[part 2 of 5: package /Cluster]
AUTOSAR XML (schema 4-3-0)
package /Cluster  (continued)
  can cluster HCP5_CANFD01: baudrate=500000, protocol-name=CAN, protocol-version=2.0, bus-off-recovery={bor-counter-l-1-to-l-2=1, bor-time-l-1=0.05, bor-time-l-2=0.2}, can-fd-baudrate=2000000  (continued)
    can physical channel CHNL: comm-connectors=CN_HCP5_CANFD01  (continued)
      frame BMC_HV_06_SOK_XIX_HCP5_CANFD01: id 0x16A95516, from BMC_HV, frame-length=12, can-addressing-mode=EXTENDED, can-frame-rx-behavior=CAN-FD, can-frame-tx-behavior=CAN-FD
        secured i pdu BMC_HV_06_SOK_XIX_HCP5_CANFD01:
          length=12
          authentication-props=SecureCommunicationAuthenticationProps_XIX_32
          freshness-props=SecureCommunicationFreshnessProps
          payload=PT_BMC_HV_06
          secure-communication-props={auth-data-freshness-length=0, auth-data-freshness-start-position=0, auth-info-tx-length=32, authentication-build-attempts=1, authentication-retries=4, data-id=535, freshness-value-id=2, freshness-value-length=64, freshness-value-tx-length=0}
          use-as-cryptographic-i-pdu=false
      frame BMC_HV_07_SOK_XIX_HCP5_CANFD01: id 0x16A95532, from BMC_HV, frame-length=12, can-addressing-mode=EXTENDED, can-frame-rx-behavior=CAN-FD, can-frame-tx-behavior=CAN-FD
        secured i pdu BMC_HV_07_SOK_XIX_HCP5_CANFD01:
          length=12
          authentication-props=SecureCommunicationAuthenticationProps_XIX_32
          freshness-props=SecureCommunicationFreshnessProps
          payload=PT_BMC_HV_07
          secure-communication-props={auth-data-freshness-length=0, auth-data-freshness-start-position=0, auth-info-tx-length=32, authentication-build-attempts=1, authentication-retries=4, data-id=730, freshness-value-id=3, freshness-value-length=64, freshness-value-tx-length=0}
          use-as-cryptographic-i-pdu=false
      frame BMC_HV_08_SOK_XIX_HCP5_CANFD01: id 0x1A555631, from BMC_HV, frame-length=48, can-addressing-mode=EXTENDED, can-frame-rx-behavior=CAN-FD, can-frame-tx-behavior=CAN-FD
        secured i pdu BMC_HV_08_SOK_XIX_HCP5_CANFD01:
          length=48
          authentication-props=SecureCommunicationAuthenticationProps_XIX_32
          freshness-props=SecureCommunicationFreshnessProps
          payload=PT_BMC_HV_08
          secure-communication-props={auth-data-freshness-length=0, auth-data-freshness-start-position=0, auth-info-tx-length=32, authentication-build-attempts=1, authentication-retries=4, data-id=731, freshness-value-id=4, freshness-value-length=64, freshness-value-tx-length=0}
          use-as-cryptographic-i-pdu=false
      frame BMC_HV_09_SOK_XIX_HCP5_CANFD01: id 0x12DD5593, from BMC_HV, frame-length=20, can-addressing-mode=EXTENDED, can-frame-rx-behavior=CAN-FD, can-frame-tx-behavior=CAN-FD
        secured i pdu BMC_HV_09_SOK_XIX_HCP5_CANFD01:
          length=20
          authentication-props=SecureCommunicationAuthenticationProps_XIX_32
          freshness-props=SecureCommunicationFreshnessProps
          payload=PT_BMC_HV_09
          secure-communication-props={auth-data-freshness-length=0, auth-data-freshness-start-position=0, auth-info-tx-length=32, authentication-build-attempts=1, authentication-retries=4, data-id=810, freshness-value-id=5, freshness-value-length=64, freshness-value-tx-length=0}
          use-as-cryptographic-i-pdu=false
      frame BMC_HV_14_SOK_XIX_HCP5_CANFD01: id 0x12DD55C4, from BMC_HV, frame-length=16, can-addressing-mode=STANDARD, can-frame-rx-behavior=CAN-FD, can-frame-tx-behavior=CAN-FD
        secured i pdu BMC_HV_14_SOK_XIX_HCP5_CANFD01:
          length=16
          authentication-props=SecureCommunicationAuthenticationProps_XIX_32
          freshness-props=SecureCommunicationFreshnessProps
          payload=PT_BMC_HV_14
          secure-communication-props={auth-data-freshness-length=0, auth-data-freshness-start-position=0, auth-info-tx-length=32, authentication-build-attempts=1, authentication-retries=4, data-id=846, freshness-value-id=6, freshness-value-length=64, freshness-value-tx-length=0}
          use-as-cryptographic-i-pdu=false
      frame Charisma_20_XIX_HCP5_CANFD01: id 0x1A55556D, to BMC_HV, frame-length=20, can-addressing-mode=EXTENDED, can-frame-rx-behavior=CAN-FD, can-frame-tx-behavior=CAN-FD
        pdu Charisma_20_XIX_HCP5_CANFD01: length=20, minimum-delay=0.05, transmission-mode-true-timing={cyclic-timing={time-offset=0, time-period=1}, event-controlled-timing={number-of-repetitions=0, repetition-period=0}}, unused-bit-pattern=0
          signal CHA_ReqPrgBms_XIX_Charisma_20_XIX_HCP5_CANFD01: start 12, 4 bit, little-endian, data-type-policy=OVERRIDE, i-signal-type=PRIMITIVE, init-value=0, base-type=BT_CHA_ReqPrgBms, compu-method=CM_CHA_ReqPrgBms, data-constr=DC_CHA_ReqPrgBms, transfer-property=TRIGGERED-ON-CHANGE-WITHOUT-REPETITION, to BMC_HV(timeout 5 s)  # Anforderung des Fahrprogramms seitens Charisma an das Batterie-Management-System
          signal CHA_ReqPrgEps_XIX_Charisma_20_XIX_HCP5_CANFD01: start 20, 4 bit, little-endian, data-type-policy=OVERRIDE, i-signal-type=PRIMITIVE, init-value=0, base-type=BT_CHA_ReqPrgEps, compu-method=CM_CHA_ReqPrgEps, data-constr=DC_CHA_ReqPrgEps, transfer-property=TRIGGERED-ON-CHANGE-WITHOUT-REPETITION  # Anforderung des Fahrprogramms seitens Charisma an die EPS-Lenkung.
          signal CHA_ReqPrgTqVect_XIX_Charisma_20_XIX_HCP5_CANFD01: start 28, 4 bit, little-endian, data-type-policy=OVERRIDE, i-signal-type=PRIMITIVE, init-value=0, base-type=BT_CHA_ReqPrgTqVect, compu-method=CM_CHA_ReqPrgTqVect, data-constr=DC_CHA_ReqPrgTqVect, transfer-property=TRIGGERED-ON-CHANGE-WITHOUT-REPETITION  # Anforderung des Fahrprogramms seitens Charisma an die Torque-Vectoring-Systeme (z.B. QSP, eTV, BTV)
          signal CHA_ReqPrgKl_XIX_Charisma_20_XIX_HCP5_CANFD01: start 32, 4 bit, little-endian, data-type-policy=OVERRIDE, i-signal-type=PRIMITIVE, init-value=0, base-type=BT_CHA_ReqPrgKl, compu-method=CM_CHA_ReqPrgKl, data-constr=DC_CHA_ReqPrgKl, transfer-property=TRIGGERED-ON-CHANGE-WITHOUT-REPETITION  # Anforderung des Fahrprogramms seitens Charisma an die Klima-Anlage
          signal CHA_ReqPrgDynTqCtrl_XIX_Charisma_20_XIX_HCP5_CANFD01: start 36, 4 bit, little-endian, data-type-policy=OVERRIDE, i-signal-type=PRIMITIVE, init-value=0, base-type=BT_CHA_ReqPrgDynTqCtrl, compu-method=CM_CHA_ReqPrgDynTqCtrl, data-constr=DC_CHA_ReqPrgDynTqCtrl, transfer-property=TRIGGERED-ON-CHANGE-WITHOUT-REPETITION  # Anforderung des Fahrprogramms seitens Charisma an Allradregelsysteme (z.B. quattro ultra und eQuattro)
          signal CHA_ReqPrgAcc_XIX_Charisma_20_XIX_HCP5_CANFD01: start 40, 4 bit, little-endian, data-type-policy=OVERRIDE, i-signal-type=PRIMITIVE, init-value=0, base-type=BT_CHA_ReqPrgAcc, compu-method=CM_CHA_ReqPrgAcc, data-constr=DC_CHA_ReqPrgAcc, transfer-property=TRIGGERED-ON-CHANGE-WITHOUT-REPETITION  # Anforderung des Fahrprogramms seitens Charisma an die Funktion ACC.
          signal CHA_ReqPrgRwb_XIX_Charisma_20_XIX_HCP5_CANFD01: start 44, 4 bit, little-endian, data-type-policy=OVERRIDE, i-signal-type=PRIMITIVE, init-value=0, base-type=BT_CHA_ReqPrgRwb, compu-method=CM_CHA_ReqPrgRwb, data-constr=DC_CHA_ReqPrgRwb, transfer-property=TRIGGERED-ON-CHANGE-WITHOUT-REPETITION  # Anforderung des Fahrprogramms seitens Charisma an die Funktion Reichweitenberechnung.
          signal CHA_ReqPrgHsp_XIX_Charisma_20_XIX_HCP5_CANFD01: start 48, 4 bit, little-endian, data-type-policy=OVERRIDE, i-signal-type=PRIMITIVE, init-value=0, base-type=BT_CHA_ReqPrgHsp, compu-method=CM_CHA_ReqPrgHsp, data-constr=DC_CHA_ReqPrgHsp, transfer-property=TRIGGERED-ON-CHANGE-WITHOUT-REPETITION  # Anforderung des Fahrprogramms seitens Charisma an die Heckspoiler-Steuerung. Nur in Porsche-Fahrzeugen gütlig.
          signal CHA_ReqPrgWarnBrk_XIX_Charisma_20_XIX_HCP5_CANFD01: start 52, 4 bit, little-endian, data-type-policy=OVERRIDE, i-signal-type=PRIMITIVE, init-value=0, base-type=BT_CHA_ReqPrgWarnBrk, compu-method=CM_CHA_ReqPrgWarnBrk, data-constr=DC_CHA_ReqPrgWarnBrk, transfer-property=TRIGGERED-ON-CHANGE-WITHOUT-REPETITION  # Anforderung des Fahrprogramms seitens Charisma an die Funktion Warn-Brems
          signal CHA_ReqPrgExtrLight_XIX_Charisma_20_XIX_HCP5_CANFD01: start 56, 4 bit, little-endian, data-type-policy=OVERRIDE, i-signal-type=PRIMITIVE, init-value=0, base-type=BT_CHA_ReqPrgExtrLight, compu-method=CM_CHA_ReqPrgExtrLight, data-constr=DC_CHA_ReqPrgExtrLight, transfer-property=TRIGGERED-ON-CHANGE-WITHOUT-REPETITION  # Anforderung des Fahrprogramms seitens Charisma an die Scheinwerfer-Funktionen.
          signal CHA_ReqPrgEsc_XIX_Charisma_20_XIX_HCP5_CANFD01: start 60, 4 bit, little-endian, data-type-policy=OVERRIDE, i-signal-type=PRIMITIVE, init-value=0, base-type=BT_CHA_ReqPrgEsc, compu-method=CM_CHA_ReqPrgEsc, data-constr=DC_CHA_ReqPrgEsc, transfer-property=TRIGGERED-ON-CHANGE-WITHOUT-REPETITION  # Anforderung des Fahrprogramms seitens Charisma an das ESC
          signal CHA_ReqPrgHdc_XIX_Charisma_20_XIX_HCP5_CANFD01: start 64, 4 bit, little-endian, data-type-policy=OVERRIDE, i-signal-type=PRIMITIVE, init-value=0, base-type=BT_CHA_ReqPrgHdc, compu-method=CM_CHA_ReqPrgHdc, data-constr=DC_CHA_ReqPrgHdc, transfer-property=TRIGGERED-ON-CHANGE-WITHOUT-REPETITION  # Anforderung des Fahrprogramms seitens Charisma an die Bergabfahrhilfe.
          signal CHA_ReqPrgLC_XIX_Charisma_20_XIX_HCP5_CANFD01: start 68, 4 bit, little-endian, data-type-policy=OVERRIDE, i-signal-type=PRIMITIVE, init-value=0, base-type=BT_CHA_ReqPrgLC, compu-method=CM_CHA_ReqPrgLC, data-constr=DC_CHA_ReqPrgLC, transfer-property=TRIGGERED-ON-CHANGE-WITHOUT-REPETITION  # Anforderung des Fahrprogramms seitens Charisma an die Funktion Niveauregulierung.
          signal CHA_ReqPrgAcvChassis_XIX_Charisma_20_XIX_HCP5_CANFD01: start 72, 4 bit, little-endian, data-type-policy=OVERRIDE, i-signal-type=PRIMITIVE, init-value=0, base-type=BT_CHA_ReqPrgAcvChassis, compu-method=CM_CHA_ReqPrgAcvChassis, data-constr=DC_CHA_ReqPrgAcvChassis, transfer-property=TRIGGERED-ON-CHANGE-WITHOUT-REPETITION  # Anforderung des Fahrprogramms seitens Charisma an das aktive Fahrwerk
          signal CHA_ReqPrgDC_XIX_Charisma_20_XIX_HCP5_CANFD01: start 76, 4 bit, little-endian, data-type-policy=OVERRIDE, i-signal-type=PRIMITIVE, init-value=0, base-type=BT_CHA_ReqPrgDC, compu-method=CM_CHA_ReqPrgDC, data-constr=DC_CHA_ReqPrgDC, transfer-property=TRIGGERED-ON-CHANGE-WITHOUT-REPETITION  # Anforderung des Fahrprogramms seitens Charisma an die Dämpferregelung
          signal CHA_ReqPrgDt_XIX_Charisma_20_XIX_HCP5_CANFD01: start 84, 4 bit, little-endian, data-type-policy=OVERRIDE, i-signal-type=PRIMITIVE, init-value=0, base-type=BT_CHA_ReqPrgDt, compu-method=CM_CHA_ReqPrgDt, data-constr=DC_CHA_ReqPrgDt, transfer-property=TRIGGERED-ON-CHANGE-WITHOUT-REPETITION  # Anforderung des Fahrprogramms seitens Charisma an die Antriebsfunktionen Motor und Getriebe.
          signal CHA_ReqPrgRcp_XIX_Charisma_20_XIX_HCP5_CANFD01: start 88, 4 bit, little-endian, data-type-policy=OVERRIDE, i-signal-type=PRIMITIVE, init-value=0, base-type=BT_CHA_ReqPrgRcp, compu-method=CM_CHA_ReqPrgRcp, data-constr=DC_CHA_ReqPrgRcp, transfer-property=TRIGGERED-ON-CHANGE-WITHOUT-REPETITION  # Anforderung des Fahrprogramms seitens Charisma an Funktion Rekuperation. Nur in Porsche-Fahrzeugen gütlig.
          signal CHA_ReqPrgIntrLight_XIX_Charisma_20_XIX_HCP5_CANFD01: start 92, 4 bit, little-endian, data-type-policy=OVERRIDE, i-signal-type=PRIMITIVE, init-value=0, base-type=BT_CHA_ReqPrgIntrLight, compu-method=CM_CHA_ReqPrgIntrLight, data-constr=DC_CHA_ReqPrgIntrLight, transfer-property=TRIGGERED-ON-CHANGE-WITHOUT-REPETITION  # Anforderung des Fahrprogramms seitens Charisma an die Innenbeleuchtung
          signal CHA_ReqPrgPreCrash_XIX_Charisma_20_XIX_HCP5_CANFD01: start 96, 4 bit, little-endian, data-type-policy=OVERRIDE, i-signal-type=PRIMITIVE, init-value=0, base-type=BT_CHA_ReqPrgPreCrash, compu-method=CM_CHA_ReqPrgPreCrash, data-constr=DC_CHA_ReqPrgPreCrash, transfer-property=TRIGGERED-ON-CHANGE-WITHOUT-REPETITION  # Anforderung des Fahrprogramms seitens Charisma an die PreCrash-Funktion.
          signal CHA_ReqPrgCMM_XIX_Charisma_20_XIX_HCP5_CANFD01: start 100, 4 bit, little-endian, data-type-policy=OVERRIDE, i-signal-type=PRIMITIVE, init-value=0, base-type=BT_CHA_ReqPrgCMM, compu-method=CM_CHA_ReqPrgCMM, data-constr=DC_CHA_ReqPrgCMM, transfer-property=TRIGGERED-ON-CHANGE-WITHOUT-REPETITION  # Requested Charisma-programm directly to ChassisModeManager.
          signal CHA_ReqPrgExtrSound_XIX_Charisma_20_XIX_HCP5_CANFD01: start 104, 4 bit, little-endian, data-type-policy=OVERRIDE, i-signal-type=PRIMITIVE, init-value=0, base-type=BT_CHA_ReqPrgExtrSound, compu-method=CM_CHA_ReqPrgExtrSound, data-constr=DC_CHA_ReqPrgExtrSound, transfer-property=TRIGGERED-ON-CHANGE-WITHOUT-REPETITION  # Requested Charisma-programm to exterior-sound-systems.
          signal CHA_ReqPrgIntrSound_XIX_Charisma_20_XIX_HCP5_CANFD01: start 108, 4 bit, little-endian, data-type-policy=OVERRIDE, i-signal-type=PRIMITIVE, init-value=0, base-type=BT_CHA_ReqPrgIntrSound, compu-method=CM_CHA_ReqPrgIntrSound, data-constr=DC_CHA_ReqPrgIntrSound, transfer-property=TRIGGERED-ON-CHANGE-WITHOUT-REPETITION  # Requested Charisma-programm to interior-sound-systems.
          signal CHA_CurProf_XIX_Charisma_20_XIX_HCP5_CANFD01: start 112, 5 bit, little-endian, data-type-policy=OVERRIDE, i-signal-type=PRIMITIVE, init-value=0, base-type=BT_CHA_CurProf, compu-method=CM_CHA_CurProf, data-constr=DC_CHA_CurProf, transfer-property=TRIGGERED-ON-CHANGE-WITHOUT-REPETITION  # Ausgabe des aktuell selektierten Charisma Fahrprofils
          signal CHA_ProfChanged_XIX_Charisma_20_XIX_HCP5_CANFD01: start 117, 1 bit, little-endian, data-type-policy=OVERRIDE, i-signal-type=PRIMITIVE, init-value=0, base-type=BT_CHA_ProfChanged, compu-method=CM_CHA_ProfChanged, data-constr=DC_CHA_ProfChanged, transfer-property=TRIGGERED-ON-CHANGE-WITHOUT-REPETITION  # Triggersignal für die Änderung bzw. Neuauswahl des aktivierten Charisma Fahrprofils
          signal CHA_StCurProfDft_XIX_Charisma_20_XIX_HCP5_CANFD01: start 118, 2 bit, little-endian, data-type-policy=OVERRIDE, i-signal-type=PRIMITIVE, init-value=0, base-type=BT_CHA_StCurProfDft, compu-method=CM_CHA_StCurProfDft, data-constr=DC_CHA_StCurProfDft, transfer-property=TRIGGERED-ON-CHANGE-WITHOUT-REPETITION  # Signal indicates if the current Charisma-profile
          signal CHA_ReqPrgDispSetup_XIX_Charisma_20_XIX_HCP5_CANFD01: start 120, 4 bit, little-endian, data-type-policy=OVERRIDE, i-signal-type=PRIMITIVE, init-value=0, base-type=BT_CHA_ReqPrgDispSetup, compu-method=CM_CHA_ReqPrgDispSetup, data-constr=DC_CHA_ReqPrgDispSetup, transfer-property=TRIGGERED-ON-CHANGE-WITHOUT-REPETITION  # Requested Charisma-programm to Kombi to change display setup.
          signal CHA_ReqPrgVLim_XIX_Charisma_20_XIX_HCP5_CANFD01: start 124, 4 bit, little-endian, data-type-policy=OVERRIDE, i-signal-type=PRIMITIVE, init-value=0, base-type=BT_CHA_ReqPrgVLim, compu-method=CM_CHA_ReqPrgVLim, data-constr=DC_CHA_ReqPrgVLim, transfer-property=TRIGGERED-ON-CHANGE-WITHOUT-REPETITION  # Requested Charisma-programm directly to the speedlimiter.
          signal CHA_FlgGlbFallBkIdc_XIX_Charisma_20_XIX_HCP5_CANFD01: start 128, 1 bit, little-endian, data-type-policy=OVERRIDE, i-signal-type=PRIMITIVE, init-value=0, base-type=BT_CHA_FlgGlbFallBkIdc, compu-method=CM_CHA_FlgGlbFallBkIdc, data-constr=DC_CHA_FlgGlbFallBkIdc, transfer-property=TRIGGERED-ON-CHANGE-WITHOUT-REPETITION  # Rueckmeldung der Funktion Charisma, ob ein Teilnehmer einen globalen Rueckfall gemeldet bzw. angefordert hat. Das Signal gibt keine Aussage darueber , ob in Folge der Teilnehmer-Meldung auch ein Profil-Wechsel oder eine -Sperrung durchgefuehrt wurde.
          signal CHA_ReqPrgAcvStg_XIX_Charisma_20_XIX_HCP5_CANFD01: start 129, 4 bit, little-endian, data-type-policy=OVERRIDE, i-signal-type=PRIMITIVE, init-value=0, base-type=BT_CHA_ReqPrgAcvStg, compu-method=CM_CHA_ReqPrgAcvStg, data-constr=DC_CHA_ReqPrgAcvStg, transfer-property=TRIGGERED-ON-CHANGE-WITHOUT-REPETITION  # Anforderung des Fahrprogramms seitens Charisma an die Funktion vernetzte Lenkung
          signal CHA_FlgEndOfList_XIX_Charisma_20_XIX_HCP5_CANFD01: start 133, 2 bit, little-endian, data-type-policy=OVERRIDE, i-signal-type=PRIMITIVE, init-value=0, base-type=BT_CHA_FlgEndOfList, compu-method=CM_CHA_FlgEndOfList, data-constr=DC_CHA_FlgEndOfList, transfer-property=TRIGGERED-ON-CHANGE-WITHOUT-REPETITION  # Charisma provides the information to the HMI, if the driver selects the first or the last profile in the profile-list. The signal is sent with the correspondig list-end for a certain-time when the driver activates or reactivates a profile at the end of the list.
          signal CHA_ReqPrgHdUpDisp_XIX_Charisma_20_XIX_HCP5_CANFD01: start 135, 4 bit, little-endian, data-type-policy=OVERRIDE, i-signal-type=PRIMITIVE, init-value=0, base-type=BT_CHA_ReqPrgHdUpDisp, compu-method=CM_CHA_ReqPrgHdUpDisp, data-constr=DC_CHA_ReqPrgHdUpDisp, transfer-property=TRIGGERED-ON-CHANGE-WITHOUT-REPETITION  # Requested Charisma-programm to headup-display to change it's layout.
      frame ClampControl_01_XIX_HCP5_CANFD01: id 0x12DD54FE, to BMC_HV, frame-length=8, can-addressing-mode=EXTENDED, can-frame-rx-behavior=CAN-FD, can-frame-tx-behavior=CAN-FD
        pdu ClampControl_01_XIX_HCP5_CANFD01: length=8, minimum-delay=0.01, transmission-mode-true-timing={cyclic-timing={time-offset=0, time-period=0.1}, event-controlled-timing={number-of-repetitions=0, repetition-period=0}}, unused-bit-pattern=0
          signal ClampControl_01_CRC_XIX_ClampControl_01_XIX_HCP5_CANFD01: start 0, 8 bit, little-endian, data-type-policy=OVERRIDE, i-signal-type=PRIMITIVE, init-value=0, base-type=BT_ClampControl_01_CRC, compu-method=CM_ClampControl_01_CRC, data-constr=DC_ClampControl_01_CRC, transfer-property=PENDING  # Für MLB: Berechnung siehe Lastenheft "Kommunikationsabsicherung für FlexRay und CAN" Ab MQB und MLBevo: Berechnung siehe Lastenheft "End-to-End Kommunikationsabsicherung" Endwerte siehe Begleitdokument "S-PDU Kennungsfolgen"
          signal ClampControl_01_BZ_XIX_ClampControl_01_XIX_HCP5_CANFD01: start 8, 4 bit, little-endian, data-type-policy=OVERRIDE, i-signal-type=PRIMITIVE, init-value=0, base-type=BT_ClampControl_01_BZ, compu-method=CM_ClampControl_01_BZ, data-constr=DC_ClampControl_01_BZ, transfer-property=PENDING  # 4bit Botschaftszähler, wird mit jeder Sendebotschaft inkrementiert
          signal KST_Warn_P1_ZAT_def_XIX_ClampControl_01_XIX_HCP5_CANFD01: start 12, 1 bit, little-endian, data-type-policy=OVERRIDE, i-signal-type=PRIMITIVE, init-value=0, base-type=BT_KST_Warn_P1_ZAT_def, compu-method=CM_KST_Warn_P1_ZAT_def, data-constr=DC_KST_Warn_P1_ZAT_def, transfer-property=TRIGGERED-ON-CHANGE-WITHOUT-REPETITION  # Kombi Prio Warnung Klemmensteuerung Zündschloß defekt, Service aufsuchen!
          signal KST_Warn_P2_ZAT_def_XIX_ClampControl_01_XIX_HCP5_CANFD01: start 13, 1 bit, little-endian, data-type-policy=OVERRIDE, i-signal-type=PRIMITIVE, init-value=0, base-type=BT_KST_Warn_P2_ZAT_def, compu-method=CM_KST_Warn_P2_ZAT_def, data-constr=DC_KST_Warn_P2_ZAT_def, transfer-property=TRIGGERED-ON-CHANGE-WITHOUT-REPETITION  # Kombi Prio Warnung Klemmensteuerung Zündschloß defekt!
          signal KST_Deaktivierungs_Trigger_XIX_ClampControl_01_XIX_HCP5_CANFD01: start 14, 2 bit, little-endian, data-type-policy=OVERRIDE, i-signal-type=PRIMITIVE, init-value=0, base-type=BT_KST_Deaktivierungs_Trigger, compu-method=CM_KST_Deaktivierungs_Trigger, data-constr=DC_KST_Deaktivierungs_Trigger, transfer-property=TRIGGERED-ON-CHANGE-WITHOUT-REPETITION  # Ausgabe des Deaktivierungstriggers für Funktionen mit Goodbye-Szenario zur Unterscheidung zwischen manueller und automatischer Deaktivierung bei Fzg.-Verlassen
          signal KST_Kl_S_XIX_ClampControl_01_XIX_HCP5_CANFD01: start 16, 1 bit, little-endian, data-type-policy=OVERRIDE, i-signal-type=PRIMITIVE, init-value=0, base-type=BT_KST_Kl_S, compu-method=CM_KST_Kl_S, data-constr=DC_KST_Kl_S, transfer-property=TRIGGERED-ON-CHANGE-WITHOUT-REPETITION  # Klemme S: S-Kontakt (Schluessel steckt)
          signal KST_KL_15_XIX_ClampControl_01_XIX_HCP5_CANFD01: start 17, 1 bit, little-endian, data-type-policy=OVERRIDE, i-signal-type=PRIMITIVE, init-value=0, base-type=BT_KST_KL_15, compu-method=CM_KST_KL_15, data-constr=DC_KST_KL_15, transfer-property=TRIGGERED-ON-CHANGE-WITHOUT-REPETITION, to BMC_HV(timeout 1 s)  # Klemme 15: Zuendung (SW-Kl.15)
          signal KST_Kl_50_Startanforderung_XIX_ClampControl_01_XIX_HCP5_CANFD01: start 18, 1 bit, little-endian, data-type-policy=OVERRIDE, i-signal-type=PRIMITIVE, init-value=0, base-type=BT_KST_Kl_50_Startanforderung, compu-method=CM_KST_Kl_50_Startanforderung, data-constr=DC_KST_Kl_50_Startanforderung, transfer-property=TRIGGERED-ON-CHANGE-WITHOUT-REPETITION  # Klemme 50: Startwunsch Fahrer
          signal KST_Sonderzustand_Status_XIX_ClampControl_01_XIX_HCP5_CANFD01: start 19, 2 bit, little-endian, data-type-policy=OVERRIDE, i-signal-type=PRIMITIVE, init-value=0, base-type=BT_KST_Sonderzustand_Status, invalid-value=Invalid_KST_Sonderzustand_Status_XIX_ClampControl_01_XIX_HCP5_CANFD01:3, compu-method=CM_KST_Sonderzustand_Status, data-constr=DC_KST_Sonderzustand_Status, transfer-property=TRIGGERED-ON-CHANGE-WITHOUT-REPETITION  # Hiermit wird signalisiert, dass eine Sonderfunktion aktiv ist und die Klemme 15 durch diese angefordert wurde bzw. ein Übergang von Sonderfunktionen stattfindet
          signal KST_Ausstiegswunsch_Status_XIX_ClampControl_01_XIX_HCP5_CANFD01: start 21, 1 bit, little-endian, data-type-policy=OVERRIDE, i-signal-type=PRIMITIVE, init-value=0, base-type=BT_KST_Ausstiegswunsch_Status, compu-method=CM_KST_Ausstiegswunsch_Status, data-constr=DC_KST_Ausstiegswunsch_Status, transfer-property=TRIGGERED-ON-CHANGE-WITHOUT-REPETITION  # Ausstiegswunsch über den Funktionen mit Goodbye-Szenario zentral getriggert werden können.
          signal KST_BulbCheckReq_XIX_ClampControl_01_XIX_HCP5_CANFD01: start 23, 1 bit, little-endian, data-type-policy=OVERRIDE, i-signal-type=PRIMITIVE, init-value=0, base-type=BT_KST_BulbCheckReq, compu-method=CM_KST_BulbCheckReq, data-constr=DC_KST_BulbCheckReq, transfer-property=TRIGGERED-ON-CHANGE-WITHOUT-REPETITION  # Signal fordert eine Lampenaufprüfung (Bulb Check) an.
          signal KST_Kl_X_XIX_ClampControl_01_XIX_HCP5_CANFD01: start 24, 1 bit, little-endian, data-type-policy=OVERRIDE, i-signal-type=PRIMITIVE, init-value=0, base-type=BT_KST_Kl_X, compu-method=CM_KST_Kl_X, data-constr=DC_KST_Kl_X, transfer-property=TRIGGERED-ON-CHANGE-WITHOUT-REPETITION  # Ausgabe der Klemme 75 aus Kompatibilitätsgründen für COP-Übernahmen aus MEB.
          signal KST_Ausparken_Betrieb_XIX_ClampControl_01_XIX_HCP5_CANFD01: start 25, 1 bit, little-endian, data-type-policy=OVERRIDE, i-signal-type=PRIMITIVE, init-value=0, base-type=BT_KST_Ausparken_Betrieb, compu-method=CM_KST_Ausparken_Betrieb, data-constr=DC_KST_Ausparken_Betrieb, transfer-property=TRIGGERED-ON-CHANGE-WITHOUT-REPETITION  # Anforderung zur erneuten Lampenaufprüfung und Anzeige von Warnhinweisen nach einem pilotierten Ausparkvorgang (Trigger: fallende Flanke)
          signal KST_Fahrerhinweis_1_XIX_ClampControl_01_XIX_HCP5_CANFD01: start 26, 1 bit, little-endian, data-type-policy=OVERRIDE, i-signal-type=PRIMITIVE, init-value=0, base-type=BT_KST_Fahrerhinweis_1, compu-method=CM_KST_Fahrerhinweis_1, data-constr=DC_KST_Fahrerhinweis_1, transfer-property=TRIGGERED-ON-CHANGE-WITHOUT-REPETITION  # Signalisierung Fahrerhinweis 1 der Klemmensteuerung an das Kombi
          signal KST_Fahrerhinweis_2_XIX_ClampControl_01_XIX_HCP5_CANFD01: start 27, 1 bit, little-endian, data-type-policy=OVERRIDE, i-signal-type=PRIMITIVE, init-value=0, base-type=BT_KST_Fahrerhinweis_2, compu-method=CM_KST_Fahrerhinweis_2, data-constr=DC_KST_Fahrerhinweis_2, transfer-property=TRIGGERED-ON-CHANGE-WITHOUT-REPETITION  # Signalisierung Fahrerhinweis 2 der Klemmensteuerung an das Kombi
          signal KST_Fahrerhinweis_3_XIX_ClampControl_01_XIX_HCP5_CANFD01: start 28, 1 bit, little-endian, data-type-policy=OVERRIDE, i-signal-type=PRIMITIVE, init-value=0, base-type=BT_KST_Fahrerhinweis_3, compu-method=CM_KST_Fahrerhinweis_3, data-constr=DC_KST_Fahrerhinweis_3, transfer-property=TRIGGERED-ON-CHANGE-WITHOUT-REPETITION  # Signalisierung Fahrerhinweis 3 der Klemmensteuerung an das Kombi
          signal KST_Fahrerhinweis_4_XIX_ClampControl_01_XIX_HCP5_CANFD01: start 29, 1 bit, little-endian, data-type-policy=OVERRIDE, i-signal-type=PRIMITIVE, init-value=0, base-type=BT_KST_Fahrerhinweis_4, compu-method=CM_KST_Fahrerhinweis_4, data-constr=DC_KST_Fahrerhinweis_4, transfer-property=TRIGGERED-ON-CHANGE-WITHOUT-REPETITION  # Signalisierung Fahrerhinweis 4 der Klemmensteuerung an das Kombi
          signal KST_Fahrerhinweis_5_XIX_ClampControl_01_XIX_HCP5_CANFD01: start 30, 1 bit, little-endian, data-type-policy=OVERRIDE, i-signal-type=PRIMITIVE, init-value=0, base-type=BT_KST_Fahrerhinweis_5, compu-method=CM_KST_Fahrerhinweis_5, data-constr=DC_KST_Fahrerhinweis_5, transfer-property=TRIGGERED-ON-CHANGE-WITHOUT-REPETITION  # Anzeigesignal für RemoteStart
          signal KST_Fahrerhinweis_6_XIX_ClampControl_01_XIX_HCP5_CANFD01: start 31, 1 bit, little-endian, data-type-policy=OVERRIDE, i-signal-type=PRIMITIVE, init-value=0, base-type=BT_KST_Fahrerhinweis_6, compu-method=CM_KST_Fahrerhinweis_6, data-constr=DC_KST_Fahrerhinweis_6, transfer-property=TRIGGERED-ON-CHANGE-WITHOUT-REPETITION  # Signal aktiviert die Kombi-Anzeigeinstrumente (Drehzahl, Tankinhalt, Kühlmitteltemperatur) während aktiviertem RemoteStart-Betrieb
          signal KST_Txt_Panikabschaltung_XIX_ClampControl_01_XIX_HCP5_CANFD01: start 34, 1 bit, little-endian, data-type-policy=OVERRIDE, i-signal-type=PRIMITIVE, init-value=0, base-type=BT_KST_Txt_Panikabschaltung, compu-method=CM_KST_Txt_Panikabschaltung, data-constr=DC_KST_Txt_Panikabschaltung, transfer-property=TRIGGERED-ON-CHANGE-WITHOUT-REPETITION  # Text: 'Notabschaltung''
          signal KST_Anf_Klemmenfreigabe_ELV_XIX_ClampControl_01_XIX_HCP5_CANFD01: start 41, 1 bit, little-endian, data-type-policy=OVERRIDE, i-signal-type=PRIMITIVE, init-value=0, base-type=BT_KST_Anf_Klemmenfreigabe_ELV, compu-method=CM_KST_Anf_Klemmenfreigabe_ELV, data-constr=DC_KST_Anf_Klemmenfreigabe_ELV, transfer-property=PENDING  # Klemmensteuerung fordert Klemmen-Freigabe durch die ELV an.
          signal KST_aut_Abschaltung_Zuendung_XIX_ClampControl_01_XIX_HCP5_CANFD01: start 42, 1 bit, little-endian, data-type-policy=OVERRIDE, i-signal-type=PRIMITIVE, init-value=0, base-type=BT_KST_aut_Abschaltung_Zuendung, compu-method=CM_KST_aut_Abschaltung_Zuendung, data-constr=DC_KST_aut_Abschaltung_Zuendung, transfer-property=TRIGGERED-ON-CHANGE-WITHOUT-REPETITION  # Falls bei eingeschalteter Zündung das Abblendlicht aktiv war, muss nach der automatischen Abschaltung der Kl_15 & Kl_S, dass Standlicht aktiv bleiben. Das Signal sendet die Information, dass eine automatische Abschaltung der Kl_15 und Kl_S erfogt.
          signal KST_StPtAcvReq_XIX_ClampControl_01_XIX_HCP5_CANFD01: start 43, 2 bit, little-endian, data-type-policy=OVERRIDE, i-signal-type=PRIMITIVE, init-value=0, base-type=BT_KST_StPtAcvReq, compu-method=CM_KST_StPtAcvReq, data-constr=DC_KST_StPtAcvReq, transfer-property=TRIGGERED-ON-CHANGE-WITHOUT-REPETITION  # ZAT-activation-demand
          signal KST_StPtDeacReq_XIX_ClampControl_01_XIX_HCP5_CANFD01: start 45, 1 bit, little-endian, data-type-policy=OVERRIDE, i-signal-type=PRIMITIVE, init-value=0, base-type=BT_KST_StPtDeacReq, compu-method=CM_KST_StPtDeacReq, data-constr=DC_KST_StPtDeacReq, transfer-property=TRIGGERED-ON-CHANGE-WITHOUT-REPETITION  # Anforderung Deaktivierung des Antriebsstrangs durch Klemmensteuerung
          signal KST_ZAT_betaetigt_XIX_ClampControl_01_XIX_HCP5_CANFD01: start 46, 1 bit, little-endian, data-type-policy=OVERRIDE, i-signal-type=PRIMITIVE, init-value=0, base-type=BT_KST_ZAT_betaetigt, compu-method=CM_KST_ZAT_betaetigt, data-constr=DC_KST_ZAT_betaetigt, transfer-property=TRIGGERED-ON-CHANGE-WITHOUT-REPETITION  # Zündanlass-Taster (ZAT) betätigt
          signal KST_ComfortReadyStatus_XIX_ClampControl_01_XIX_HCP5_CANFD01: start 47, 1 bit, little-endian, data-type-policy=OVERRIDE, i-signal-type=PRIMITIVE, init-value=0, base-type=BT_KST_ComfortReadyStatus, compu-method=CM_KST_ComfortReadyStatus, data-constr=DC_KST_ComfortReadyStatus, transfer-property=TRIGGERED-ON-CHANGE-WITHOUT-REPETITION  # Zustand des ComfortReadyStatus über den Komfortfunktionen aktiviert werden können.
          signal KST_Sonderzustand_Anforderung_XIX_ClampControl_01_XIX_HCP5_CANFD01: start 48, 5 bit, little-endian, data-type-policy=OVERRIDE, i-signal-type=PRIMITIVE, init-value=0, base-type=BT_KST_Sonderzustand_Anforderung, invalid-value=Invalid_KST_Sonderzustand_Anforderung_XIX_ClampControl_01_XIX_HCP5_CANFD01:31, compu-method=CM_KST_Sonderzustand_Anforderung, data-constr=DC_KST_Sonderzustand_Anforderung, transfer-property=TRIGGERED-ON-CHANGE-WITHOUT-REPETITION  # Hiermit wird die aktive bzw. aktuell angeforderte (s. KST_Sonderzustand_Status) Sonderfunktion identifiziert
          signal KST_WFS_Fahrfreigabe_Anforderung_XIX_ClampControl_01_XIX_HCP5_CANFD01: start 53, 2 bit, little-endian, data-type-policy=OVERRIDE, i-signal-type=PRIMITIVE, init-value=0, base-type=BT_KST_WFS_Fahrfreigabe_Anforderung, compu-method=CM_KST_WFS_Fahrfreigabe_Anforderung, data-constr=DC_KST_WFS_Fahrfreigabe_Anforderung, transfer-property=TRIGGERED-ON-CHANGE-WITHOUT-REPETITION  # Hiermit wird den Wegfahrsperren-Teilnehmern signalisiert welche Art der Fahrfreigabe von der anfordernden Sonderfunktion benötigt wird
      frame DAAP_Funkt_Req_MC_FD_XIX_HCP5_CANFD01: id 0x1C413FDD, to BMC_HV, frame-length=8, can-addressing-mode=EXTENDED, can-frame-rx-behavior=CAN-FD, can-frame-tx-behavior=CAN-FD
        n pdu DAAP_Funkt_Req_MC_FD_XIX_HCP5_CANFD01: length=8
      frame DAAP_Hybrid_01_Req_FD_XIX_HCP5_CANFD01: id 0x1C403F7B, to BMC_HV, frame-length=64, can-addressing-mode=EXTENDED, can-frame-rx-behavior=CAN-FD, can-frame-tx-behavior=CAN-FD
        n pdu DAAP_Hybrid_01_Req_FD_XIX_HCP5_CANFD01: length=64
      frame DAAP_Hybrid_01_Resp_FD_XIX_HCP5_CANFD01: id 0x1C423F7B, from BMC_HV, frame-length=64, can-addressing-mode=EXTENDED, can-frame-rx-behavior=CAN-FD, can-frame-tx-behavior=CAN-FD
        n pdu DAAP_Hybrid_01_Resp_FD_XIX_HCP5_CANFD01: length=64
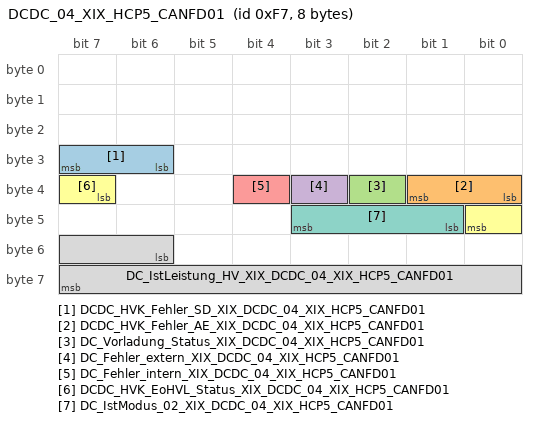
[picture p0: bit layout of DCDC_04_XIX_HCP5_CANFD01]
      frame DCDC_04_XIX_HCP5_CANFD01: id 0xF7, to BMC_HV, frame-length=8, can-addressing-mode=STANDARD, can-frame-rx-behavior=CAN-FD, can-frame-tx-behavior=CAN-FD
        pdu DCDC_04_XIX_HCP5_CANFD01: length=8, transmission-mode-true-timing=cyclic-timing={time-offset=0, time-period=0.01}, unused-bit-pattern=0
          signal DCDC_HVK_Fehler_SD_XIX_DCDC_04_XIX_HCP5_CANFD01: start 30, 2 bit, little-endian, data-type-policy=OVERRIDE, i-signal-type=PRIMITIVE, init-value=3, base-type=BT_DCDC_HVK_Fehler_SD, invalid-value=Invalid_DCDC_HVK_Fehler_SD_XIX_DCDC_04_XIX_HCP5_CANFD01:2, compu-method=CM_DCDC_HVK_Fehler_SD, data-constr=DC_DCDC_HVK_Fehler_SD, transfer-property=PENDING  # Status Service Disconnect an DC/DC-Wandler
          signal DCDC_HVK_Fehler_AE_XIX_DCDC_04_XIX_HCP5_CANFD01: start 32, 2 bit, little-endian, data-type-policy=OVERRIDE, i-signal-type=PRIMITIVE, init-value=3, base-type=BT_DCDC_HVK_Fehler_AE, compu-method=CM_DCDC_HVK_Fehler_AE, data-constr=DC_DCDC_HVK_Fehler_AE, transfer-property=PENDING  # Fehlerstatus aktive Entladung DC/DC-Wandler. In PPE: Status Aktive Entladung IPB (Integrated Power Box)
          signal DC_Vorladung_Status_XIX_DCDC_04_XIX_HCP5_CANFD01: start 34, 1 bit, little-endian, data-type-policy=OVERRIDE, i-signal-type=PRIMITIVE, init-value=0, base-type=BT_DC_Vorladung_Status, compu-method=CM_DC_Vorladung_Status, data-constr=DC_DC_Vorladung_Status, transfer-property=PENDING  # Status der ZK-Vorladung: =0, nicht_abgeschlossen =1, abgeschlossen DCDC-Wandler gibt Empfehlung für schließen der Schützen. HVK/BMS prüft die ZK-Spannung und entscheidet ob die Schütze geschlossen werden können.
          signal DC_Fehler_extern_XIX_DCDC_04_XIX_HCP5_CANFD01: start 35, 1 bit, little-endian, data-type-policy=OVERRIDE, i-signal-type=PRIMITIVE, init-value=0, base-type=BT_DC_Fehler_extern, invalid-value=Invalid_DC_Fehler_extern_XIX_DCDC_04_XIX_HCP5_CANFD01:1, compu-method=CM_DC_Fehler_extern, data-constr=DC_DC_Fehler_extern, transfer-property=PENDING  # Fehler/Abschaltung: DC/DC-Wandler ist aufgrund einer Umgebungsbedingung (z.B. HV-Spannung, NV-Spannung Kühlmitteltemperatur oder Systemfehler (ZK-Vorladung) ) nicht in der Lage geforderten Regelbetrieb einzuhalten.
          signal DC_Fehler_intern_XIX_DCDC_04_XIX_HCP5_CANFD01: start 36, 1 bit, little-endian, data-type-policy=OVERRIDE, i-signal-type=PRIMITIVE, init-value=0, base-type=BT_DC_Fehler_intern, compu-method=CM_DC_Fehler_intern, data-constr=DC_DC_Fehler_intern, transfer-property=PENDING  # Fehler: DC/DC-Wandler ist aufgrund eines internen Hardware-Fehlers abgeschaltet
          signal DCDC_HVK_EoHVL_Status_XIX_DCDC_04_XIX_HCP5_CANFD01: start 39, 2 bit, little-endian, data-type-policy=OVERRIDE, i-signal-type=PRIMITIVE, init-value=0, base-type=BT_DCDC_HVK_EoHVL_Status, invalid-value=Invalid_DCDC_HVK_EoHVL_Status_XIX_DCDC_04_XIX_HCP5_CANFD01:3, compu-method=CM_DCDC_HVK_EoHVL_Status, data-constr=DC_DCDC_HVK_EoHVL_Status, transfer-property=PENDING  # Erkennung einer offenen HV-Leitung (EoHVL), bewertet anhand einer Spannungsgrenze.
          signal DC_IstModus_02_XIX_DCDC_04_XIX_HCP5_CANFD01: start 41, 3 bit, little-endian, data-type-policy=OVERRIDE, i-signal-type=PRIMITIVE, init-value=7, base-type=BT_DC_IstModus_02, invalid-value=Invalid_DC_IstModus_02_XIX_DCDC_04_XIX_HCP5_CANFD01:5, compu-method=CM_DC_IstModus_02, data-constr=DC_DC_IstModus_02, transfer-property=PENDING  # aktuelle Betriebsart des DC/DC Wandlers; 0: Standby; Kommunikation aktiv 1: HV_On_Vorladen 2: Tiefsetzen 3: Hochsetzen 4: Pruefimpuls_12V 5: interner Fehler DC/DC-Wandler / angeforderter Sollmodus kann nicht eingestellt werden 6: reserve 7: Initialisierung
          signal DC_IstLeistung_HV_XIX_DCDC_04_XIX_HCP5_CANFD01: start 54, 10 bit, little-endian, data-type-policy=OVERRIDE, i-signal-type=PRIMITIVE, init-value=1022, base-type=BT_DC_IstLeistung_HV, invalid-value=Invalid_DC_IstLeistung_HV_XIX_DCDC_04_XIX_HCP5_CANFD01:1023, compu-method=CM_DC_IstLeistung_HV, data-constr=DC_DC_IstLeistung_HV, unit=Unit_Unit_Watt, transfer-property=PENDING, to BMC_HV(timeout 0.5 s)  # Aktuelle Ist-Leistung des Bordnetzwandlers auf der HV-Seite. Tiefsetzen - positiv Hochsetzen- negativ
      frame DCDC_NV_CALID_XIX_HCP5_CANFD01: id 0x1A5556B4, to BMC_HV, frame-length=16, can-addressing-mode=EXTENDED, can-frame-rx-behavior=CAN-FD, can-frame-tx-behavior=CAN-FD
        pdu DCDC_NV_CALID_XIX_HCP5_CANFD01: length=16, transmission-mode-true-timing=cyclic-timing={time-offset=0, time-period=1}, unused-bit-pattern=0
          signal DCDC_NV_CALID_Index_01_XIX_DCDC_NV_CALID_XIX_HCP5_CANFD01: start 0, 8 bit, little-endian, data-type-policy=OVERRIDE, i-signal-type=PRIMITIVE, init-value=63, base-type=BT_DCDC_NV_CALID_Index_01, compu-method=CM_DCDC_NV_CALID_Index_01, data-constr=DC_DCDC_NV_CALID_Index_01, transfer-property=PENDING, to BMC_HV(timeout 5 s)  # Calibration Identification
          signal DCDC_NV_CALID_Index_02_XIX_DCDC_NV_CALID_XIX_HCP5_CANFD01: start 8, 8 bit, little-endian, data-type-policy=OVERRIDE, i-signal-type=PRIMITIVE, init-value=63, base-type=BT_DCDC_NV_CALID_Index_02, compu-method=CM_DCDC_NV_CALID_Index_02, data-constr=DC_DCDC_NV_CALID_Index_02, transfer-property=PENDING, to BMC_HV(timeout 5 s)  # Calibration Identification
          signal DCDC_NV_CALID_Index_03_XIX_DCDC_NV_CALID_XIX_HCP5_CANFD01: start 16, 8 bit, little-endian, data-type-policy=OVERRIDE, i-signal-type=PRIMITIVE, init-value=63, base-type=BT_DCDC_NV_CALID_Index_03, compu-method=CM_DCDC_NV_CALID_Index_03, data-constr=DC_DCDC_NV_CALID_Index_03, transfer-property=PENDING, to BMC_HV(timeout 5 s)  # Calibration Identification
          signal DCDC_NV_CALID_Index_04_XIX_DCDC_NV_CALID_XIX_HCP5_CANFD01: start 24, 8 bit, little-endian, data-type-policy=OVERRIDE, i-signal-type=PRIMITIVE, init-value=63, base-type=BT_DCDC_NV_CALID_Index_04, compu-method=CM_DCDC_NV_CALID_Index_04, data-constr=DC_DCDC_NV_CALID_Index_04, transfer-property=PENDING, to BMC_HV(timeout 5 s)  # Calibration Identification
          signal DCDC_NV_CALID_Index_05_XIX_DCDC_NV_CALID_XIX_HCP5_CANFD01: start 32, 8 bit, little-endian, data-type-policy=OVERRIDE, i-signal-type=PRIMITIVE, init-value=63, base-type=BT_DCDC_NV_CALID_Index_05, compu-method=CM_DCDC_NV_CALID_Index_05, data-constr=DC_DCDC_NV_CALID_Index_05, transfer-property=PENDING, to BMC_HV(timeout 5 s)  # Calibration Identification
          signal DCDC_NV_CALID_Index_06_XIX_DCDC_NV_CALID_XIX_HCP5_CANFD01: start 40, 8 bit, little-endian, data-type-policy=OVERRIDE, i-signal-type=PRIMITIVE, init-value=63, base-type=BT_DCDC_NV_CALID_Index_06, compu-method=CM_DCDC_NV_CALID_Index_06, data-constr=DC_DCDC_NV_CALID_Index_06, transfer-property=PENDING, to BMC_HV(timeout 5 s)  # Calibration Identification
          signal DCDC_NV_CALID_Index_07_XIX_DCDC_NV_CALID_XIX_HCP5_CANFD01: start 48, 8 bit, little-endian, data-type-policy=OVERRIDE, i-signal-type=PRIMITIVE, init-value=63, base-type=BT_DCDC_NV_CALID_Index_07, compu-method=CM_DCDC_NV_CALID_Index_07, data-constr=DC_DCDC_NV_CALID_Index_07, transfer-property=PENDING, to BMC_HV(timeout 5 s)  # Calibration Identification
          signal DCDC_NV_CALID_Index_08_XIX_DCDC_NV_CALID_XIX_HCP5_CANFD01: start 56, 8 bit, little-endian, data-type-policy=OVERRIDE, i-signal-type=PRIMITIVE, init-value=63, base-type=BT_DCDC_NV_CALID_Index_08, compu-method=CM_DCDC_NV_CALID_Index_08, data-constr=DC_DCDC_NV_CALID_Index_08, transfer-property=PENDING, to BMC_HV(timeout 5 s)  # Calibration Identification
          signal DCDC_NV_CALID_Index_09_XIX_DCDC_NV_CALID_XIX_HCP5_CANFD01: start 64, 8 bit, little-endian, data-type-policy=OVERRIDE, i-signal-type=PRIMITIVE, init-value=63, base-type=BT_DCDC_NV_CALID_Index_09, compu-method=CM_DCDC_NV_CALID_Index_09, data-constr=DC_DCDC_NV_CALID_Index_09, transfer-property=PENDING, to BMC_HV(timeout 5 s)  # Calibration Identification
          signal DCDC_NV_CALID_Index_10_XIX_DCDC_NV_CALID_XIX_HCP5_CANFD01: start 72, 8 bit, little-endian, data-type-policy=OVERRIDE, i-signal-type=PRIMITIVE, init-value=63, base-type=BT_DCDC_NV_CALID_Index_10, compu-method=CM_DCDC_NV_CALID_Index_10, data-constr=DC_DCDC_NV_CALID_Index_10, transfer-property=PENDING, to BMC_HV(timeout 5 s)  # Calibration Identification
          signal DCDC_NV_CALID_Index_11_XIX_DCDC_NV_CALID_XIX_HCP5_CANFD01: start 80, 8 bit, little-endian, data-type-policy=OVERRIDE, i-signal-type=PRIMITIVE, init-value=63, base-type=BT_DCDC_NV_CALID_Index_11, compu-method=CM_DCDC_NV_CALID_Index_11, data-constr=DC_DCDC_NV_CALID_Index_11, transfer-property=PENDING, to BMC_HV(timeout 5 s)  # Calibration Identification
          signal DCDC_NV_CALID_Index_12_XIX_DCDC_NV_CALID_XIX_HCP5_CANFD01: start 88, 8 bit, little-endian, data-type-policy=OVERRIDE, i-signal-type=PRIMITIVE, init-value=63, base-type=BT_DCDC_NV_CALID_Index_12, compu-method=CM_DCDC_NV_CALID_Index_12, data-constr=DC_DCDC_NV_CALID_Index_12, transfer-property=PENDING, to BMC_HV(timeout 5 s)  # Calibration Identification
          signal DCDC_NV_CALID_Index_13_XIX_DCDC_NV_CALID_XIX_HCP5_CANFD01: start 96, 8 bit, little-endian, data-type-policy=OVERRIDE, i-signal-type=PRIMITIVE, init-value=63, base-type=BT_DCDC_NV_CALID_Index_13, compu-method=CM_DCDC_NV_CALID_Index_13, data-constr=DC_DCDC_NV_CALID_Index_13, transfer-property=PENDING, to BMC_HV(timeout 5 s)  # Calibration Identification
          signal DCDC_NV_CALID_Index_14_XIX_DCDC_NV_CALID_XIX_HCP5_CANFD01: start 104, 8 bit, little-endian, data-type-policy=OVERRIDE, i-signal-type=PRIMITIVE, init-value=63, base-type=BT_DCDC_NV_CALID_Index_14, compu-method=CM_DCDC_NV_CALID_Index_14, data-constr=DC_DCDC_NV_CALID_Index_14, transfer-property=PENDING, to BMC_HV(timeout 5 s)  # Calibration Identification
          signal DCDC_NV_CALID_Index_15_XIX_DCDC_NV_CALID_XIX_HCP5_CANFD01: start 112, 8 bit, little-endian, data-type-policy=OVERRIDE, i-signal-type=PRIMITIVE, init-value=63, base-type=BT_DCDC_NV_CALID_Index_15, compu-method=CM_DCDC_NV_CALID_Index_15, data-constr=DC_DCDC_NV_CALID_Index_15, transfer-property=PENDING, to BMC_HV(timeout 5 s)  # Calibration Identification
          signal DCDC_NV_CALID_Index_16_XIX_DCDC_NV_CALID_XIX_HCP5_CANFD01: start 120, 8 bit, little-endian, data-type-policy=OVERRIDE, i-signal-type=PRIMITIVE, init-value=63, base-type=BT_DCDC_NV_CALID_Index_16, compu-method=CM_DCDC_NV_CALID_Index_16, data-constr=DC_DCDC_NV_CALID_Index_16, transfer-property=PENDING, to BMC_HV(timeout 5 s)  # Calibration Identification
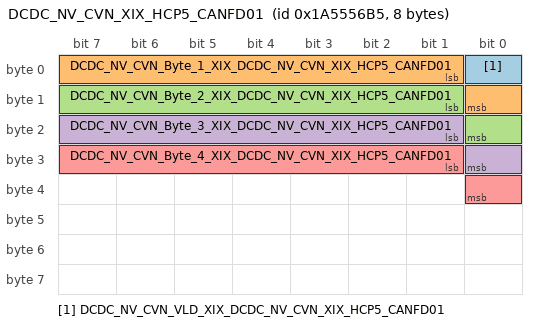
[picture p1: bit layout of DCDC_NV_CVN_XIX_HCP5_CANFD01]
      frame DCDC_NV_CVN_XIX_HCP5_CANFD01: id 0x1A5556B5, to BMC_HV, frame-length=8, can-addressing-mode=EXTENDED, can-frame-rx-behavior=CAN-FD, can-frame-tx-behavior=CAN-FD
        pdu DCDC_NV_CVN_XIX_HCP5_CANFD01: length=8, transmission-mode-true-timing=cyclic-timing={time-offset=0, time-period=1}, unused-bit-pattern=0
          signal DCDC_NV_CVN_VLD_XIX_DCDC_NV_CVN_XIX_HCP5_CANFD01: start 0, 1 bit, little-endian, data-type-policy=OVERRIDE, i-signal-type=PRIMITIVE, init-value=0, base-type=BT_DCDC_NV_CVN_VLD, compu-method=CM_DCDC_NV_CVN_VLD, data-constr=DC_DCDC_NV_CVN_VLD, transfer-property=PENDING, to BMC_HV(timeout 5 s)  # Über dieses Signal wird gekennzeichnet, ob die Berechnung der CVN im SecondaryOBDECU abgeschlossen ist.
          signal DCDC_NV_CVN_Byte_1_XIX_DCDC_NV_CVN_XIX_HCP5_CANFD01: start 1, 8 bit, little-endian, data-type-policy=OVERRIDE, i-signal-type=PRIMITIVE, init-value=0, base-type=BT_DCDC_NV_CVN_Byte_1, compu-method=CM_DCDC_NV_CVN_Byte_1, data-constr=DC_DCDC_NV_CVN_Byte_1, transfer-property=PENDING, to BMC_HV(timeout 5 s)  # Calibration Verification Number
          signal DCDC_NV_CVN_Byte_2_XIX_DCDC_NV_CVN_XIX_HCP5_CANFD01: start 9, 8 bit, little-endian, data-type-policy=OVERRIDE, i-signal-type=PRIMITIVE, init-value=0, base-type=BT_DCDC_NV_CVN_Byte_2, compu-method=CM_DCDC_NV_CVN_Byte_2, data-constr=DC_DCDC_NV_CVN_Byte_2, transfer-property=PENDING, to BMC_HV(timeout 5 s)  # Calibration Verification Number
          signal DCDC_NV_CVN_Byte_3_XIX_DCDC_NV_CVN_XIX_HCP5_CANFD01: start 17, 8 bit, little-endian, data-type-policy=OVERRIDE, i-signal-type=PRIMITIVE, init-value=0, base-type=BT_DCDC_NV_CVN_Byte_3, compu-method=CM_DCDC_NV_CVN_Byte_3, data-constr=DC_DCDC_NV_CVN_Byte_3, transfer-property=PENDING, to BMC_HV(timeout 5 s)  # Calibration Verification Number
          signal DCDC_NV_CVN_Byte_4_XIX_DCDC_NV_CVN_XIX_HCP5_CANFD01: start 25, 8 bit, little-endian, data-type-policy=OVERRIDE, i-signal-type=PRIMITIVE, init-value=0, base-type=BT_DCDC_NV_CVN_Byte_4, compu-method=CM_DCDC_NV_CVN_Byte_4, data-constr=DC_DCDC_NV_CVN_Byte_4, transfer-property=PENDING, to BMC_HV(timeout 5 s)  # Calibration Verification Number
      frame DCDC_NV_Komponentenfehler_01_XIX_HCP5_CANFD01: id 0x1A5556B0, to BMC_HV, frame-length=8, can-addressing-mode=EXTENDED, can-frame-rx-behavior=CAN-FD, can-frame-tx-behavior=CAN-FD
        pdu DCDC_NV_Komponentenfehler_01_XIX_HCP5_CANFD01: length=8, transmission-mode-true-timing=cyclic-timing={time-offset=0, time-period=0.5}, unused-bit-pattern=0
          signal DCDC_NV_Komponentenfehler_01_XIX_DCDC_NV_Komponentenfehler_01_XIX_HCP5_CANFD01: start 0, 2 bit, little-endian, data-type-policy=OVERRIDE, i-signal-type=PRIMITIVE, init-value=0, base-type=BT_DCDC_NV_Komponentenfehler_01, compu-method=CM_DCDC_NV_Komponentenfehler_01, data-constr=DC_DCDC_NV_Komponentenfehler_01, transfer-property=PENDING, to BMC_HV(timeout 5 s)  # Übertragung OBD relevanter Fehlerpfade vom Secondary zum Primary Steuergerät. Zuordnung der generischen Komponentenfehler muss zwischen Sender und Empfänger abgestimmt werden.
          signal DCDC_NV_Komponentenfehler_02_XIX_DCDC_NV_Komponentenfehler_01_XIX_HCP5_CANFD01: start 2, 2 bit, little-endian, data-type-policy=OVERRIDE, i-signal-type=PRIMITIVE, init-value=0, base-type=BT_DCDC_NV_Komponentenfehler_02, compu-method=CM_DCDC_NV_Komponentenfehler_02, data-constr=DC_DCDC_NV_Komponentenfehler_02, transfer-property=PENDING, to BMC_HV(timeout 5 s)  # Übertragung OBD relevanter Fehlerpfade vom Secondary zum Primary Steuergerät. Zuordnung der generischen Komponentenfehler muss zwischen Sender und Empfänger abgestimmt werden.
          signal DCDC_NV_Komponentenfehler_03_XIX_DCDC_NV_Komponentenfehler_01_XIX_HCP5_CANFD01: start 4, 2 bit, little-endian, data-type-policy=OVERRIDE, i-signal-type=PRIMITIVE, init-value=0, base-type=BT_DCDC_NV_Komponentenfehler_03, compu-method=CM_DCDC_NV_Komponentenfehler_03, data-constr=DC_DCDC_NV_Komponentenfehler_03, transfer-property=PENDING, to BMC_HV(timeout 5 s)  # Übertragung OBD relevanter Fehlerpfade vom Secondary zum Primary Steuergerät. Zuordnung der generischen Komponentenfehler muss zwischen Sender und Empfänger abgestimmt werden.
          signal DCDC_NV_Komponentenfehler_04_XIX_DCDC_NV_Komponentenfehler_01_XIX_HCP5_CANFD01: start 6, 2 bit, little-endian, data-type-policy=OVERRIDE, i-signal-type=PRIMITIVE, init-value=0, base-type=BT_DCDC_NV_Komponentenfehler_04, compu-method=CM_DCDC_NV_Komponentenfehler_04, data-constr=DC_DCDC_NV_Komponentenfehler_04, transfer-property=PENDING, to BMC_HV(timeout 5 s)  # Übertragung OBD relevanter Fehlerpfade vom Secondary zum Primary Steuergerät. Zuordnung der generischen Komponentenfehler muss zwischen Sender und Empfänger abgestimmt werden.
          signal DCDC_NV_Komponentenfehler_05_XIX_DCDC_NV_Komponentenfehler_01_XIX_HCP5_CANFD01: start 8, 2 bit, little-endian, data-type-policy=OVERRIDE, i-signal-type=PRIMITIVE, init-value=0, base-type=BT_DCDC_NV_Komponentenfehler_05, compu-method=CM_DCDC_NV_Komponentenfehler_05, data-constr=DC_DCDC_NV_Komponentenfehler_05, transfer-property=PENDING, to BMC_HV(timeout 5 s)  # Übertragung OBD relevanter Fehlerpfade vom Secondary zum Primary Steuergerät. Zuordnung der generischen Komponentenfehler muss zwischen Sender und Empfänger abgestimmt werden.
          signal DCDC_NV_Komponentenfehler_06_XIX_DCDC_NV_Komponentenfehler_01_XIX_HCP5_CANFD01: start 10, 2 bit, little-endian, data-type-policy=OVERRIDE, i-signal-type=PRIMITIVE, init-value=0, base-type=BT_DCDC_NV_Komponentenfehler_06, compu-method=CM_DCDC_NV_Komponentenfehler_06, data-constr=DC_DCDC_NV_Komponentenfehler_06, transfer-property=PENDING, to BMC_HV(timeout 5 s)  # Übertragung OBD relevanter Fehlerpfade vom Secondary zum Primary Steuergerät. Zuordnung der generischen Komponentenfehler muss zwischen Sender und Empfänger abgestimmt werden.
          signal DCDC_NV_Komponentenfehler_07_XIX_DCDC_NV_Komponentenfehler_01_XIX_HCP5_CANFD01: start 12, 2 bit, little-endian, data-type-policy=OVERRIDE, i-signal-type=PRIMITIVE, init-value=0, base-type=BT_DCDC_NV_Komponentenfehler_07, compu-method=CM_DCDC_NV_Komponentenfehler_07, data-constr=DC_DCDC_NV_Komponentenfehler_07, transfer-property=PENDING, to BMC_HV(timeout 5 s)  # Übertragung OBD relevanter Fehlerpfade vom Secondary zum Primary Steuergerät. Zuordnung der generischen Komponentenfehler muss zwischen Sender und Empfänger abgestimmt werden.
          signal DCDC_NV_Komponentenfehler_08_XIX_DCDC_NV_Komponentenfehler_01_XIX_HCP5_CANFD01: start 14, 2 bit, little-endian, data-type-policy=OVERRIDE, i-signal-type=PRIMITIVE, init-value=0, base-type=BT_DCDC_NV_Komponentenfehler_08, compu-method=CM_DCDC_NV_Komponentenfehler_08, data-constr=DC_DCDC_NV_Komponentenfehler_08, transfer-property=PENDING, to BMC_HV(timeout 5 s)  # Übertragung OBD relevanter Fehlerpfade vom Secondary zum Primary Steuergerät. Zuordnung der generischen Komponentenfehler muss zwischen Sender und Empfänger abgestimmt werden.
          signal DCDC_NV_Komponentenfehler_09_XIX_DCDC_NV_Komponentenfehler_01_XIX_HCP5_CANFD01: start 16, 2 bit, little-endian, data-type-policy=OVERRIDE, i-signal-type=PRIMITIVE, init-value=0, base-type=BT_DCDC_NV_Komponentenfehler_09, compu-method=CM_DCDC_NV_Komponentenfehler_09, data-constr=DC_DCDC_NV_Komponentenfehler_09, transfer-property=PENDING, to BMC_HV(timeout 5 s)  # Übertragung OBD relevanter Fehlerpfade vom Secondary zum Primary Steuergerät. Zuordnung der generischen Komponentenfehler muss zwischen Sender und Empfänger abgestimmt werden.
          signal DCDC_NV_Komponentenfehler_10_XIX_DCDC_NV_Komponentenfehler_01_XIX_HCP5_CANFD01: start 18, 2 bit, little-endian, data-type-policy=OVERRIDE, i-signal-type=PRIMITIVE, init-value=0, base-type=BT_DCDC_NV_Komponentenfehler_10, compu-method=CM_DCDC_NV_Komponentenfehler_10, data-constr=DC_DCDC_NV_Komponentenfehler_10, transfer-property=PENDING, to BMC_HV(timeout 5 s)  # Übertragung OBD relevanter Fehlerpfade vom Secondary zum Primary Steuergerät. Zuordnung der generischen Komponentenfehler muss zwischen Sender und Empfänger abgestimmt werden.
          signal DCDC_NV_Komponentenfehler_11_XIX_DCDC_NV_Komponentenfehler_01_XIX_HCP5_CANFD01: start 20, 2 bit, little-endian, data-type-policy=OVERRIDE, i-signal-type=PRIMITIVE, init-value=0, base-type=BT_DCDC_NV_Komponentenfehler_11, compu-method=CM_DCDC_NV_Komponentenfehler_11, data-constr=DC_DCDC_NV_Komponentenfehler_11, transfer-property=PENDING, to BMC_HV(timeout 5 s)  # Übertragung OBD relevanter Fehlerpfade vom Secondary zum Primary Steuergerät. Zuordnung der generischen Komponentenfehler muss zwischen Sender und Empfänger abgestimmt werden.
          signal DCDC_NV_Komponentenfehler_12_XIX_DCDC_NV_Komponentenfehler_01_XIX_HCP5_CANFD01: start 22, 2 bit, little-endian, data-type-policy=OVERRIDE, i-signal-type=PRIMITIVE, init-value=0, base-type=BT_DCDC_NV_Komponentenfehler_12, compu-method=CM_DCDC_NV_Komponentenfehler_12, data-constr=DC_DCDC_NV_Komponentenfehler_12, transfer-property=PENDING, to BMC_HV(timeout 5 s)  # Übertragung OBD relevanter Fehlerpfade vom Secondary zum Primary Steuergerät. Zuordnung der generischen Komponentenfehler muss zwischen Sender und Empfänger abgestimmt werden.
          signal DCDC_NV_Komponentenfehler_13_XIX_DCDC_NV_Komponentenfehler_01_XIX_HCP5_CANFD01: start 24, 2 bit, little-endian, data-type-policy=OVERRIDE, i-signal-type=PRIMITIVE, init-value=0, base-type=BT_DCDC_NV_Komponentenfehler_13, compu-method=CM_DCDC_NV_Komponentenfehler_13, data-constr=DC_DCDC_NV_Komponentenfehler_13, transfer-property=PENDING, to BMC_HV(timeout 5 s)  # Übertragung OBD relevanter Fehlerpfade vom Secondary zum Primary Steuergerät. Zuordnung der generischen Komponentenfehler muss zwischen Sender und Empfänger abgestimmt werden.
          signal DCDC_NV_Komponentenfehler_14_XIX_DCDC_NV_Komponentenfehler_01_XIX_HCP5_CANFD01: start 26, 2 bit, little-endian, data-type-policy=OVERRIDE, i-signal-type=PRIMITIVE, init-value=0, base-type=BT_DCDC_NV_Komponentenfehler_14, compu-method=CM_DCDC_NV_Komponentenfehler_14, data-constr=DC_DCDC_NV_Komponentenfehler_14, transfer-property=PENDING, to BMC_HV(timeout 5 s)  # Übertragung OBD relevanter Fehlerpfade vom Secondary zum Primary Steuergerät. Zuordnung der generischen Komponentenfehler muss zwischen Sender und Empfänger abgestimmt werden.
          signal DCDC_NV_Komponentenfehler_15_XIX_DCDC_NV_Komponentenfehler_01_XIX_HCP5_CANFD01: start 28, 2 bit, little-endian, data-type-policy=OVERRIDE, i-signal-type=PRIMITIVE, init-value=0, base-type=BT_DCDC_NV_Komponentenfehler_15, compu-method=CM_DCDC_NV_Komponentenfehler_15, data-constr=DC_DCDC_NV_Komponentenfehler_15, transfer-property=PENDING, to BMC_HV(timeout 5 s)  # Übertragung OBD relevanter Fehlerpfade vom Secondary zum Primary Steuergerät. Zuordnung der generischen Komponentenfehler muss zwischen Sender und Empfänger abgestimmt werden.
          signal DCDC_NV_Komponentenfehler_16_XIX_DCDC_NV_Komponentenfehler_01_XIX_HCP5_CANFD01: start 30, 2 bit, little-endian, data-type-policy=OVERRIDE, i-signal-type=PRIMITIVE, init-value=0, base-type=BT_DCDC_NV_Komponentenfehler_16, compu-method=CM_DCDC_NV_Komponentenfehler_16, data-constr=DC_DCDC_NV_Komponentenfehler_16, transfer-property=PENDING, to BMC_HV(timeout 5 s)  # Übertragung OBD relevanter Fehlerpfade vom Secondary zum Primary Steuergerät. Zuordnung der generischen Komponentenfehler muss zwischen Sender und Empfänger abgestimmt werden.
          signal DCDC_NV_Komponentenfehler_17_XIX_DCDC_NV_Komponentenfehler_01_XIX_HCP5_CANFD01: start 32, 2 bit, little-endian, data-type-policy=OVERRIDE, i-signal-type=PRIMITIVE, init-value=0, base-type=BT_DCDC_NV_Komponentenfehler_17, compu-method=CM_DCDC_NV_Komponentenfehler_17, data-constr=DC_DCDC_NV_Komponentenfehler_17, transfer-property=PENDING, to BMC_HV(timeout 5 s)  # Übertragung OBD relevanter Fehlerpfade vom Secondary zum Primary Steuergerät. Zuordnung der generischen Komponentenfehler muss zwischen Sender und Empfänger abgestimmt werden.
          signal DCDC_NV_Komponentenfehler_18_XIX_DCDC_NV_Komponentenfehler_01_XIX_HCP5_CANFD01: start 34, 2 bit, little-endian, data-type-policy=OVERRIDE, i-signal-type=PRIMITIVE, init-value=0, base-type=BT_DCDC_NV_Komponentenfehler_18, compu-method=CM_DCDC_NV_Komponentenfehler_18, data-constr=DC_DCDC_NV_Komponentenfehler_18, transfer-property=PENDING, to BMC_HV(timeout 5 s)  # Übertragung OBD relevanter Fehlerpfade vom Secondary zum Primary Steuergerät. Zuordnung der generischen Komponentenfehler muss zwischen Sender und Empfänger abgestimmt werden.
          signal DCDC_NV_Komponentenfehler_19_XIX_DCDC_NV_Komponentenfehler_01_XIX_HCP5_CANFD01: start 36, 2 bit, little-endian, data-type-policy=OVERRIDE, i-signal-type=PRIMITIVE, init-value=0, base-type=BT_DCDC_NV_Komponentenfehler_19, compu-method=CM_DCDC_NV_Komponentenfehler_19, data-constr=DC_DCDC_NV_Komponentenfehler_19, transfer-property=PENDING, to BMC_HV(timeout 5 s)  # Übertragung OBD relevanter Fehlerpfade vom Secondary zum Primary Steuergerät. Zuordnung der generischen Komponentenfehler muss zwischen Sender und Empfänger abgestimmt werden.
          signal DCDC_NV_Komponentenfehler_20_XIX_DCDC_NV_Komponentenfehler_01_XIX_HCP5_CANFD01: start 38, 2 bit, little-endian, data-type-policy=OVERRIDE, i-signal-type=PRIMITIVE, init-value=0, base-type=BT_DCDC_NV_Komponentenfehler_20, compu-method=CM_DCDC_NV_Komponentenfehler_20, data-constr=DC_DCDC_NV_Komponentenfehler_20, transfer-property=PENDING, to BMC_HV(timeout 5 s)  # Übertragung OBD relevanter Fehlerpfade vom Secondary zum Primary Steuergerät. Zuordnung der generischen Komponentenfehler muss zwischen Sender und Empfänger abgestimmt werden.
          signal DCDC_NV_Komponentenfehler_21_XIX_DCDC_NV_Komponentenfehler_01_XIX_HCP5_CANFD01: start 40, 2 bit, little-endian, data-type-policy=OVERRIDE, i-signal-type=PRIMITIVE, init-value=0, base-type=BT_DCDC_NV_Komponentenfehler_21, compu-method=CM_DCDC_NV_Komponentenfehler_21, data-constr=DC_DCDC_NV_Komponentenfehler_21, transfer-property=PENDING, to BMC_HV(timeout 5 s)  # Übertragung OBD relevanter Fehlerpfade vom Secondary zum Primary Steuergerät. Zuordnung der generischen Komponentenfehler muss zwischen Sender und Empfänger abgestimmt werden.
          signal DCDC_NV_Komponentenfehler_22_XIX_DCDC_NV_Komponentenfehler_01_XIX_HCP5_CANFD01: start 42, 2 bit, little-endian, data-type-policy=OVERRIDE, i-signal-type=PRIMITIVE, init-value=0, base-type=BT_DCDC_NV_Komponentenfehler_22, compu-method=CM_DCDC_NV_Komponentenfehler_22, data-constr=DC_DCDC_NV_Komponentenfehler_22, transfer-property=PENDING, to BMC_HV(timeout 5 s)  # Übertragung OBD relevanter Fehlerpfade vom Secondary zum Primary Steuergerät. Zuordnung der generischen Komponentenfehler muss zwischen Sender und Empfänger abgestimmt werden.
          signal DCDC_NV_Komponentenfehler_23_XIX_DCDC_NV_Komponentenfehler_01_XIX_HCP5_CANFD01: start 44, 2 bit, little-endian, data-type-policy=OVERRIDE, i-signal-type=PRIMITIVE, init-value=0, base-type=BT_DCDC_NV_Komponentenfehler_23, compu-method=CM_DCDC_NV_Komponentenfehler_23, data-constr=DC_DCDC_NV_Komponentenfehler_23, transfer-property=PENDING, to BMC_HV(timeout 5 s)  # Übertragung OBD relevanter Fehlerpfade vom Secondary zum Primary Steuergerät. Zuordnung der generischen Komponentenfehler muss zwischen Sender und Empfänger abgestimmt werden.
          signal DCDC_NV_Komponentenfehler_24_XIX_DCDC_NV_Komponentenfehler_01_XIX_HCP5_CANFD01: start 46, 2 bit, little-endian, data-type-policy=OVERRIDE, i-signal-type=PRIMITIVE, init-value=0, base-type=BT_DCDC_NV_Komponentenfehler_24, compu-method=CM_DCDC_NV_Komponentenfehler_24, data-constr=DC_DCDC_NV_Komponentenfehler_24, transfer-property=PENDING, to BMC_HV(timeout 5 s)  # Übertragung OBD relevanter Fehlerpfade vom Secondary zum Primary Steuergerät. Zuordnung der generischen Komponentenfehler muss zwischen Sender und Empfänger abgestimmt werden.
          signal DCDC_NV_Komponentenfehler_25_XIX_DCDC_NV_Komponentenfehler_01_XIX_HCP5_CANFD01: start 48, 2 bit, little-endian, data-type-policy=OVERRIDE, i-signal-type=PRIMITIVE, init-value=0, base-type=BT_DCDC_NV_Komponentenfehler_25, compu-method=CM_DCDC_NV_Komponentenfehler_25, data-constr=DC_DCDC_NV_Komponentenfehler_25, transfer-property=PENDING, to BMC_HV(timeout 5 s)  # Übertragung OBD relevanter Fehlerpfade vom Secondary zum Primary Steuergerät. Zuordnung der generischen Komponentenfehler muss zwischen Sender und Empfänger abgestimmt werden.
          signal DCDC_NV_Komponentenfehler_26_XIX_DCDC_NV_Komponentenfehler_01_XIX_HCP5_CANFD01: start 50, 2 bit, little-endian, data-type-policy=OVERRIDE, i-signal-type=PRIMITIVE, init-value=0, base-type=BT_DCDC_NV_Komponentenfehler_26, compu-method=CM_DCDC_NV_Komponentenfehler_26, data-constr=DC_DCDC_NV_Komponentenfehler_26, transfer-property=PENDING, to BMC_HV(timeout 5 s)  # Übertragung OBD relevanter Fehlerpfade vom Secondary zum Primary Steuergerät. Zuordnung der generischen Komponentenfehler muss zwischen Sender und Empfänger abgestimmt werden.
          signal DCDC_NV_Komponentenfehler_27_XIX_DCDC_NV_Komponentenfehler_01_XIX_HCP5_CANFD01: start 52, 2 bit, little-endian, data-type-policy=OVERRIDE, i-signal-type=PRIMITIVE, init-value=0, base-type=BT_DCDC_NV_Komponentenfehler_27, compu-method=CM_DCDC_NV_Komponentenfehler_27, data-constr=DC_DCDC_NV_Komponentenfehler_27, transfer-property=PENDING, to BMC_HV(timeout 5 s)  # Übertragung OBD relevanter Fehlerpfade vom Secondary zum Primary Steuergerät. Zuordnung der generischen Komponentenfehler muss zwischen Sender und Empfänger abgestimmt werden.
          signal DCDC_NV_Komponentenfehler_28_XIX_DCDC_NV_Komponentenfehler_01_XIX_HCP5_CANFD01: start 54, 2 bit, little-endian, data-type-policy=OVERRIDE, i-signal-type=PRIMITIVE, init-value=0, base-type=BT_DCDC_NV_Komponentenfehler_28, compu-method=CM_DCDC_NV_Komponentenfehler_28, data-constr=DC_DCDC_NV_Komponentenfehler_28, transfer-property=PENDING, to BMC_HV(timeout 5 s)  # Übertragung OBD relevanter Fehlerpfade vom Secondary zum Primary Steuergerät. Zuordnung der generischen Komponentenfehler muss zwischen Sender und Empfänger abgestimmt werden.
          signal DCDC_NV_Komponentenfehler_29_XIX_DCDC_NV_Komponentenfehler_01_XIX_HCP5_CANFD01: start 56, 2 bit, little-endian, data-type-policy=OVERRIDE, i-signal-type=PRIMITIVE, init-value=0, base-type=BT_DCDC_NV_Komponentenfehler_29, compu-method=CM_DCDC_NV_Komponentenfehler_29, data-constr=DC_DCDC_NV_Komponentenfehler_29, transfer-property=PENDING, to BMC_HV(timeout 5 s)  # Übertragung OBD relevanter Fehlerpfade vom Secondary zum Primary Steuergerät. Zuordnung der generischen Komponentenfehler muss zwischen Sender und Empfänger abgestimmt werden.
          signal DCDC_NV_Komponentenfehler_VLD_XIX_DCDC_NV_Komponentenfehler_01_XIX_HCP5_CANFD01: start 63, 1 bit, little-endian, data-type-policy=OVERRIDE, i-signal-type=PRIMITIVE, init-value=0, base-type=BT_DCDC_NV_Komponentenfehler_VLD, compu-method=CM_DCDC_NV_Komponentenfehler_VLD, data-constr=DC_DCDC_NV_Komponentenfehler_VLD, transfer-property=PENDING, to BMC_HV(timeout 5 s)  # Valid-Bit der OBD-Komponentenfehler. Das Bit wird beim Fehlerspeicher löschen zurückgenommen und erst wieder gesetzt, wenn der Fehlerspeicher vollständig gelöscht wurde. Der Primary-OBD-ECU soll damit mitgeteilt werden, ob sie den Inhalten der Komponentenfehler-Signalen vertrauen kann oder nicht.
      frame DCDC_NV_Komponentenfehler_02_XIX_HCP5_CANFD01: id 0x1A5556B1, to BMC_HV, frame-length=8, can-addressing-mode=EXTENDED, can-frame-rx-behavior=CAN-FD, can-frame-tx-behavior=CAN-FD
        pdu DCDC_NV_Komponentenfehler_02_XIX_HCP5_CANFD01: length=8, transmission-mode-true-timing=cyclic-timing={time-offset=0, time-period=0.5}, unused-bit-pattern=0
          signal DCDC_NV_Komponentenfehler_30_XIX_DCDC_NV_Komponentenfehler_02_XIX_HCP5_CANFD01: start 0, 2 bit, little-endian, data-type-policy=OVERRIDE, i-signal-type=PRIMITIVE, init-value=0, base-type=BT_DCDC_NV_Komponentenfehler_30, compu-method=CM_DCDC_NV_Komponentenfehler_30, data-constr=DC_DCDC_NV_Komponentenfehler_30, transfer-property=PENDING, to BMC_HV(timeout 5 s)  # Übertragung OBD relevanter Fehlerpfade vom Secondary zum Primary Steuergerät. Zuordnung der generischen Komponentenfehler muss zwischen Sender und Empfänger abgestimmt werden.
          signal DCDC_NV_Komponentenfehler_31_XIX_DCDC_NV_Komponentenfehler_02_XIX_HCP5_CANFD01: start 2, 2 bit, little-endian, data-type-policy=OVERRIDE, i-signal-type=PRIMITIVE, init-value=0, base-type=BT_DCDC_NV_Komponentenfehler_31, compu-method=CM_DCDC_NV_Komponentenfehler_31, data-constr=DC_DCDC_NV_Komponentenfehler_31, transfer-property=PENDING, to BMC_HV(timeout 5 s)  # Übertragung OBD relevanter Fehlerpfade vom Secondary zum Primary Steuergerät. Zuordnung der generischen Komponentenfehler muss zwischen Sender und Empfänger abgestimmt werden.
          signal DCDC_NV_Komponentenfehler_32_XIX_DCDC_NV_Komponentenfehler_02_XIX_HCP5_CANFD01: start 4, 2 bit, little-endian, data-type-policy=OVERRIDE, i-signal-type=PRIMITIVE, init-value=0, base-type=BT_DCDC_NV_Komponentenfehler_32, compu-method=CM_DCDC_NV_Komponentenfehler_32, data-constr=DC_DCDC_NV_Komponentenfehler_32, transfer-property=PENDING, to BMC_HV(timeout 5 s)  # Übertragung OBD relevanter Fehlerpfade vom Secondary zum Primary Steuergerät. Zuordnung der generischen Komponentenfehler muss zwischen Sender und Empfänger abgestimmt werden.
          signal DCDC_NV_Komponentenfehler_33_XIX_DCDC_NV_Komponentenfehler_02_XIX_HCP5_CANFD01: start 6, 2 bit, little-endian, data-type-policy=OVERRIDE, i-signal-type=PRIMITIVE, init-value=0, base-type=BT_DCDC_NV_Komponentenfehler_33, compu-method=CM_DCDC_NV_Komponentenfehler_33, data-constr=DC_DCDC_NV_Komponentenfehler_33, transfer-property=PENDING, to BMC_HV(timeout 5 s)  # Übertragung OBD relevanter Fehlerpfade vom Secondary zum Primary Steuergerät. Zuordnung der generischen Komponentenfehler muss zwischen Sender und Empfänger abgestimmt werden.
          signal DCDC_NV_Komponentenfehler_34_XIX_DCDC_NV_Komponentenfehler_02_XIX_HCP5_CANFD01: start 8, 2 bit, little-endian, data-type-policy=OVERRIDE, i-signal-type=PRIMITIVE, init-value=0, base-type=BT_DCDC_NV_Komponentenfehler_34, compu-method=CM_DCDC_NV_Komponentenfehler_34, data-constr=DC_DCDC_NV_Komponentenfehler_34, transfer-property=PENDING, to BMC_HV(timeout 5 s)  # Übertragung OBD relevanter Fehlerpfade vom Secondary zum Primary Steuergerät. Zuordnung der generischen Komponentenfehler muss zwischen Sender und Empfänger abgestimmt werden.
          signal DCDC_NV_Komponentenfehler_35_XIX_DCDC_NV_Komponentenfehler_02_XIX_HCP5_CANFD01: start 10, 2 bit, little-endian, data-type-policy=OVERRIDE, i-signal-type=PRIMITIVE, init-value=0, base-type=BT_DCDC_NV_Komponentenfehler_35, compu-method=CM_DCDC_NV_Komponentenfehler_35, data-constr=DC_DCDC_NV_Komponentenfehler_35, transfer-property=PENDING, to BMC_HV(timeout 5 s)  # Übertragung OBD relevanter Fehlerpfade vom Secondary zum Primary Steuergerät. Zuordnung der generischen Komponentenfehler muss zwischen Sender und Empfänger abgestimmt werden.
          signal DCDC_NV_Komponentenfehler_36_XIX_DCDC_NV_Komponentenfehler_02_XIX_HCP5_CANFD01: start 12, 2 bit, little-endian, data-type-policy=OVERRIDE, i-signal-type=PRIMITIVE, init-value=0, base-type=BT_DCDC_NV_Komponentenfehler_36, compu-method=CM_DCDC_NV_Komponentenfehler_36, data-constr=DC_DCDC_NV_Komponentenfehler_36, transfer-property=PENDING, to BMC_HV(timeout 5 s)  # Übertragung OBD relevanter Fehlerpfade vom Secondary zum Primary Steuergerät. Zuordnung der generischen Komponentenfehler muss zwischen Sender und Empfänger abgestimmt werden.
          signal DCDC_NV_Komponentenfehler_37_XIX_DCDC_NV_Komponentenfehler_02_XIX_HCP5_CANFD01: start 14, 2 bit, little-endian, data-type-policy=OVERRIDE, i-signal-type=PRIMITIVE, init-value=0, base-type=BT_DCDC_NV_Komponentenfehler_37, compu-method=CM_DCDC_NV_Komponentenfehler_37, data-constr=DC_DCDC_NV_Komponentenfehler_37, transfer-property=PENDING, to BMC_HV(timeout 5 s)  # Übertragung OBD relevanter Fehlerpfade vom Secondary zum Primary Steuergerät. Zuordnung der generischen Komponentenfehler muss zwischen Sender und Empfänger abgestimmt werden.
          signal DCDC_NV_Komponentenfehler_38_XIX_DCDC_NV_Komponentenfehler_02_XIX_HCP5_CANFD01: start 16, 2 bit, little-endian, data-type-policy=OVERRIDE, i-signal-type=PRIMITIVE, init-value=0, base-type=BT_DCDC_NV_Komponentenfehler_38, compu-method=CM_DCDC_NV_Komponentenfehler_38, data-constr=DC_DCDC_NV_Komponentenfehler_38, transfer-property=PENDING, to BMC_HV(timeout 5 s)  # Übertragung OBD relevanter Fehlerpfade vom Secondary zum Primary Steuergerät. Zuordnung der generischen Komponentenfehler muss zwischen Sender und Empfänger abgestimmt werden.
          signal DCDC_NV_Komponentenfehler_39_XIX_DCDC_NV_Komponentenfehler_02_XIX_HCP5_CANFD01: start 18, 2 bit, little-endian, data-type-policy=OVERRIDE, i-signal-type=PRIMITIVE, init-value=0, base-type=BT_DCDC_NV_Komponentenfehler_39, compu-method=CM_DCDC_NV_Komponentenfehler_39, data-constr=DC_DCDC_NV_Komponentenfehler_39, transfer-property=PENDING, to BMC_HV(timeout 5 s)  # Übertragung OBD relevanter Fehlerpfade vom Secondary zum Primary Steuergerät. Zuordnung der generischen Komponentenfehler muss zwischen Sender und Empfänger abgestimmt werden.
          signal DCDC_NV_Komponentenfehler_40_XIX_DCDC_NV_Komponentenfehler_02_XIX_HCP5_CANFD01: start 20, 2 bit, little-endian, data-type-policy=OVERRIDE, i-signal-type=PRIMITIVE, init-value=0, base-type=BT_DCDC_NV_Komponentenfehler_40, compu-method=CM_DCDC_NV_Komponentenfehler_40, data-constr=DC_DCDC_NV_Komponentenfehler_40, transfer-property=PENDING, to BMC_HV(timeout 5 s)  # Übertragung OBD relevanter Fehlerpfade vom Secondary zum Primary Steuergerät. Zuordnung der generischen Komponentenfehler muss zwischen Sender und Empfänger abgestimmt werden.
          signal DCDC_NV_Komponentenfehler_41_XIX_DCDC_NV_Komponentenfehler_02_XIX_HCP5_CANFD01: start 22, 2 bit, little-endian, data-type-policy=OVERRIDE, i-signal-type=PRIMITIVE, init-value=0, base-type=BT_DCDC_NV_Komponentenfehler_41, compu-method=CM_DCDC_NV_Komponentenfehler_41, data-constr=DC_DCDC_NV_Komponentenfehler_41, transfer-property=PENDING, to BMC_HV(timeout 5 s)  # Übertragung OBD relevanter Fehlerpfade vom Secondary zum Primary Steuergerät. Zuordnung der generischen Komponentenfehler muss zwischen Sender und Empfänger abgestimmt werden.
          signal DCDC_NV_Komponentenfehler_42_XIX_DCDC_NV_Komponentenfehler_02_XIX_HCP5_CANFD01: start 24, 2 bit, little-endian, data-type-policy=OVERRIDE, i-signal-type=PRIMITIVE, init-value=0, base-type=BT_DCDC_NV_Komponentenfehler_42, compu-method=CM_DCDC_NV_Komponentenfehler_42, data-constr=DC_DCDC_NV_Komponentenfehler_42, transfer-property=PENDING, to BMC_HV(timeout 5 s)  # Übertragung OBD relevanter Fehlerpfade vom Secondary zum Primary Steuergerät. Zuordnung der generischen Komponentenfehler muss zwischen Sender und Empfänger abgestimmt werden.
          signal DCDC_NV_Komponentenfehler_43_XIX_DCDC_NV_Komponentenfehler_02_XIX_HCP5_CANFD01: start 26, 2 bit, little-endian, data-type-policy=OVERRIDE, i-signal-type=PRIMITIVE, init-value=0, base-type=BT_DCDC_NV_Komponentenfehler_43, compu-method=CM_DCDC_NV_Komponentenfehler_43, data-constr=DC_DCDC_NV_Komponentenfehler_43, transfer-property=PENDING, to BMC_HV(timeout 5 s)  # Übertragung OBD relevanter Fehlerpfade vom Secondary zum Primary Steuergerät. Zuordnung der generischen Komponentenfehler muss zwischen Sender und Empfänger abgestimmt werden.
          signal DCDC_NV_Komponentenfehler_44_XIX_DCDC_NV_Komponentenfehler_02_XIX_HCP5_CANFD01: start 28, 2 bit, little-endian, data-type-policy=OVERRIDE, i-signal-type=PRIMITIVE, init-value=0, base-type=BT_DCDC_NV_Komponentenfehler_44, compu-method=CM_DCDC_NV_Komponentenfehler_44, data-constr=DC_DCDC_NV_Komponentenfehler_44, transfer-property=PENDING, to BMC_HV(timeout 5 s)  # Übertragung OBD relevanter Fehlerpfade vom Secondary zum Primary Steuergerät. Zuordnung der generischen Komponentenfehler muss zwischen Sender und Empfänger abgestimmt werden.
          signal DCDC_NV_Komponentenfehler_45_XIX_DCDC_NV_Komponentenfehler_02_XIX_HCP5_CANFD01: start 30, 2 bit, little-endian, data-type-policy=OVERRIDE, i-signal-type=PRIMITIVE, init-value=0, base-type=BT_DCDC_NV_Komponentenfehler_45, compu-method=CM_DCDC_NV_Komponentenfehler_45, data-constr=DC_DCDC_NV_Komponentenfehler_45, transfer-property=PENDING, to BMC_HV(timeout 5 s)  # Übertragung OBD relevanter Fehlerpfade vom Secondary zum Primary Steuergerät. Zuordnung der generischen Komponentenfehler muss zwischen Sender und Empfänger abgestimmt werden.
          signal DCDC_NV_Komponentenfehler_46_XIX_DCDC_NV_Komponentenfehler_02_XIX_HCP5_CANFD01: start 32, 2 bit, little-endian, data-type-policy=OVERRIDE, i-signal-type=PRIMITIVE, init-value=0, base-type=BT_DCDC_NV_Komponentenfehler_46, compu-method=CM_DCDC_NV_Komponentenfehler_46, data-constr=DC_DCDC_NV_Komponentenfehler_46, transfer-property=PENDING, to BMC_HV(timeout 5 s)  # Übertragung OBD relevanter Fehlerpfade vom Secondary zum Primary Steuergerät. Zuordnung der generischen Komponentenfehler muss zwischen Sender und Empfänger abgestimmt werden.
          signal DCDC_NV_Komponentenfehler_47_XIX_DCDC_NV_Komponentenfehler_02_XIX_HCP5_CANFD01: start 34, 2 bit, little-endian, data-type-policy=OVERRIDE, i-signal-type=PRIMITIVE, init-value=0, base-type=BT_DCDC_NV_Komponentenfehler_47, compu-method=CM_DCDC_NV_Komponentenfehler_47, data-constr=DC_DCDC_NV_Komponentenfehler_47, transfer-property=PENDING, to BMC_HV(timeout 5 s)  # Übertragung OBD relevanter Fehlerpfade vom Secondary zum Primary Steuergerät. Zuordnung der generischen Komponentenfehler muss zwischen Sender und Empfänger abgestimmt werden.
          signal DCDC_NV_Komponentenfehler_48_XIX_DCDC_NV_Komponentenfehler_02_XIX_HCP5_CANFD01: start 36, 2 bit, little-endian, data-type-policy=OVERRIDE, i-signal-type=PRIMITIVE, init-value=0, base-type=BT_DCDC_NV_Komponentenfehler_48, compu-method=CM_DCDC_NV_Komponentenfehler_48, data-constr=DC_DCDC_NV_Komponentenfehler_48, transfer-property=PENDING, to BMC_HV(timeout 5 s)  # Übertragung OBD relevanter Fehlerpfade vom Secondary zum Primary Steuergerät. Zuordnung der generischen Komponentenfehler muss zwischen Sender und Empfänger abgestimmt werden.
          signal DCDC_NV_Komponentenfehler_49_XIX_DCDC_NV_Komponentenfehler_02_XIX_HCP5_CANFD01: start 38, 2 bit, little-endian, data-type-policy=OVERRIDE, i-signal-type=PRIMITIVE, init-value=0, base-type=BT_DCDC_NV_Komponentenfehler_49, compu-method=CM_DCDC_NV_Komponentenfehler_49, data-constr=DC_DCDC_NV_Komponentenfehler_49, transfer-property=PENDING, to BMC_HV(timeout 5 s)  # Übertragung OBD relevanter Fehlerpfade vom Secondary zum Primary Steuergerät. Zuordnung der generischen Komponentenfehler muss zwischen Sender und Empfänger abgestimmt werden.
          signal DCDC_NV_Komponentenfehler_50_XIX_DCDC_NV_Komponentenfehler_02_XIX_HCP5_CANFD01: start 40, 2 bit, little-endian, data-type-policy=OVERRIDE, i-signal-type=PRIMITIVE, init-value=0, base-type=BT_DCDC_NV_Komponentenfehler_50, compu-method=CM_DCDC_NV_Komponentenfehler_50, data-constr=DC_DCDC_NV_Komponentenfehler_50, transfer-property=PENDING, to BMC_HV(timeout 5 s)  # Übertragung OBD relevanter Fehlerpfade vom Secondary zum Primary Steuergerät. Zuordnung der generischen Komponentenfehler muss zwischen Sender und Empfänger abgestimmt werden.
          signal DCDC_NV_Komponentenfehler_51_XIX_DCDC_NV_Komponentenfehler_02_XIX_HCP5_CANFD01: start 42, 2 bit, little-endian, data-type-policy=OVERRIDE, i-signal-type=PRIMITIVE, init-value=0, base-type=BT_DCDC_NV_Komponentenfehler_51, compu-method=CM_DCDC_NV_Komponentenfehler_51, data-constr=DC_DCDC_NV_Komponentenfehler_51, transfer-property=PENDING, to BMC_HV(timeout 5 s)  # Übertragung OBD relevanter Fehlerpfade vom Secondary zum Primary Steuergerät. Zuordnung der generischen Komponentenfehler muss zwischen Sender und Empfänger abgestimmt werden.
          signal DCDC_NV_Komponentenfehler_52_XIX_DCDC_NV_Komponentenfehler_02_XIX_HCP5_CANFD01: start 44, 2 bit, little-endian, data-type-policy=OVERRIDE, i-signal-type=PRIMITIVE, init-value=0, base-type=BT_DCDC_NV_Komponentenfehler_52, compu-method=CM_DCDC_NV_Komponentenfehler_52, data-constr=DC_DCDC_NV_Komponentenfehler_52, transfer-property=PENDING, to BMC_HV(timeout 5 s)  # Übertragung OBD relevanter Fehlerpfade vom Secondary zum Primary Steuergerät. Zuordnung der generischen Komponentenfehler muss zwischen Sender und Empfänger abgestimmt werden.
          signal DCDC_NV_Komponentenfehler_53_XIX_DCDC_NV_Komponentenfehler_02_XIX_HCP5_CANFD01: start 46, 2 bit, little-endian, data-type-policy=OVERRIDE, i-signal-type=PRIMITIVE, init-value=0, base-type=BT_DCDC_NV_Komponentenfehler_53, compu-method=CM_DCDC_NV_Komponentenfehler_53, data-constr=DC_DCDC_NV_Komponentenfehler_53, transfer-property=PENDING, to BMC_HV(timeout 5 s)  # Übertragung OBD relevanter Fehlerpfade vom Secondary zum Primary Steuergerät. Zuordnung der generischen Komponentenfehler muss zwischen Sender und Empfänger abgestimmt werden.
          signal DCDC_NV_Komponentenfehler_54_XIX_DCDC_NV_Komponentenfehler_02_XIX_HCP5_CANFD01: start 48, 2 bit, little-endian, data-type-policy=OVERRIDE, i-signal-type=PRIMITIVE, init-value=0, base-type=BT_DCDC_NV_Komponentenfehler_54, compu-method=CM_DCDC_NV_Komponentenfehler_54, data-constr=DC_DCDC_NV_Komponentenfehler_54, transfer-property=PENDING, to BMC_HV(timeout 5 s)  # Übertragung OBD relevanter Fehlerpfade vom Secondary zum Primary Steuergerät. Zuordnung der generischen Komponentenfehler muss zwischen Sender und Empfänger abgestimmt werden.
          signal DCDC_NV_Komponentenfehler_55_XIX_DCDC_NV_Komponentenfehler_02_XIX_HCP5_CANFD01: start 50, 2 bit, little-endian, data-type-policy=OVERRIDE, i-signal-type=PRIMITIVE, init-value=0, base-type=BT_DCDC_NV_Komponentenfehler_55, compu-method=CM_DCDC_NV_Komponentenfehler_55, data-constr=DC_DCDC_NV_Komponentenfehler_55, transfer-property=PENDING, to BMC_HV(timeout 5 s)  # Übertragung OBD relevanter Fehlerpfade vom Secondary zum Primary Steuergerät. Zuordnung der generischen Komponentenfehler muss zwischen Sender und Empfänger abgestimmt werden.
          signal DCDC_NV_Komponentenfehler_56_XIX_DCDC_NV_Komponentenfehler_02_XIX_HCP5_CANFD01: start 52, 2 bit, little-endian, data-type-policy=OVERRIDE, i-signal-type=PRIMITIVE, init-value=0, base-type=BT_DCDC_NV_Komponentenfehler_56, compu-method=CM_DCDC_NV_Komponentenfehler_56, data-constr=DC_DCDC_NV_Komponentenfehler_56, transfer-property=PENDING, to BMC_HV(timeout 5 s)  # Übertragung OBD relevanter Fehlerpfade vom Secondary zum Primary Steuergerät. Zuordnung der generischen Komponentenfehler muss zwischen Sender und Empfänger abgestimmt werden.
          signal DCDC_NV_Komponentenfehler_57_XIX_DCDC_NV_Komponentenfehler_02_XIX_HCP5_CANFD01: start 54, 2 bit, little-endian, data-type-policy=OVERRIDE, i-signal-type=PRIMITIVE, init-value=0, base-type=BT_DCDC_NV_Komponentenfehler_57, compu-method=CM_DCDC_NV_Komponentenfehler_57, data-constr=DC_DCDC_NV_Komponentenfehler_57, transfer-property=PENDING, to BMC_HV(timeout 5 s)  # Übertragung OBD relevanter Fehlerpfade vom Secondary zum Primary Steuergerät. Zuordnung der generischen Komponentenfehler muss zwischen Sender und Empfänger abgestimmt werden.
          signal DCDC_NV_Komponentenfehler_58_XIX_DCDC_NV_Komponentenfehler_02_XIX_HCP5_CANFD01: start 56, 2 bit, little-endian, data-type-policy=OVERRIDE, i-signal-type=PRIMITIVE, init-value=0, base-type=BT_DCDC_NV_Komponentenfehler_58, compu-method=CM_DCDC_NV_Komponentenfehler_58, data-constr=DC_DCDC_NV_Komponentenfehler_58, transfer-property=PENDING, to BMC_HV(timeout 5 s)  # Übertragung OBD relevanter Fehlerpfade vom Secondary zum Primary Steuergerät. Zuordnung der generischen Komponentenfehler muss zwischen Sender und Empfänger abgestimmt werden.
          signal DCDC_NV_Komponentenfehler_59_XIX_DCDC_NV_Komponentenfehler_02_XIX_HCP5_CANFD01: start 58, 2 bit, little-endian, data-type-policy=OVERRIDE, i-signal-type=PRIMITIVE, init-value=0, base-type=BT_DCDC_NV_Komponentenfehler_59, compu-method=CM_DCDC_NV_Komponentenfehler_59, data-constr=DC_DCDC_NV_Komponentenfehler_59, transfer-property=PENDING, to BMC_HV(timeout 5 s)  # Übertragung OBD relevanter Fehlerpfade vom Secondary zum Primary Steuergerät. Zuordnung der generischen Komponentenfehler muss zwischen Sender und Empfänger abgestimmt werden.
          signal DCDC_NV_Komponentenfehler_60_XIX_DCDC_NV_Komponentenfehler_02_XIX_HCP5_CANFD01: start 60, 2 bit, little-endian, data-type-policy=OVERRIDE, i-signal-type=PRIMITIVE, init-value=0, base-type=BT_DCDC_NV_Komponentenfehler_60, compu-method=CM_DCDC_NV_Komponentenfehler_60, data-constr=DC_DCDC_NV_Komponentenfehler_60, transfer-property=PENDING, to BMC_HV(timeout 5 s)  # Übertragung OBD relevanter Fehlerpfade vom Secondary zum Primary Steuergerät. Zuordnung der generischen Komponentenfehler muss zwischen Sender und Empfänger abgestimmt werden.
      frame DCDC_NV_Komponentenfehler_03_XIX_HCP5_CANFD01: id 0x1A5556B2, to BMC_HV, frame-length=8, can-addressing-mode=EXTENDED, can-frame-rx-behavior=CAN-FD, can-frame-tx-behavior=CAN-FD
        pdu DCDC_NV_Komponentenfehler_03_XIX_HCP5_CANFD01: length=8, transmission-mode-true-timing=cyclic-timing={time-offset=0, time-period=0.5}, unused-bit-pattern=0
          signal DCDC_NV_Komponentenfehler_61_XIX_DCDC_NV_Komponentenfehler_03_XIX_HCP5_CANFD01: start 0, 2 bit, little-endian, data-type-policy=OVERRIDE, i-signal-type=PRIMITIVE, init-value=0, base-type=BT_DCDC_NV_Komponentenfehler_61, compu-method=CM_DCDC_NV_Komponentenfehler_61, data-constr=DC_DCDC_NV_Komponentenfehler_61, transfer-property=PENDING, to BMC_HV(timeout 5 s)  # Übertragung OBD relevanter Fehlerpfade vom Secondary zum Primary Steuergerät. Zuordnung der generischen Komponentenfehler muss zwischen Sender und Empfänger abgestimmt werden.
          signal DCDC_NV_Komponentenfehler_62_XIX_DCDC_NV_Komponentenfehler_03_XIX_HCP5_CANFD01: start 2, 2 bit, little-endian, data-type-policy=OVERRIDE, i-signal-type=PRIMITIVE, init-value=0, base-type=BT_DCDC_NV_Komponentenfehler_62, compu-method=CM_DCDC_NV_Komponentenfehler_62, data-constr=DC_DCDC_NV_Komponentenfehler_62, transfer-property=PENDING, to BMC_HV(timeout 5 s)  # Übertragung OBD relevanter Fehlerpfade vom Secondary zum Primary Steuergerät. Zuordnung der generischen Komponentenfehler muss zwischen Sender und Empfänger abgestimmt werden.
          signal DCDC_NV_Komponentenfehler_63_XIX_DCDC_NV_Komponentenfehler_03_XIX_HCP5_CANFD01: start 4, 2 bit, little-endian, data-type-policy=OVERRIDE, i-signal-type=PRIMITIVE, init-value=0, base-type=BT_DCDC_NV_Komponentenfehler_63, compu-method=CM_DCDC_NV_Komponentenfehler_63, data-constr=DC_DCDC_NV_Komponentenfehler_63, transfer-property=PENDING, to BMC_HV(timeout 5 s)  # Übertragung OBD relevanter Fehlerpfade vom Secondary zum Primary Steuergerät. Zuordnung der generischen Komponentenfehler muss zwischen Sender und Empfänger abgestimmt werden.
          signal DCDC_NV_Komponentenfehler_64_XIX_DCDC_NV_Komponentenfehler_03_XIX_HCP5_CANFD01: start 6, 2 bit, little-endian, data-type-policy=OVERRIDE, i-signal-type=PRIMITIVE, init-value=0, base-type=BT_DCDC_NV_Komponentenfehler_64, compu-method=CM_DCDC_NV_Komponentenfehler_64, data-constr=DC_DCDC_NV_Komponentenfehler_64, transfer-property=PENDING, to BMC_HV(timeout 5 s)  # Übertragung OBD relevanter Fehlerpfade vom Secondary zum Primary Steuergerät. Zuordnung der generischen Komponentenfehler muss zwischen Sender und Empfänger abgestimmt werden.
          signal DCDC_NV_Komponentenfehler_65_XIX_DCDC_NV_Komponentenfehler_03_XIX_HCP5_CANFD01: start 8, 2 bit, little-endian, data-type-policy=OVERRIDE, i-signal-type=PRIMITIVE, init-value=0, base-type=BT_DCDC_NV_Komponentenfehler_65, compu-method=CM_DCDC_NV_Komponentenfehler_65, data-constr=DC_DCDC_NV_Komponentenfehler_65, transfer-property=PENDING, to BMC_HV(timeout 5 s)  # Übertragung OBD relevanter Fehlerpfade vom Secondary zum Primary Steuergerät. Zuordnung der generischen Komponentenfehler muss zwischen Sender und Empfänger abgestimmt werden.
          signal DCDC_NV_Komponentenfehler_66_XIX_DCDC_NV_Komponentenfehler_03_XIX_HCP5_CANFD01: start 10, 2 bit, little-endian, data-type-policy=OVERRIDE, i-signal-type=PRIMITIVE, init-value=0, base-type=BT_DCDC_NV_Komponentenfehler_66, compu-method=CM_DCDC_NV_Komponentenfehler_66, data-constr=DC_DCDC_NV_Komponentenfehler_66, transfer-property=PENDING, to BMC_HV(timeout 5 s)  # Übertragung OBD relevanter Fehlerpfade vom Secondary zum Primary Steuergerät. Zuordnung der generischen Komponentenfehler muss zwischen Sender und Empfänger abgestimmt werden.
          signal DCDC_NV_Komponentenfehler_67_XIX_DCDC_NV_Komponentenfehler_03_XIX_HCP5_CANFD01: start 12, 2 bit, little-endian, data-type-policy=OVERRIDE, i-signal-type=PRIMITIVE, init-value=0, base-type=BT_DCDC_NV_Komponentenfehler_67, compu-method=CM_DCDC_NV_Komponentenfehler_67, data-constr=DC_DCDC_NV_Komponentenfehler_67, transfer-property=PENDING, to BMC_HV(timeout 5 s)  # Übertragung OBD relevanter Fehlerpfade vom Secondary zum Primary Steuergerät. Zuordnung der generischen Komponentenfehler muss zwischen Sender und Empfänger abgestimmt werden.
          signal DCDC_NV_Komponentenfehler_68_XIX_DCDC_NV_Komponentenfehler_03_XIX_HCP5_CANFD01: start 14, 2 bit, little-endian, data-type-policy=OVERRIDE, i-signal-type=PRIMITIVE, init-value=0, base-type=BT_DCDC_NV_Komponentenfehler_68, compu-method=CM_DCDC_NV_Komponentenfehler_68, data-constr=DC_DCDC_NV_Komponentenfehler_68, transfer-property=PENDING, to BMC_HV(timeout 5 s)  # Übertragung OBD relevanter Fehlerpfade vom Secondary zum Primary Steuergerät. Zuordnung der generischen Komponentenfehler muss zwischen Sender und Empfänger abgestimmt werden.
          signal DCDC_NV_Komponentenfehler_69_XIX_DCDC_NV_Komponentenfehler_03_XIX_HCP5_CANFD01: start 16, 2 bit, little-endian, data-type-policy=OVERRIDE, i-signal-type=PRIMITIVE, init-value=0, base-type=BT_DCDC_NV_Komponentenfehler_69, compu-method=CM_DCDC_NV_Komponentenfehler_69, data-constr=DC_DCDC_NV_Komponentenfehler_69, transfer-property=PENDING, to BMC_HV(timeout 5 s)  # Übertragung OBD relevanter Fehlerpfade vom Secondary zum Primary Steuergerät. Zuordnung der generischen Komponentenfehler muss zwischen Sender und Empfänger abgestimmt werden.
          signal DCDC_NV_Komponentenfehler_70_XIX_DCDC_NV_Komponentenfehler_03_XIX_HCP5_CANFD01: start 18, 2 bit, little-endian, data-type-policy=OVERRIDE, i-signal-type=PRIMITIVE, init-value=0, base-type=BT_DCDC_NV_Komponentenfehler_70, compu-method=CM_DCDC_NV_Komponentenfehler_70, data-constr=DC_DCDC_NV_Komponentenfehler_70, transfer-property=PENDING, to BMC_HV(timeout 5 s)  # Übertragung OBD relevanter Fehlerpfade vom Secondary zum Primary Steuergerät. Zuordnung der generischen Komponentenfehler muss zwischen Sender und Empfänger abgestimmt werden.
          signal DCDC_NV_Komponentenfehler_71_XIX_DCDC_NV_Komponentenfehler_03_XIX_HCP5_CANFD01: start 20, 2 bit, little-endian, data-type-policy=OVERRIDE, i-signal-type=PRIMITIVE, init-value=0, base-type=BT_DCDC_NV_Komponentenfehler_71, compu-method=CM_DCDC_NV_Komponentenfehler_71, data-constr=DC_DCDC_NV_Komponentenfehler_71, transfer-property=PENDING, to BMC_HV(timeout 5 s)  # Übertragung OBD relevanter Fehlerpfade vom Secondary zum Primary Steuergerät. Zuordnung der generischen Komponentenfehler muss zwischen Sender und Empfänger abgestimmt werden.
          signal DCDC_NV_Komponentenfehler_72_XIX_DCDC_NV_Komponentenfehler_03_XIX_HCP5_CANFD01: start 22, 2 bit, little-endian, data-type-policy=OVERRIDE, i-signal-type=PRIMITIVE, init-value=0, base-type=BT_DCDC_NV_Komponentenfehler_72, compu-method=CM_DCDC_NV_Komponentenfehler_72, data-constr=DC_DCDC_NV_Komponentenfehler_72, transfer-property=PENDING, to BMC_HV(timeout 5 s)  # Übertragung OBD relevanter Fehlerpfade vom Secondary zum Primary Steuergerät. Zuordnung der generischen Komponentenfehler muss zwischen Sender und Empfänger abgestimmt werden.
          signal DCDC_NV_Komponentenfehler_73_XIX_DCDC_NV_Komponentenfehler_03_XIX_HCP5_CANFD01: start 24, 2 bit, little-endian, data-type-policy=OVERRIDE, i-signal-type=PRIMITIVE, init-value=0, base-type=BT_DCDC_NV_Komponentenfehler_73, compu-method=CM_DCDC_NV_Komponentenfehler_73, data-constr=DC_DCDC_NV_Komponentenfehler_73, transfer-property=PENDING, to BMC_HV(timeout 5 s)  # Übertragung OBD relevanter Fehlerpfade vom Secondary zum Primary Steuergerät. Zuordnung der generischen Komponentenfehler muss zwischen Sender und Empfänger abgestimmt werden.
          signal DCDC_NV_Komponentenfehler_74_XIX_DCDC_NV_Komponentenfehler_03_XIX_HCP5_CANFD01: start 26, 2 bit, little-endian, data-type-policy=OVERRIDE, i-signal-type=PRIMITIVE, init-value=0, base-type=BT_DCDC_NV_Komponentenfehler_74, compu-method=CM_DCDC_NV_Komponentenfehler_74, data-constr=DC_DCDC_NV_Komponentenfehler_74, transfer-property=PENDING, to BMC_HV(timeout 5 s)  # Übertragung OBD relevanter Fehlerpfade vom Secondary zum Primary Steuergerät. Zuordnung der generischen Komponentenfehler muss zwischen Sender und Empfänger abgestimmt werden.
          signal DCDC_NV_Komponentenfehler_75_XIX_DCDC_NV_Komponentenfehler_03_XIX_HCP5_CANFD01: start 28, 2 bit, little-endian, data-type-policy=OVERRIDE, i-signal-type=PRIMITIVE, init-value=0, base-type=BT_DCDC_NV_Komponentenfehler_75, compu-method=CM_DCDC_NV_Komponentenfehler_75, data-constr=DC_DCDC_NV_Komponentenfehler_75, transfer-property=PENDING, to BMC_HV(timeout 5 s)  # Übertragung OBD relevanter Fehlerpfade vom Secondary zum Primary Steuergerät. Zuordnung der generischen Komponentenfehler muss zwischen Sender und Empfänger abgestimmt werden.
          signal DCDC_NV_Komponentenfehler_76_XIX_DCDC_NV_Komponentenfehler_03_XIX_HCP5_CANFD01: start 30, 2 bit, little-endian, data-type-policy=OVERRIDE, i-signal-type=PRIMITIVE, init-value=0, base-type=BT_DCDC_NV_Komponentenfehler_76, compu-method=CM_DCDC_NV_Komponentenfehler_76, data-constr=DC_DCDC_NV_Komponentenfehler_76, transfer-property=PENDING, to BMC_HV(timeout 5 s)  # Übertragung OBD relevanter Fehlerpfade vom Secondary zum Primary Steuergerät. Zuordnung der generischen Komponentenfehler muss zwischen Sender und Empfänger abgestimmt werden.
          signal DCDC_NV_Komponentenfehler_77_XIX_DCDC_NV_Komponentenfehler_03_XIX_HCP5_CANFD01: start 32, 2 bit, little-endian, data-type-policy=OVERRIDE, i-signal-type=PRIMITIVE, init-value=0, base-type=BT_DCDC_NV_Komponentenfehler_77, compu-method=CM_DCDC_NV_Komponentenfehler_77, data-constr=DC_DCDC_NV_Komponentenfehler_77, transfer-property=PENDING, to BMC_HV(timeout 5 s)  # Übertragung OBD relevanter Fehlerpfade vom Secondary zum Primary Steuergerät. Zuordnung der generischen Komponentenfehler muss zwischen Sender und Empfänger abgestimmt werden.
          signal DCDC_NV_Komponentenfehler_78_XIX_DCDC_NV_Komponentenfehler_03_XIX_HCP5_CANFD01: start 34, 2 bit, little-endian, data-type-policy=OVERRIDE, i-signal-type=PRIMITIVE, init-value=0, base-type=BT_DCDC_NV_Komponentenfehler_78, compu-method=CM_DCDC_NV_Komponentenfehler_78, data-constr=DC_DCDC_NV_Komponentenfehler_78, transfer-property=PENDING, to BMC_HV(timeout 5 s)  # Übertragung OBD relevanter Fehlerpfade vom Secondary zum Primary Steuergerät. Zuordnung der generischen Komponentenfehler muss zwischen Sender und Empfänger abgestimmt werden.
          signal DCDC_NV_Komponentenfehler_79_XIX_DCDC_NV_Komponentenfehler_03_XIX_HCP5_CANFD01: start 36, 2 bit, little-endian, data-type-policy=OVERRIDE, i-signal-type=PRIMITIVE, init-value=0, base-type=BT_DCDC_NV_Komponentenfehler_79, compu-method=CM_DCDC_NV_Komponentenfehler_79, data-constr=DC_DCDC_NV_Komponentenfehler_79, transfer-property=PENDING, to BMC_HV(timeout 5 s)  # Übertragung OBD relevanter Fehlerpfade vom Secondary zum Primary Steuergerät. Zuordnung der generischen Komponentenfehler muss zwischen Sender und Empfänger abgestimmt werden.
          signal DCDC_NV_Komponentenfehler_80_XIX_DCDC_NV_Komponentenfehler_03_XIX_HCP5_CANFD01: start 38, 2 bit, little-endian, data-type-policy=OVERRIDE, i-signal-type=PRIMITIVE, init-value=0, base-type=BT_DCDC_NV_Komponentenfehler_80, compu-method=CM_DCDC_NV_Komponentenfehler_80, data-constr=DC_DCDC_NV_Komponentenfehler_80, transfer-property=PENDING, to BMC_HV(timeout 5 s)  # Übertragung OBD relevanter Fehlerpfade vom Secondary zum Primary Steuergerät. Zuordnung der generischen Komponentenfehler muss zwischen Sender und Empfänger abgestimmt werden.
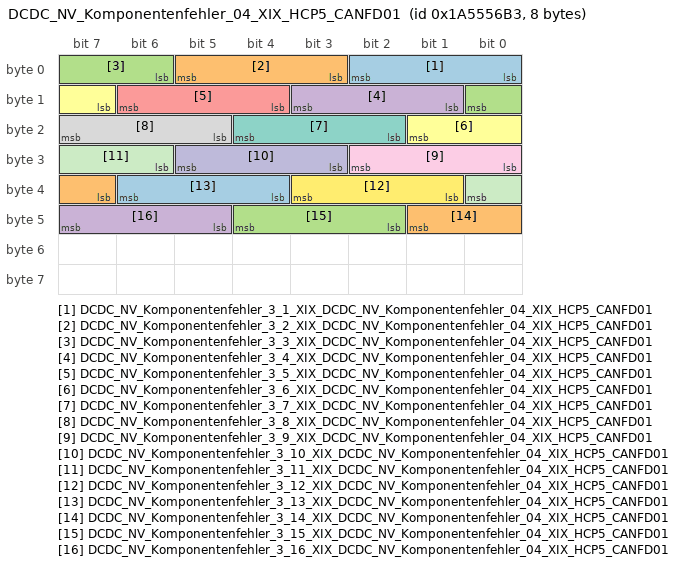
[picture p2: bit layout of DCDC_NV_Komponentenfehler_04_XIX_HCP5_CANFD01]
      frame DCDC_NV_Komponentenfehler_04_XIX_HCP5_CANFD01: id 0x1A5556B3, to BMC_HV, frame-length=8, can-addressing-mode=EXTENDED, can-frame-rx-behavior=CAN-FD, can-frame-tx-behavior=CAN-FD
        pdu DCDC_NV_Komponentenfehler_04_XIX_HCP5_CANFD01: length=8, transmission-mode-true-timing=cyclic-timing={time-offset=0, time-period=0.5}, unused-bit-pattern=0
          signal DCDC_NV_Komponentenfehler_3_1_XIX_DCDC_NV_Komponentenfehler_04_XIX_HCP5_CANFD01: start 0, 3 bit, little-endian, data-type-policy=OVERRIDE, i-signal-type=PRIMITIVE, init-value=0, base-type=BT_DCDC_NV_Komponentenfehler_3_1, compu-method=CM_DCDC_NV_Komponentenfehler_3_1, data-constr=DC_DCDC_NV_Komponentenfehler_3_1, transfer-property=PENDING, to BMC_HV(timeout 5 s)  # Übertragung OBD relevanter Fehlerpfade vom Secondary zum Primary Steuergerät. Zuordnung der generischen Komponentenfehler muss zwischen Sender und Empfänger abgestimmt werden.
          signal DCDC_NV_Komponentenfehler_3_2_XIX_DCDC_NV_Komponentenfehler_04_XIX_HCP5_CANFD01: start 3, 3 bit, little-endian, data-type-policy=OVERRIDE, i-signal-type=PRIMITIVE, init-value=0, base-type=BT_DCDC_NV_Komponentenfehler_3_2, compu-method=CM_DCDC_NV_Komponentenfehler_3_2, data-constr=DC_DCDC_NV_Komponentenfehler_3_2, transfer-property=PENDING, to BMC_HV(timeout 5 s)  # Übertragung OBD relevanter Fehlerpfade vom Secondary zum Primary Steuergerät. Zuordnung der generischen Komponentenfehler muss zwischen Sender und Empfänger abgestimmt werden.
          signal DCDC_NV_Komponentenfehler_3_3_XIX_DCDC_NV_Komponentenfehler_04_XIX_HCP5_CANFD01: start 6, 3 bit, little-endian, data-type-policy=OVERRIDE, i-signal-type=PRIMITIVE, init-value=0, base-type=BT_DCDC_NV_Komponentenfehler_3_3, compu-method=CM_DCDC_NV_Komponentenfehler_3_3, data-constr=DC_DCDC_NV_Komponentenfehler_3_3, transfer-property=PENDING, to BMC_HV(timeout 5 s)  # Übertragung OBD relevanter Fehlerpfade vom Secondary zum Primary Steuergerät. Zuordnung der generischen Komponentenfehler muss zwischen Sender und Empfänger abgestimmt werden.
          signal DCDC_NV_Komponentenfehler_3_4_XIX_DCDC_NV_Komponentenfehler_04_XIX_HCP5_CANFD01: start 9, 3 bit, little-endian, data-type-policy=OVERRIDE, i-signal-type=PRIMITIVE, init-value=0, base-type=BT_DCDC_NV_Komponentenfehler_3_4, compu-method=CM_DCDC_NV_Komponentenfehler_3_4, data-constr=DC_DCDC_NV_Komponentenfehler_3_4, transfer-property=PENDING, to BMC_HV(timeout 5 s)  # Übertragung OBD relevanter Fehlerpfade vom Secondary zum Primary Steuergerät. Zuordnung der generischen Komponentenfehler muss zwischen Sender und Empfänger abgestimmt werden.
          signal DCDC_NV_Komponentenfehler_3_5_XIX_DCDC_NV_Komponentenfehler_04_XIX_HCP5_CANFD01: start 12, 3 bit, little-endian, data-type-policy=OVERRIDE, i-signal-type=PRIMITIVE, init-value=0, base-type=BT_DCDC_NV_Komponentenfehler_3_5, compu-method=CM_DCDC_NV_Komponentenfehler_3_5, data-constr=DC_DCDC_NV_Komponentenfehler_3_5, transfer-property=PENDING, to BMC_HV(timeout 5 s)  # Übertragung OBD relevanter Fehlerpfade vom Secondary zum Primary Steuergerät. Zuordnung der generischen Komponentenfehler muss zwischen Sender und Empfänger abgestimmt werden.
          signal DCDC_NV_Komponentenfehler_3_6_XIX_DCDC_NV_Komponentenfehler_04_XIX_HCP5_CANFD01: start 15, 3 bit, little-endian, data-type-policy=OVERRIDE, i-signal-type=PRIMITIVE, init-value=0, base-type=BT_DCDC_NV_Komponentenfehler_3_6, compu-method=CM_DCDC_NV_Komponentenfehler_3_6, data-constr=DC_DCDC_NV_Komponentenfehler_3_6, transfer-property=PENDING, to BMC_HV(timeout 5 s)  # Übertragung OBD relevanter Fehlerpfade vom Secondary zum Primary Steuergerät. Zuordnung der generischen Komponentenfehler muss zwischen Sender und Empfänger abgestimmt werden.
          signal DCDC_NV_Komponentenfehler_3_7_XIX_DCDC_NV_Komponentenfehler_04_XIX_HCP5_CANFD01: start 18, 3 bit, little-endian, data-type-policy=OVERRIDE, i-signal-type=PRIMITIVE, init-value=0, base-type=BT_DCDC_NV_Komponentenfehler_3_7, compu-method=CM_DCDC_NV_Komponentenfehler_3_7, data-constr=DC_DCDC_NV_Komponentenfehler_3_7, transfer-property=PENDING, to BMC_HV(timeout 5 s)  # Übertragung OBD relevanter Fehlerpfade vom Secondary zum Primary Steuergerät. Zuordnung der generischen Komponentenfehler muss zwischen Sender und Empfänger abgestimmt werden.
          signal DCDC_NV_Komponentenfehler_3_8_XIX_DCDC_NV_Komponentenfehler_04_XIX_HCP5_CANFD01: start 21, 3 bit, little-endian, data-type-policy=OVERRIDE, i-signal-type=PRIMITIVE, init-value=0, base-type=BT_DCDC_NV_Komponentenfehler_3_8, compu-method=CM_DCDC_NV_Komponentenfehler_3_8, data-constr=DC_DCDC_NV_Komponentenfehler_3_8, transfer-property=PENDING, to BMC_HV(timeout 5 s)  # Übertragung OBD relevanter Fehlerpfade vom Secondary zum Primary Steuergerät. Zuordnung der generischen Komponentenfehler muss zwischen Sender und Empfänger abgestimmt werden.
          signal DCDC_NV_Komponentenfehler_3_9_XIX_DCDC_NV_Komponentenfehler_04_XIX_HCP5_CANFD01: start 24, 3 bit, little-endian, data-type-policy=OVERRIDE, i-signal-type=PRIMITIVE, init-value=0, base-type=BT_DCDC_NV_Komponentenfehler_3_9, compu-method=CM_DCDC_NV_Komponentenfehler_3_9, data-constr=DC_DCDC_NV_Komponentenfehler_3_9, transfer-property=PENDING, to BMC_HV(timeout 5 s)  # Übertragung OBD relevanter Fehlerpfade vom Secondary zum Primary Steuergerät. Zuordnung der generischen Komponentenfehler muss zwischen Sender und Empfänger abgestimmt werden.
          signal DCDC_NV_Komponentenfehler_3_10_XIX_DCDC_NV_Komponentenfehler_04_XIX_HCP5_CANFD01: start 27, 3 bit, little-endian, data-type-policy=OVERRIDE, i-signal-type=PRIMITIVE, init-value=0, base-type=BT_DCDC_NV_Komponentenfehler_3_10, compu-method=CM_DCDC_NV_Komponentenfehler_3_10, data-constr=DC_DCDC_NV_Komponentenfehler_3_10, transfer-property=PENDING, to BMC_HV(timeout 5 s)  # Übertragung OBD relevanter Fehlerpfade vom Secondary zum Primary Steuergerät. Zuordnung der generischen Komponentenfehler muss zwischen Sender und Empfänger abgestimmt werden.
          signal DCDC_NV_Komponentenfehler_3_11_XIX_DCDC_NV_Komponentenfehler_04_XIX_HCP5_CANFD01: start 30, 3 bit, little-endian, data-type-policy=OVERRIDE, i-signal-type=PRIMITIVE, init-value=0, base-type=BT_DCDC_NV_Komponentenfehler_3_11, compu-method=CM_DCDC_NV_Komponentenfehler_3_11, data-constr=DC_DCDC_NV_Komponentenfehler_3_11, transfer-property=PENDING, to BMC_HV(timeout 5 s)  # Übertragung OBD relevanter Fehlerpfade vom Secondary zum Primary Steuergerät. Zuordnung der generischen Komponentenfehler muss zwischen Sender und Empfänger abgestimmt werden.
          signal DCDC_NV_Komponentenfehler_3_12_XIX_DCDC_NV_Komponentenfehler_04_XIX_HCP5_CANFD01: start 33, 3 bit, little-endian, data-type-policy=OVERRIDE, i-signal-type=PRIMITIVE, init-value=0, base-type=BT_DCDC_NV_Komponentenfehler_3_12, compu-method=CM_DCDC_NV_Komponentenfehler_3_12, data-constr=DC_DCDC_NV_Komponentenfehler_3_12, transfer-property=PENDING, to BMC_HV(timeout 5 s)  # Übertragung OBD relevanter Fehlerpfade vom Secondary zum Primary Steuergerät. Zuordnung der generischen Komponentenfehler muss zwischen Sender und Empfänger abgestimmt werden.
          signal DCDC_NV_Komponentenfehler_3_13_XIX_DCDC_NV_Komponentenfehler_04_XIX_HCP5_CANFD01: start 36, 3 bit, little-endian, data-type-policy=OVERRIDE, i-signal-type=PRIMITIVE, init-value=0, base-type=BT_DCDC_NV_Komponentenfehler_3_13, compu-method=CM_DCDC_NV_Komponentenfehler_3_13, data-constr=DC_DCDC_NV_Komponentenfehler_3_13, transfer-property=PENDING, to BMC_HV(timeout 5 s)  # Übertragung OBD relevanter Fehlerpfade vom Secondary zum Primary Steuergerät. Zuordnung der generischen Komponentenfehler muss zwischen Sender und Empfänger abgestimmt werden.
          signal DCDC_NV_Komponentenfehler_3_14_XIX_DCDC_NV_Komponentenfehler_04_XIX_HCP5_CANFD01: start 39, 3 bit, little-endian, data-type-policy=OVERRIDE, i-signal-type=PRIMITIVE, init-value=0, base-type=BT_DCDC_NV_Komponentenfehler_3_14, compu-method=CM_DCDC_NV_Komponentenfehler_3_14, data-constr=DC_DCDC_NV_Komponentenfehler_3_14, transfer-property=PENDING, to BMC_HV(timeout 5 s)  # Übertragung OBD relevanter Fehlerpfade vom Secondary zum Primary Steuergerät. Zuordnung der generischen Komponentenfehler muss zwischen Sender und Empfänger abgestimmt werden.
          signal DCDC_NV_Komponentenfehler_3_15_XIX_DCDC_NV_Komponentenfehler_04_XIX_HCP5_CANFD01: start 42, 3 bit, little-endian, data-type-policy=OVERRIDE, i-signal-type=PRIMITIVE, init-value=0, base-type=BT_DCDC_NV_Komponentenfehler_3_15, compu-method=CM_DCDC_NV_Komponentenfehler_3_15, data-constr=DC_DCDC_NV_Komponentenfehler_3_15, transfer-property=PENDING, to BMC_HV(timeout 5 s)  # Übertragung OBD relevanter Fehlerpfade vom Secondary zum Primary Steuergerät. Zuordnung der generischen Komponentenfehler muss zwischen Sender und Empfänger abgestimmt werden.
          signal DCDC_NV_Komponentenfehler_3_16_XIX_DCDC_NV_Komponentenfehler_04_XIX_HCP5_CANFD01: start 45, 3 bit, little-endian, data-type-policy=OVERRIDE, i-signal-type=PRIMITIVE, init-value=0, base-type=BT_DCDC_NV_Komponentenfehler_3_16, compu-method=CM_DCDC_NV_Komponentenfehler_3_16, data-constr=DC_DCDC_NV_Komponentenfehler_3_16, transfer-property=PENDING, to BMC_HV(timeout 5 s)  # Übertragung OBD relevanter Fehlerpfade vom Secondary zum Primary Steuergerät. Zuordnung der generischen Komponentenfehler muss zwischen Sender und Empfänger abgestimmt werden.
      frame DEV_BJB_Req_01_XIX_HCP5_CANFD01: id 0x18FED000, to BMC_HV, frame-length=8, can-addressing-mode=EXTENDED, can-frame-rx-behavior=CAN-FD, can-frame-tx-behavior=CAN-FD
        user defined pdu CDD_DEV_BJB_Req_01_XIX_HCP5_CANFD01: length=8, cdd-type=EID
      frame DEV_BJB_Resp_FF_XIX_HCP5_CANFD01: id 0x18FED0FF, from BMC_HV, frame-length=8, can-addressing-mode=EXTENDED, can-frame-rx-behavior=CAN-FD, can-frame-tx-behavior=CAN-FD
        user defined pdu CDD_DEV_BJB_Resp_FF_XIX_HCP5_CANFD01: length=8, cdd-type=EID
      frame DEV_Hybrid_01_Req_00_XIX_HCP5_CANFD01: id 0x1BFC6300, to BMC_HV, frame-length=64, can-addressing-mode=EXTENDED, can-frame-rx-behavior=CAN-FD, can-frame-tx-behavior=CAN-FD
        pdu DEV_Hybrid_01_Req_00_XIX_HCP5_CANFD01: length=64, transmission-mode-true-timing=event-controlled-timing={number-of-repetitions=0, repetition-period=0}, unused-bit-pattern=0
          signal DEV_Hybrid_01_Req_00_FD_Data_XIX_DEV_Hybrid_01_Req_00_XIX_HCP5_CANFD01: start 0, 512 bit, opaque, data-type-policy=OVERRIDE, i-signal-type=ARRAY, init-value=64 x 0, base-type=BT_DEV_Hybrid_01_Req_00_FD_Data, implementation-data-type=DEV_Hybrid_01_Req_00_FD_Data, transfer-property=TRIGGERED-ON-CHANGE-WITHOUT-REPETITION, to BMC_HV
      frame DEV_Hybrid_01_Resp_FF_XIX_HCP5_CANFD01: id 0x1BFC63FF, from BMC_HV, frame-length=64, can-addressing-mode=EXTENDED, can-frame-rx-behavior=CAN-FD, can-frame-tx-behavior=CAN-FD
        pdu DEV_Hybrid_01_Resp_FF_XIX_HCP5_CANFD01: length=64, transmission-mode-true-timing=event-controlled-timing={number-of-repetitions=0, repetition-period=0}, unused-bit-pattern=0
          signal DEV_Hybrid_01_Resp_FF_FD_Data_XIX_DEV_Hybrid_01_Resp_FF_XIX_HCP5_CANFD01: start 0, 512 bit, opaque, data-type-policy=OVERRIDE, i-signal-type=ARRAY, init-value=64 x 0, base-type=BT_DEV_Hybrid_01_Resp_FF_FD_Data, implementation-data-type=DEV_Hybrid_01_Resp_FF_FD_Data, transfer-property=TRIGGERED-ON-CHANGE-WITHOUT-REPETITION
      frame DIA_BJB_Req_XIX_HCP5_CANFD01: id 0x17FC16D0, to BMC_HV, frame-length=8, can-addressing-mode=EXTENDED, can-frame-rx-behavior=CAN-FD, can-frame-tx-behavior=CAN-FD
        n pdu DIA_BJB_Req_XIX_HCP5_CANFD01: length=8
      frame DIA_BJB_Resp_XIX_HCP5_CANFD01: id 0x17FE16D0, from BMC_HV, frame-length=8, can-addressing-mode=EXTENDED, can-frame-rx-behavior=CAN-FD, can-frame-tx-behavior=CAN-FD
        n pdu DIA_BJB_Resp_XIX_HCP5_CANFD01: length=8
      frame DIA_UI2Sens01_Req_XIX_HCP5_CANFD01: id 0x17FC17B1, to BMC_HV, frame-length=8, can-addressing-mode=EXTENDED, can-frame-rx-behavior=CAN-FD, can-frame-tx-behavior=CAN-FD
        n pdu DIA_UI2Sens01_Req_XIX_HCP5_CANFD01: length=8
      frame DIA_UI2Sens01_Resp_XIX_HCP5_CANFD01: id 0x17FE17B1, from BMC_HV, frame-length=8, can-addressing-mode=EXTENDED, can-frame-rx-behavior=CAN-FD, can-frame-tx-behavior=CAN-FD
        n pdu DIA_UI2Sens01_Resp_XIX_HCP5_CANFD01: length=8
      frame DIA_UI2Sens02_Req_XIX_HCP5_CANFD01: id 0x17FC17B2, to BMC_HV, frame-length=8, can-addressing-mode=EXTENDED, can-frame-rx-behavior=CAN-FD, can-frame-tx-behavior=CAN-FD
        n pdu DIA_UI2Sens02_Req_XIX_HCP5_CANFD01: length=8
      frame DIA_UI2Sens02_Resp_XIX_HCP5_CANFD01: id 0x17FE17B2, from BMC_HV, frame-length=8, can-addressing-mode=EXTENDED, can-frame-rx-behavior=CAN-FD, can-frame-tx-behavior=CAN-FD
        n pdu DIA_UI2Sens02_Resp_XIX_HCP5_CANFD01: length=8
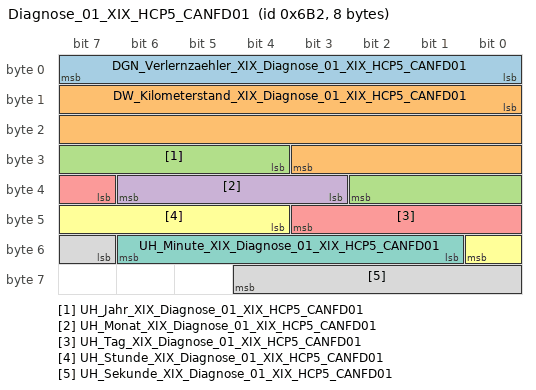
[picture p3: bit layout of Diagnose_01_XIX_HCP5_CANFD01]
      frame Diagnose_01_XIX_HCP5_CANFD01: id 0x6B2, to BMC_HV, frame-length=8, can-addressing-mode=STANDARD, can-frame-rx-behavior=CAN-FD, can-frame-tx-behavior=CAN-FD
        pdu Diagnose_01_XIX_HCP5_CANFD01: length=8, transmission-mode-true-timing=cyclic-timing={time-offset=0, time-period=1}, unused-bit-pattern=0
          signal DGN_Verlernzaehler_XIX_Diagnose_01_XIX_HCP5_CANFD01: start 0, 8 bit, little-endian, data-type-policy=OVERRIDE, i-signal-type=PRIMITIVE, init-value=0, base-type=BT_DGN_Verlernzaehler, compu-method=CM_DGN_Verlernzaehler, data-constr=DC_DGN_Verlernzaehler, transfer-property=PENDING  # wrap around 254 --> 0
          signal DW_Kilometerstand_XIX_Diagnose_01_XIX_HCP5_CANFD01: start 8, 20 bit, little-endian, data-type-policy=OVERRIDE, i-signal-type=PRIMITIVE, init-value=1048574, base-type=BT_DW_Kilometerstand, invalid-value=Invalid_DW_Kilometerstand_XIX_Diagnose_01_XIX_HCP5_CANFD01:1048575, compu-method=CM_DW_Kilometerstand, data-constr=DC_DW_Kilometerstand, unit=Unit_Unit_KiloMeter, transfer-property=PENDING, to BMC_HV(timeout 5 s)  # Fehler wird ausgegeben, falls Kilometerstand nicht restaurierbar
          signal UH_Jahr_XIX_Diagnose_01_XIX_HCP5_CANFD01: start 28, 7 bit, little-endian, data-type-policy=OVERRIDE, i-signal-type=PRIMITIVE, init-value=0, base-type=BT_UH_Jahr, compu-method=CM_UH_Jahr, data-constr=DC_UH_Jahr, unit=Unit_Unit_Year, transfer-property=PENDING, to BMC_HV(timeout 5 s)
          signal UH_Monat_XIX_Diagnose_01_XIX_HCP5_CANFD01: start 35, 4 bit, little-endian, data-type-policy=OVERRIDE, i-signal-type=PRIMITIVE, init-value=0, base-type=BT_UH_Monat, invalid-value=Invalid_UH_Monat_XIX_Diagnose_01_XIX_HCP5_CANFD01:15, compu-method=CM_UH_Monat, data-constr=DC_UH_Monat, unit=Unit_Unit_Month, transfer-property=PENDING, to BMC_HV(timeout 5 s)  # 0x0D, 0xF = Werte ungültig 0x0E = Relatives Datum (nur VW)
          signal UH_Tag_XIX_Diagnose_01_XIX_HCP5_CANFD01: start 39, 5 bit, little-endian, data-type-policy=OVERRIDE, i-signal-type=PRIMITIVE, init-value=0, base-type=BT_UH_Tag, compu-method=CM_UH_Tag, data-constr=DC_UH_Tag, unit=Unit_Unit_Day, transfer-property=PENDING, to BMC_HV(timeout 5 s)  # 0x0: reserviert bei VW
          signal UH_Stunde_XIX_Diagnose_01_XIX_HCP5_CANFD01: start 44, 5 bit, little-endian, data-type-policy=OVERRIDE, i-signal-type=PRIMITIVE, init-value=0, base-type=BT_UH_Stunde, compu-method=CM_UH_Stunde, data-constr=DC_UH_Stunde, unit=Unit_Unit_Hours, transfer-property=PENDING, to BMC_HV(timeout 5 s)  # 0x18 - 0x1F = Werte ungültig
          signal UH_Minute_XIX_Diagnose_01_XIX_HCP5_CANFD01: start 49, 6 bit, little-endian, data-type-policy=OVERRIDE, i-signal-type=PRIMITIVE, init-value=0, base-type=BT_UH_Minute, compu-method=CM_UH_Minute, data-constr=DC_UH_Minute, unit=Unit_Unit_Minut, transfer-property=PENDING, to BMC_HV(timeout 5 s)  # 0x3C- 0x3f = Werte ungültig
          signal UH_Sekunde_XIX_Diagnose_01_XIX_HCP5_CANFD01: start 55, 6 bit, little-endian, data-type-policy=OVERRIDE, i-signal-type=PRIMITIVE, init-value=0, base-type=BT_UH_Sekunde, compu-method=CM_UH_Sekunde, data-constr=DC_UH_Sekunde, unit=Unit_Unit_Secon, transfer-property=PENDING, to BMC_HV(timeout 5 s)  # 0x3C- 0x3f = Werte ungültig
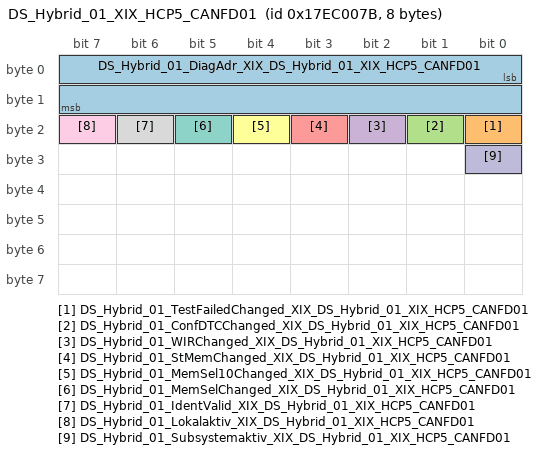
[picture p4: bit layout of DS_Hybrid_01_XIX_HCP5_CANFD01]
      frame DS_Hybrid_01_XIX_HCP5_CANFD01: id 0x17EC007B, from BMC_HV, frame-length=8, can-addressing-mode=EXTENDED, can-frame-rx-behavior=CAN-FD, can-frame-tx-behavior=CAN-FD
        pdu DS_Hybrid_01_XIX_HCP5_CANFD01: length=8, minimum-delay=0.08, transmission-mode-true-timing={cyclic-timing={time-offset=0, time-period=1}, event-controlled-timing={number-of-repetitions=0, repetition-period=0}}, unused-bit-pattern=0
          signal DS_Hybrid_01_DiagAdr_XIX_DS_Hybrid_01_XIX_HCP5_CANFD01: start 0, 16 bit, little-endian, data-type-policy=OVERRIDE, i-signal-type=PRIMITIVE, init-value=140, base-type=BT_DS_Hybrid_01_DiagAdr, compu-method=CM_DS_Hybrid_01_DiagAdr, data-constr=DC_DS_Hybrid_01_DiagAdr, transfer-property=PENDING  # Übertragung vom Diagnosestatus gem. 80114
          signal DS_Hybrid_01_TestFailedChanged_XIX_DS_Hybrid_01_XIX_HCP5_CANFD01: start 16, 1 bit, little-endian, data-type-policy=OVERRIDE, i-signal-type=PRIMITIVE, init-value=0, base-type=BT_DS_Hybrid_01_TestFailedChanged, compu-method=CM_DS_Hybrid_01_TestFailedChanged, data-constr=DC_DS_Hybrid_01_TestFailedChanged, transfer-property=TRIGGERED-ON-CHANGE-WITHOUT-REPETITION  # Übertragung vom Diagnosestatus gem. 80114
          signal DS_Hybrid_01_ConfDTCChanged_XIX_DS_Hybrid_01_XIX_HCP5_CANFD01: start 17, 1 bit, little-endian, data-type-policy=OVERRIDE, i-signal-type=PRIMITIVE, init-value=0, base-type=BT_DS_Hybrid_01_ConfDTCChanged, compu-method=CM_DS_Hybrid_01_ConfDTCChanged, data-constr=DC_DS_Hybrid_01_ConfDTCChanged, transfer-property=TRIGGERED-ON-CHANGE-WITHOUT-REPETITION  # Übertragung vom Diagnosestatus gem. 80114
          signal DS_Hybrid_01_WIRChanged_XIX_DS_Hybrid_01_XIX_HCP5_CANFD01: start 18, 1 bit, little-endian, data-type-policy=OVERRIDE, i-signal-type=PRIMITIVE, init-value=0, base-type=BT_DS_Hybrid_01_WIRChanged, compu-method=CM_DS_Hybrid_01_WIRChanged, data-constr=DC_DS_Hybrid_01_WIRChanged, transfer-property=TRIGGERED-ON-CHANGE-WITHOUT-REPETITION  # Übertragung vom Diagnosestatus gem. 80114
          signal DS_Hybrid_01_StMemChanged_XIX_DS_Hybrid_01_XIX_HCP5_CANFD01: start 19, 1 bit, little-endian, data-type-policy=OVERRIDE, i-signal-type=PRIMITIVE, init-value=0, base-type=BT_DS_Hybrid_01_StMemChanged, compu-method=CM_DS_Hybrid_01_StMemChanged, data-constr=DC_DS_Hybrid_01_StMemChanged, transfer-property=TRIGGERED-ON-CHANGE-WITHOUT-REPETITION  # Übertragung vom Diagnosestatus gem. 80114
          signal DS_Hybrid_01_MemSel10Changed_XIX_DS_Hybrid_01_XIX_HCP5_CANFD01: start 20, 1 bit, little-endian, data-type-policy=OVERRIDE, i-signal-type=PRIMITIVE, init-value=0, base-type=BT_DS_Hybrid_01_MemSel10Changed, compu-method=CM_DS_Hybrid_01_MemSel10Changed, data-constr=DC_DS_Hybrid_01_MemSel10Changed, transfer-property=TRIGGERED-ON-CHANGE-WITHOUT-REPETITION  # Übertragung vom Diagnosestatus gem. 80114
          signal DS_Hybrid_01_MemSelChanged_XIX_DS_Hybrid_01_XIX_HCP5_CANFD01: start 21, 1 bit, little-endian, data-type-policy=OVERRIDE, i-signal-type=PRIMITIVE, init-value=0, base-type=BT_DS_Hybrid_01_MemSelChanged, compu-method=CM_DS_Hybrid_01_MemSelChanged, data-constr=DC_DS_Hybrid_01_MemSelChanged, transfer-property=TRIGGERED-ON-CHANGE-WITHOUT-REPETITION  # Übertragung vom Diagnosestatus gem. 80114
          signal DS_Hybrid_01_IdentValid_XIX_DS_Hybrid_01_XIX_HCP5_CANFD01: start 22, 1 bit, little-endian, data-type-policy=OVERRIDE, i-signal-type=PRIMITIVE, init-value=1, base-type=BT_DS_Hybrid_01_IdentValid, compu-method=CM_DS_Hybrid_01_IdentValid, data-constr=DC_DS_Hybrid_01_IdentValid, transfer-property=TRIGGERED-ON-CHANGE-WITHOUT-REPETITION  # Signalisiert ob die Identifikationsdaten gueltig sind
          signal DS_Hybrid_01_Lokalaktiv_XIX_DS_Hybrid_01_XIX_HCP5_CANFD01: start 23, 1 bit, little-endian, data-type-policy=OVERRIDE, i-signal-type=PRIMITIVE, init-value=0, base-type=BT_DS_Hybrid_01_Lokalaktiv, compu-method=CM_DS_Hybrid_01_Lokalaktiv, data-constr=DC_DS_Hybrid_01_Lokalaktiv, transfer-property=PENDING  # Zeigt an ob das SG nach Klemme15 AUS und nach entsprechender MAX Aktivzeit noch aktiv war.
          signal DS_Hybrid_01_Subsystemaktiv_XIX_DS_Hybrid_01_XIX_HCP5_CANFD01: start 24, 1 bit, little-endian, data-type-policy=OVERRIDE, i-signal-type=PRIMITIVE, init-value=0, base-type=BT_DS_Hybrid_01_Subsystemaktiv, compu-method=CM_DS_Hybrid_01_Subsystemaktiv, data-constr=DC_DS_Hybrid_01_Subsystemaktiv, transfer-property=PENDING  # Zeigt an ob ein Subsystem des SGs nach Klemme15 AUS und nach entsprechender MAX Aktivzeit noch aktiv war
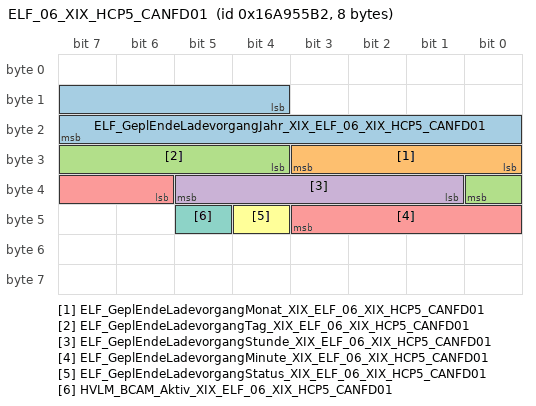
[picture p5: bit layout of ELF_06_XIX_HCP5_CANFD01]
      frame ELF_06_XIX_HCP5_CANFD01: id 0x16A955B2, to BMC_HV, frame-length=8, can-addressing-mode=EXTENDED, can-frame-rx-behavior=CAN-FD, can-frame-tx-behavior=CAN-FD
        pdu ELF_06_XIX_HCP5_CANFD01: length=8, transmission-mode-true-timing=cyclic-timing={time-offset=0, time-period=0.2}, unused-bit-pattern=0
          signal ELF_GeplEndeLadevorgangJahr_XIX_ELF_06_XIX_HCP5_CANFD01: start 12, 12 bit, little-endian, data-type-policy=OVERRIDE, i-signal-type=PRIMITIVE, init-value=4095, base-type=BT_ELF_GeplEndeLadevorgangJahr, compu-method=CM_ELF_GeplEndeLadevorgangJahr, data-constr=DC_ELF_GeplEndeLadevorgangJahr, unit=Unit_Unit_Year, transfer-property=PENDING  # Geplantes Ende des Ladevorgangs bei Laden nach Ladeplan, Jahr.
          signal ELF_GeplEndeLadevorgangMonat_XIX_ELF_06_XIX_HCP5_CANFD01: start 24, 4 bit, little-endian, data-type-policy=OVERRIDE, i-signal-type=PRIMITIVE, init-value=15, base-type=BT_ELF_GeplEndeLadevorgangMonat, compu-method=CM_ELF_GeplEndeLadevorgangMonat, data-constr=DC_ELF_GeplEndeLadevorgangMonat, unit=Unit_Unit_Month, transfer-property=PENDING  # Geplantes Ende bei Laden nach Ladeplan(Monat).
          signal ELF_GeplEndeLadevorgangTag_XIX_ELF_06_XIX_HCP5_CANFD01: start 28, 5 bit, little-endian, data-type-policy=OVERRIDE, i-signal-type=PRIMITIVE, init-value=0, base-type=BT_ELF_GeplEndeLadevorgangTag, compu-method=CM_ELF_GeplEndeLadevorgangTag, data-constr=DC_ELF_GeplEndeLadevorgangTag, unit=Unit_Unit_Day, transfer-property=PENDING  # Geplantes Ladeende bei Laden nach Ladeplan (Tag).
          signal ELF_GeplEndeLadevorgangStunde_XIX_ELF_06_XIX_HCP5_CANFD01: start 33, 5 bit, little-endian, data-type-policy=OVERRIDE, i-signal-type=PRIMITIVE, init-value=31, base-type=BT_ELF_GeplEndeLadevorgangStunde, compu-method=CM_ELF_GeplEndeLadevorgangStunde, data-constr=DC_ELF_GeplEndeLadevorgangStunde, unit=Unit_Unit_Hours, transfer-property=PENDING  # Geplantes Ladeende bei Laden nach Ladeplan, Stunde.
          signal ELF_GeplEndeLadevorgangMinute_XIX_ELF_06_XIX_HCP5_CANFD01: start 38, 6 bit, little-endian, data-type-policy=OVERRIDE, i-signal-type=PRIMITIVE, init-value=63, base-type=BT_ELF_GeplEndeLadevorgangMinute, compu-method=CM_ELF_GeplEndeLadevorgangMinute, data-constr=DC_ELF_GeplEndeLadevorgangMinute, unit=Unit_Unit_Minut, transfer-property=PENDING  # Geplantes Ladeende bei Laden nach Ladeplan, Minute.
          signal ELF_GeplEndeLadevorgangStatus_XIX_ELF_06_XIX_HCP5_CANFD01: start 44, 1 bit, little-endian, data-type-policy=OVERRIDE, i-signal-type=PRIMITIVE, init-value=0, base-type=BT_ELF_GeplEndeLadevorgangStatus, compu-method=CM_ELF_GeplEndeLadevorgangStatus, data-constr=DC_ELF_GeplEndeLadevorgangStatus, transfer-property=PENDING  # Gibt den Status des geplanten Ladeendes an und ob die hinterlegte Startzeit berücksichtigt werden soll.
          signal HVLM_BCAM_Aktiv_XIX_ELF_06_XIX_HCP5_CANFD01: start 45, 1 bit, little-endian, data-type-policy=OVERRIDE, i-signal-type=PRIMITIVE, init-value=0, base-type=BT_HVLM_BCAM_Aktiv, compu-method=CM_HVLM_BCAM_Aktiv, data-constr=DC_HVLM_BCAM_Aktiv, transfer-property=PENDING, to BMC_HV(timeout 2 s)  # Dieses Signal gibt den Aktivierungsstatus des Battery Charging Care Modes an und gehört zum HV-Laden
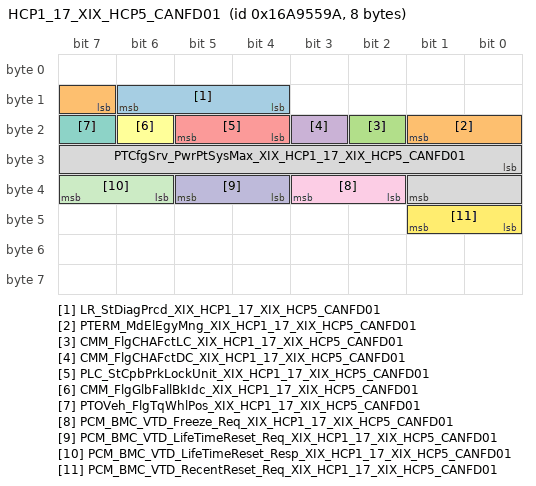
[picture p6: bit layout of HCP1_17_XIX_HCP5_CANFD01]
      frame HCP1_17_XIX_HCP5_CANFD01: id 0x16A9559A, to BMC_HV, frame-length=8, can-addressing-mode=EXTENDED, can-frame-rx-behavior=CAN-FD, can-frame-tx-behavior=CAN-FD
        pdu HCP1_17_XIX_HCP5_CANFD01: length=8, minimum-delay=0.1, transmission-mode-true-timing={cyclic-timing={time-offset=0, time-period=1}, event-controlled-timing={number-of-repetitions=0, repetition-period=0}}, unused-bit-pattern=0
          signal LR_StDiagPrcd_XIX_HCP1_17_XIX_HCP5_CANFD01: start 12, 3 bit, little-endian, data-type-policy=OVERRIDE, i-signal-type=PRIMITIVE, init-value=6, base-type=BT_LR_StDiagPrcd, invalid-value=Invalid_LR_StDiagPrcd_XIX_HCP1_17_XIX_HCP5_CANFD01:7, compu-method=CM_LR_StDiagPrcd, data-constr=DC_LR_StDiagPrcd, transfer-property=PENDING  # State of DMPLR component test
          signal PTERM_MdElEgyMng_XIX_HCP1_17_XIX_HCP5_CANFD01: start 15, 3 bit, little-endian, data-type-policy=OVERRIDE, i-signal-type=PRIMITIVE, init-value=0, base-type=BT_PTERM_MdElEgyMng, compu-method=CM_PTERM_MdElEgyMng, data-constr=DC_PTERM_MdElEgyMng, transfer-property=TRIGGERED-ON-CHANGE-WITHOUT-REPETITION  # mode of electic engergy management
          signal CMM_FlgCHAFctLC_XIX_HCP1_17_XIX_HCP5_CANFD01: start 18, 1 bit, little-endian, data-type-policy=OVERRIDE, i-signal-type=PRIMITIVE, init-value=0, base-type=BT_CMM_FlgCHAFctLC, compu-method=CM_CMM_FlgCHAFctLC, data-constr=DC_CMM_FlgCHAFctLC, transfer-property=TRIGGERED-ON-CHANGE-WITHOUT-REPETITION  # Signal to distinguish between LC system low and high. Information if LC is coded for charisma or not.
          signal CMM_FlgCHAFctDC_XIX_HCP1_17_XIX_HCP5_CANFD01: start 19, 1 bit, little-endian, data-type-policy=OVERRIDE, i-signal-type=PRIMITIVE, init-value=0, base-type=BT_CMM_FlgCHAFctDC, compu-method=CM_CMM_FlgCHAFctDC, data-constr=DC_CMM_FlgCHAFctDC, transfer-property=TRIGGERED-ON-CHANGE-WITHOUT-REPETITION  # Signal to distinguish between DC system low and high. Information if DC is coded for charisma or not.
          signal PLC_StCpbPrkLockUnit_XIX_HCP1_17_XIX_HCP5_CANFD01: start 20, 2 bit, little-endian, data-type-policy=OVERRIDE, i-signal-type=PRIMITIVE, init-value=2, base-type=BT_PLC_StCpbPrkLockUnit, invalid-value=Invalid_PLC_StCpbPrkLockUnit_XIX_HCP1_17_XIX_HCP5_CANFD01:3, compu-method=CM_PLC_StCpbPrkLockUnit, data-constr=DC_PLC_StCpbPrkLockUnit, transfer-property=TRIGGERED-ON-CHANGE-WITHOUT-REPETITION  # Beschreibt die Fähigkeit der Parksperreneinheit zu Verfahren und die eingenommene Position korrekt zu melden.
          signal CMM_FlgGlbFallBkIdc_XIX_HCP1_17_XIX_HCP5_CANFD01: start 22, 1 bit, little-endian, data-type-policy=OVERRIDE, i-signal-type=PRIMITIVE, init-value=0, base-type=BT_CMM_FlgGlbFallBkIdc, compu-method=CM_CMM_FlgGlbFallBkIdc, data-constr=DC_CMM_FlgGlbFallBkIdc, transfer-property=PENDING  # Signal to request a global fallback of the Charisma mode to default value.
          signal PTOVeh_FlgTqWhlPos_XIX_HCP1_17_XIX_HCP5_CANFD01: start 23, 1 bit, little-endian, data-type-policy=OVERRIDE, i-signal-type=PRIMITIVE, init-value=0, base-type=BT_PTOVeh_FlgTqWhlPos, compu-method=CM_PTOVeh_FlgTqWhlPos, data-constr=DC_PTOVeh_FlgTqWhlPos, transfer-property=PENDING  # flag indicating overall static wheel torque is positive
          signal PTCfgSrv_PwrPtSysMax_XIX_HCP1_17_XIX_HCP5_CANFD01: start 24, 10 bit, little-endian, data-type-policy=OVERRIDE, i-signal-type=PRIMITIVE, init-value=0, base-type=BT_PTCfgSrv_PwrPtSysMax, compu-method=CM_PTCfgSrv_PwrPtSysMax, data-constr=DC_PTCfgSrv_PwrPtSysMax, unit=Unit_Unit_KiloWatt, transfer-property=PENDING  # Gesamtleistung des Antriebsstrangs in kW
          signal PCM_BMC_VTD_Freeze_Req_XIX_HCP1_17_XIX_HCP5_CANFD01: start 34, 2 bit, little-endian, data-type-policy=OVERRIDE, i-signal-type=PRIMITIVE, init-value=2, base-type=BT_PCM_BMC_VTD_Freeze_Req, invalid-value=Invalid_PCM_BMC_VTD_Freeze_Req_XIX_HCP1_17_XIX_HCP5_CANFD01:3, compu-method=CM_PCM_BMC_VTD_Freeze_Req, data-constr=DC_PCM_BMC_VTD_Freeze_Req, transfer-property=PENDING, to BMC_HV(timeout 5 s)  # Synchronissation of Freeze-Condition for VTD-ITs between HCP1 and BMC
          signal PCM_BMC_VTD_LifeTimeReset_Req_XIX_HCP1_17_XIX_HCP5_CANFD01: start 36, 2 bit, little-endian, data-type-policy=OVERRIDE, i-signal-type=PRIMITIVE, init-value=2, base-type=BT_PCM_BMC_VTD_LifeTimeReset_Req, invalid-value=Invalid_PCM_BMC_VTD_LifeTimeReset_Req_XIX_HCP1_17_XIX_HCP5_CANFD01:3, compu-method=CM_PCM_BMC_VTD_LifeTimeReset_Req, data-constr=DC_PCM_BMC_VTD_LifeTimeReset_Req, transfer-property=PENDING, to BMC_HV(timeout 5 s)  # Synchronissation of Freeze-Condition for VTD-ITs between HCP1 and BMC
          signal PCM_BMC_VTD_LifeTimeReset_Resp_XIX_HCP1_17_XIX_HCP5_CANFD01: start 38, 2 bit, little-endian, data-type-policy=OVERRIDE, i-signal-type=PRIMITIVE, init-value=2, base-type=BT_PCM_BMC_VTD_LifeTimeReset_Resp, invalid-value=Invalid_PCM_BMC_VTD_LifeTimeReset_Resp_XIX_HCP1_17_XIX_HCP5_CANFD01:3, compu-method=CM_PCM_BMC_VTD_LifeTimeReset_Resp, data-constr=DC_PCM_BMC_VTD_LifeTimeReset_Resp, transfer-property=PENDING, to BMC_HV(timeout 5 s)  # Synchronissation of Freeze-Condition for VTD-ITs between HCP1 and BMC
          signal PCM_BMC_VTD_RecentReset_Req_XIX_HCP1_17_XIX_HCP5_CANFD01: start 40, 2 bit, little-endian, data-type-policy=OVERRIDE, i-signal-type=PRIMITIVE, init-value=2, base-type=BT_PCM_BMC_VTD_RecentReset_Req, invalid-value=Invalid_PCM_BMC_VTD_RecentReset_Req_XIX_HCP1_17_XIX_HCP5_CANFD01:3, compu-method=CM_PCM_BMC_VTD_RecentReset_Req, data-constr=DC_PCM_BMC_VTD_RecentReset_Req, transfer-property=PENDING, to BMC_HV(timeout 5 s)  # Synchronissation of Freeze-Condition for VTD-ITs between HCP1 and BMC
      frame HVEM_07_XIX_HCP5_CANFD01: id 0xAF954C7, to BMC_HV, frame-length=32, can-addressing-mode=EXTENDED, can-frame-rx-behavior=CAN-FD, can-frame-tx-behavior=CAN-FD
        pdu HVEM_07_XIX_HCP5_CANFD01: length=32, minimum-delay=0.01, transmission-mode-true-timing={cyclic-timing={time-offset=0, time-period=0.08}, event-controlled-timing={number-of-repetitions=0, repetition-period=0}}, unused-bit-pattern=0
          signal HVEM_Nachladen_Anf_XIX_HVEM_07_XIX_HCP5_CANFD01: start 12, 1 bit, little-endian, data-type-policy=OVERRIDE, i-signal-type=PRIMITIVE, init-value=0, base-type=BT_HVEM_Nachladen_Anf, compu-method=CM_HVEM_Nachladen_Anf, data-constr=DC_HVEM_Nachladen_Anf, transfer-property=TRIGGERED-ON-CHANGE-WITHOUT-REPETITION  # Anforderung für HV Laden bei gestecktem Stecker und deaktivierter Ladeanforderung
          signal HVEM_IstLeistung_HVVerbraucher_XIX_HVEM_07_XIX_HCP5_CANFD01: start 13, 12 bit, little-endian, data-type-policy=OVERRIDE, i-signal-type=PRIMITIVE, init-value=4094, base-type=BT_HVEM_IstLeistung_HVVerbraucher, invalid-value=Invalid_HVEM_IstLeistung_HVVerbraucher_XIX_HVEM_07_XIX_HCP5_CANFD01:4095, compu-method=CM_HVEM_IstLeistung_HVVerbraucher, data-constr=DC_HVEM_IstLeistung_HVVerbraucher, unit=Unit_Unit_Watt, transfer-property=PENDING  # Ist Verbrauch der Nebenverbraucher (hochvoltseitig)
          signal HVEM_Nachlad_Status_XIX_HVEM_07_XIX_HCP5_CANFD01: start 25, 2 bit, little-endian, data-type-policy=OVERRIDE, i-signal-type=PRIMITIVE, init-value=3, base-type=BT_HVEM_Nachlad_Status, compu-method=CM_HVEM_Nachlad_Status, data-constr=DC_HVEM_Nachlad_Status, transfer-property=TRIGGERED-ON-CHANGE-WITHOUT-REPETITION  # Status der Umsetzung der Nachladeanforderung der NV-Seite.
          signal HVEM_TME_Energie_Vorgabe_XIX_HVEM_07_XIX_HCP5_CANFD01: start 27, 11 bit, little-endian, data-type-policy=OVERRIDE, i-signal-type=PRIMITIVE, init-value=2046, base-type=BT_HVEM_TME_Energie_Vorgabe, invalid-value=Invalid_HVEM_TME_Energie_Vorgabe_XIX_HVEM_07_XIX_HCP5_CANFD01:2047, compu-method=CM_HVEM_TME_Energie_Vorgabe, data-constr=DC_HVEM_TME_Energie_Vorgabe, unit=Unit_Unit_WattHour, transfer-property=PENDING  # Erweiterte Auflösung von 10Wh für Signal HVEM_Energie_Klima_Vorgabe.
          signal HVEM_TME_Leistung_Vorgabe_XIX_HVEM_07_XIX_HCP5_CANFD01: start 38, 10 bit, little-endian, data-type-policy=OVERRIDE, i-signal-type=PRIMITIVE, init-value=1022, base-type=BT_HVEM_TME_Leistung_Vorgabe, invalid-value=Invalid_HVEM_TME_Leistung_Vorgabe_XIX_HVEM_07_XIX_HCP5_CANFD01:1023, compu-method=CM_HVEM_TME_Leistung_Vorgabe, data-constr=DC_HVEM_TME_Leistung_Vorgabe, unit=Unit_Unit_Watt, transfer-property=PENDING  # Die Leistung, welche das HVEM der TME zur Verfügung stellt.
          signal HVEM_IstStrom_HVVerbraucher_XIX_HVEM_07_XIX_HCP5_CANFD01: start 48, 12 bit, little-endian, data-type-policy=OVERRIDE, i-signal-type=PRIMITIVE, init-value=4094, base-type=BT_HVEM_IstStrom_HVVerbraucher, invalid-value=Invalid_HVEM_IstStrom_HVVerbraucher_XIX_HVEM_07_XIX_HCP5_CANFD01:4095, compu-method=CM_HVEM_IstStrom_HVVerbraucher, data-constr=DC_HVEM_IstStrom_HVVerbraucher, unit=Unit_Unit_Amper, transfer-property=PENDING  # Iststromaufnahme der elektrischen Nebenaggregate aus dem HV Zwischenkreis
          signal HVEM_AIAD_Energieinhalt_XIX_HVEM_07_XIX_HCP5_CANFD01: start 60, 11 bit, little-endian, data-type-policy=OVERRIDE, i-signal-type=PRIMITIVE, init-value=2046, base-type=BT_HVEM_AIAD_Energieinhalt, invalid-value=Invalid_HVEM_AIAD_Energieinhalt_XIX_HVEM_07_XIX_HCP5_CANFD01:2047, compu-method=CM_HVEM_AIAD_Energieinhalt, data-constr=DC_HVEM_AIAD_Energieinhalt, unit=Unit_Unit_WattHour, transfer-property=PENDING  # Erweiterte Auflösung
          signal HVEM_AIAD_Leistungsvorgabe_XIX_HVEM_07_XIX_HCP5_CANFD01: start 71, 9 bit, little-endian, data-type-policy=OVERRIDE, i-signal-type=PRIMITIVE, init-value=510, base-type=BT_HVEM_AIAD_Leistungsvorgabe, invalid-value=Invalid_HVEM_AIAD_Leistungsvorgabe_XIX_HVEM_07_XIX_HCP5_CANFD01:511, compu-method=CM_HVEM_AIAD_Leistungsvorgabe, data-constr=DC_HVEM_AIAD_Leistungsvorgabe, unit=Unit_Unit_Watt, transfer-property=PENDING  # Leistungsvorgabe vom HVEM an das ADC
          signal HVEM_STK_Leistung_verfuegbar_XIX_HVEM_07_XIX_HCP5_CANFD01: start 80, 8 bit, little-endian, data-type-policy=OVERRIDE, i-signal-type=PRIMITIVE, init-value=254, base-type=BT_HVEM_STK_Leistung_verfuegbar, invalid-value=Invalid_HVEM_STK_Leistung_verfuegbar_XIX_HVEM_07_XIX_HCP5_CANFD01:255, compu-method=CM_HVEM_STK_Leistung_verfuegbar, data-constr=DC_HVEM_STK_Leistung_verfuegbar, unit=Unit_Unit_Watt, transfer-property=PENDING  # Verfügbare Leistung seitens Ladeinfrastruktur für die Standklimatisierung
          signal HVEM_Abschaltstufe_XIX_HVEM_07_XIX_HCP5_CANFD01: start 88, 3 bit, little-endian, data-type-policy=OVERRIDE, i-signal-type=PRIMITIVE, init-value=6, base-type=BT_HVEM_Abschaltstufe, invalid-value=Invalid_HVEM_Abschaltstufe_XIX_HVEM_07_XIX_HCP5_CANFD01:7, compu-method=CM_HVEM_Abschaltstufe, data-constr=DC_HVEM_Abschaltstufe, transfer-property=TRIGGERED-ON-CHANGE-WITHOUT-REPETITION  # Abschaltstufen an die Hochvoltteilnehmer
          signal HVEM_TME_Sollstatus_XIX_HVEM_07_XIX_HCP5_CANFD01: start 91, 2 bit, little-endian, data-type-policy=OVERRIDE, i-signal-type=PRIMITIVE, init-value=0, base-type=BT_HVEM_TME_Sollstatus, compu-method=CM_HVEM_TME_Sollstatus, data-constr=DC_HVEM_TME_Sollstatus, transfer-property=TRIGGERED-ON-CHANGE-WITHOUT-REPETITION  # Leistungskommandierung der TME aufgrund externer Einfluesse. Es kann eine Leistungserhöhung (Mindestschub), eine Leistungsreduzierung (Kick Down) oder ein verzoegerter Lastabwurf angefragt werden.
          signal HVEM_StCpbDrv_XIX_HVEM_07_XIX_HCP5_CANFD01: start 93, 3 bit, little-endian, data-type-policy=OVERRIDE, i-signal-type=PRIMITIVE, init-value=0, base-type=BT_HVEM_StCpbDrv, compu-method=CM_HVEM_StCpbDrv, data-constr=DC_HVEM_StCpbDrv, transfer-property=PENDING  # Leistungsfähigkeit der HVB für Antrieb
          signal HVEM_ETM_Max_Ladeleistung_XIX_HVEM_07_XIX_HCP5_CANFD01: start 96, 13 bit, little-endian, data-type-policy=OVERRIDE, i-signal-type=PRIMITIVE, init-value=8190, base-type=BT_HVEM_ETM_Max_Ladeleistung, invalid-value=Invalid_HVEM_ETM_Max_Ladeleistung_XIX_HVEM_07_XIX_HCP5_CANFD01:8191, compu-method=CM_HVEM_ETM_Max_Ladeleistung, data-constr=DC_HVEM_ETM_Max_Ladeleistung, unit=Unit_Unit_Watt, transfer-property=TRIGGERED-ON-CHANGE-WITHOUT-REPETITION  # Elektrische Leistung, die dem ETM vom HVEM zur Abgabe von den elektrischen Antriebsmaschinen freigegeben wird (generatorischer Betrieb)
          signal HVEM_Leistungsvorhalt_Entladen_XIX_HVEM_07_XIX_HCP5_CANFD01: start 109, 11 bit, little-endian, data-type-policy=OVERRIDE, i-signal-type=PRIMITIVE, init-value=2046, base-type=BT_HVEM_Leistungsvorhalt_Entladen, invalid-value=Invalid_HVEM_Leistungsvorhalt_Entladen_XIX_HVEM_07_XIX_HCP5_CANFD01:2047, compu-method=CM_HVEM_Leistungsvorhalt_Entladen, data-constr=DC_HVEM_Leistungsvorhalt_Entladen, unit=Unit_Unit_Watt, transfer-property=PENDING  # Elektrische Leistung, die vom ETM auf der Entladegrenze der Traktionsbatterie zu berücksichtigen ist und sich somit auf die Leistungsaufnahme durch die elektrischen Antriebsmaschinen auswirkt
          signal HVEM_Leistungsvorhalt_Laden_XIX_HVEM_07_XIX_HCP5_CANFD01: start 120, 11 bit, little-endian, data-type-policy=OVERRIDE, i-signal-type=PRIMITIVE, init-value=2046, base-type=BT_HVEM_Leistungsvorhalt_Laden, invalid-value=Invalid_HVEM_Leistungsvorhalt_Laden_XIX_HVEM_07_XIX_HCP5_CANFD01:2047, compu-method=CM_HVEM_Leistungsvorhalt_Laden, data-constr=DC_HVEM_Leistungsvorhalt_Laden, unit=Unit_Unit_Watt, transfer-property=PENDING  # Elektrische Leistung, die vom ETM auf der Ladegrenze der Traktionsbatterie zu berücksichtigen ist und sich somit auf die Leistungsabgabe von den elektrischen Antriebsmaschinen auswirkt
          signal HVEM_ETM_Max_Entladeleistung_XIX_HVEM_07_XIX_HCP5_CANFD01: start 131, 13 bit, little-endian, data-type-policy=OVERRIDE, i-signal-type=PRIMITIVE, init-value=8190, base-type=BT_HVEM_ETM_Max_Entladeleistung, invalid-value=Invalid_HVEM_ETM_Max_Entladeleistung_XIX_HVEM_07_XIX_HCP5_CANFD01:8191, compu-method=CM_HVEM_ETM_Max_Entladeleistung, data-constr=DC_HVEM_ETM_Max_Entladeleistung, unit=Unit_Unit_Watt, transfer-property=TRIGGERED-ON-CHANGE-WITHOUT-REPETITION  # Elektrische Leistung, die dem ETM zur Aufnahme durch die elektrischen Antriebsmaschinen freigegeben wird (i.d.R. motorischer Betrieb)
          signal HVEM_AIAD_RekuVerbot_XIX_HVEM_07_XIX_HCP5_CANFD01: start 144, 2 bit, little-endian, data-type-policy=OVERRIDE, i-signal-type=PRIMITIVE, init-value=0, base-type=BT_HVEM_AIAD_RekuVerbot, compu-method=CM_HVEM_AIAD_RekuVerbot, data-constr=DC_HVEM_AIAD_RekuVerbot, transfer-property=PENDING  # Rückspeiseeinschränkung für ADR
          signal HVEM_TME_MSF_aktiv_XIX_HVEM_07_XIX_HCP5_CANFD01: start 146, 1 bit, little-endian, data-type-policy=OVERRIDE, i-signal-type=PRIMITIVE, init-value=0, base-type=BT_HVEM_TME_MSF_aktiv, compu-method=CM_HVEM_TME_MSF_aktiv, data-constr=DC_HVEM_TME_MSF_aktiv, transfer-property=PENDING  # Aufforderung an TME Leistung zu erhöhen aufgrund aktiver Mindestschubfunktion.
          signal HVEM_BMC_CHA_Wunschleistung_XIX_HVEM_07_XIX_HCP5_CANFD01: start 147, 13 bit, little-endian, data-type-policy=OVERRIDE, i-signal-type=PRIMITIVE, init-value=8190, base-type=BT_HVEM_BMC_CHA_Wunschleistung, invalid-value=Invalid_HVEM_BMC_CHA_Wunschleistung_XIX_HVEM_07_XIX_HCP5_CANFD01:8191, compu-method=CM_HVEM_BMC_CHA_Wunschleistung, data-constr=DC_HVEM_BMC_CHA_Wunschleistung, unit=Unit_Unit_Watt, transfer-property=PENDING, to BMC_HV(timeout 0.8 s)  # Charisma abhängiger Systemleistungsbedarf. Je nach Charismaeinstellung soll die Batterie so temperiert werden, dass die Systemleistung erreicht werden kann.
          signal HVEM_SystemMinLeistungsgrenze_XIX_HVEM_07_XIX_HCP5_CANFD01: start 160, 7 bit, little-endian, data-type-policy=OVERRIDE, i-signal-type=PRIMITIVE, init-value=126, base-type=BT_HVEM_SystemMinLeistungsgrenze, invalid-value=Invalid_HVEM_SystemMinLeistungsgrenze_XIX_HVEM_07_XIX_HCP5_CANFD01:127, compu-method=CM_HVEM_SystemMinLeistungsgrenze, data-constr=DC_HVEM_SystemMinLeistungsgrenze, unit=Unit_Unit_Watt, transfer-property=PENDING, to BMC_HV(timeout 0.8 s)  # Benötigte Mindestleistung für den elektrischen Fahrzeugbetrieb. Diese Leistung besteht aus LimpHome-Grenze, TME_Minleistung, NVEM-FuSi-Grenze und ADR-Vorhalt.
          signal HVEM_StLimElAcy_XIX_HVEM_07_XIX_HCP5_CANFD01: start 167, 1 bit, little-endian, data-type-policy=OVERRIDE, i-signal-type=PRIMITIVE, init-value=0, base-type=BT_HVEM_StLimElAcy, compu-method=CM_HVEM_StLimElAcy, data-constr=DC_HVEM_StLimElAcy, transfer-property=PENDING  # Das HVEM kündigt an, dass das Kontingent für ETM vergrößert wird. (Acknowledge)
          signal HVEM_StCpbElAcy_XIX_HVEM_07_XIX_HCP5_CANFD01: start 168, 1 bit, little-endian, data-type-policy=OVERRIDE, i-signal-type=PRIMITIVE, init-value=0, base-type=BT_HVEM_StCpbElAcy, compu-method=CM_HVEM_StCpbElAcy, data-constr=DC_HVEM_StCpbElAcy, transfer-property=PENDING  # HVEM signalisiert, ob eine Abschaltung der Verbraucher möglich ist
          signal HVEM_ETM_Max_Leistung_Verteiler_XIX_HVEM_07_XIX_HCP5_CANFD01: start 169, 10 bit, little-endian, data-type-policy=OVERRIDE, i-signal-type=PRIMITIVE, init-value=1022, base-type=BT_HVEM_ETM_Max_Leistung_Verteiler, invalid-value=Invalid_HVEM_ETM_Max_Leistung_Verteiler_XIX_HVEM_07_XIX_HCP5_CANFD01:1023, compu-method=CM_HVEM_ETM_Max_Leistung_Verteiler, data-constr=DC_HVEM_ETM_Max_Leistung_Verteiler, unit=Unit_Unit_Watt, transfer-property=PENDING  # Maximal zulässige Leistung für die Verbraucher eKat und eTV
          signal HVEM_MMTR_State_XIX_HVEM_07_XIX_HCP5_CANFD01: start 179, 4 bit, little-endian, data-type-policy=OVERRIDE, i-signal-type=PRIMITIVE, init-value=0, base-type=BT_HVEM_MMTR_State, invalid-value=Invalid_HVEM_MMTR_State_XIX_HVEM_07_XIX_HCP5_CANFD01:15, compu-method=CM_HVEM_MMTR_State, data-constr=DC_HVEM_MMTR_State, transfer-property=PENDING, to BMC_HV(timeout 0.8 s)  # Signal zur Signalisierung des Status der MMTR Funktion durch das Mastermodul HVEM
          signal HVEM_ETM_Max_Ladeleistung_02_XIX_HVEM_07_XIX_HCP5_CANFD01: start 183, 15 bit, little-endian, data-type-policy=OVERRIDE, i-signal-type=PRIMITIVE, init-value=32766, base-type=BT_HVEM_ETM_Max_Ladeleistung_02, invalid-value=Invalid_HVEM_ETM_Max_Ladeleistung_02_XIX_HVEM_07_XIX_HCP5_CANFD01:32767, compu-method=CM_HVEM_ETM_Max_Ladeleistung_02, data-constr=DC_HVEM_ETM_Max_Ladeleistung_02, unit=Unit_Unit_Watt, transfer-property=TRIGGERED-ON-CHANGE-WITHOUT-REPETITION  # Elektrische Leistung, die dem ETM vom HVEM zur Abgabe von den elektrischen Antriebsmaschinen freigegeben wird (generatorischer Betrieb)
          signal HVEM_ETM_Max_Entladeleistung_02_XIX_HVEM_07_XIX_HCP5_CANFD01: start 198, 15 bit, little-endian, data-type-policy=OVERRIDE, i-signal-type=PRIMITIVE, init-value=32766, base-type=BT_HVEM_ETM_Max_Entladeleistung_02, invalid-value=Invalid_HVEM_ETM_Max_Entladeleistung_02_XIX_HVEM_07_XIX_HCP5_CANFD01:32767, compu-method=CM_HVEM_ETM_Max_Entladeleistung_02, data-constr=DC_HVEM_ETM_Max_Entladeleistung_02, unit=Unit_Unit_Watt, transfer-property=TRIGGERED-ON-CHANGE-WITHOUT-REPETITION  # Elektrische Leistung, die dem ETM zur Aufnahme durch die elektrischen Antriebsmaschinen freigegeben wird (i.d.R. motorischer Betrieb)
          signal HVEM_BMC_CHA_Wunschleistung_02_XIX_HVEM_07_XIX_HCP5_CANFD01: start 213, 15 bit, little-endian, data-type-policy=OVERRIDE, i-signal-type=PRIMITIVE, init-value=32766, base-type=BT_HVEM_BMC_CHA_Wunschleistung_02, invalid-value=Invalid_HVEM_BMC_CHA_Wunschleistung_02_XIX_HVEM_07_XIX_HCP5_CANFD01:32767, compu-method=CM_HVEM_BMC_CHA_Wunschleistung_02, data-constr=DC_HVEM_BMC_CHA_Wunschleistung_02, unit=Unit_Unit_Watt, transfer-property=PENDING, to BMC_HV(timeout 0.8 s)  # Charisma abhängiger Systemleistungsbedarf. Je nach Charismaeinstellung soll die Batterie so temperiert werden, dass die Systemleistung erreicht werden kann.
      frame HVK_03_SOK_XIX_HCP5_CANFD01: id 0xAF954C9, to BMC_HV, frame-length=12, can-addressing-mode=EXTENDED, can-frame-rx-behavior=CAN-FD, can-frame-tx-behavior=CAN-FD
        secured i pdu HVK_03_E2E_SOK_XIX_HCP5_CANFD01:
          length=12
          authentication-props=SecureCommunicationAuthenticationProps_XIX_32
          freshness-props=SecureCommunicationFreshnessProps
          payload=PT_HVK_03_E2E
          secure-communication-props={auth-data-freshness-length=0, auth-data-freshness-start-position=0, auth-info-tx-length=32, authentication-build-attempts=1, authentication-retries=4, data-id=715, freshness-value-id=1, freshness-value-length=64, freshness-value-tx-length=0}
          use-as-cryptographic-i-pdu=false
      frame HVLM_13_XIX_HCP5_CANFD01: id 0x271, to BMC_HV, frame-length=32, can-addressing-mode=STANDARD, can-frame-rx-behavior=CAN-FD, can-frame-tx-behavior=CAN-FD
        pdu HVLM_13_XIX_HCP5_CANFD01: length=32, minimum-delay=0.01, transmission-mode-true-timing={cyclic-timing={time-offset=0, time-period=0.1}, event-controlled-timing={number-of-repetitions=5, repetition-period=0}}, unused-bit-pattern=0
          signal HVLM_13_CRC_XIX_HVLM_13_XIX_HCP5_CANFD01: start 0, 8 bit, little-endian, data-type-policy=OVERRIDE, i-signal-type=PRIMITIVE, init-value=0, base-type=BT_HVLM_13_CRC, compu-method=CM_HVLM_13_CRC, data-constr=DC_HVLM_13_CRC, transfer-property=PENDING  # Für MLB: Berechnung siehe Lastenheft "Kommunikationsabsicherung für FlexRay und CAN" Ab MQB und MLBevo: Berechnung siehe Lastenheft "End-to-End Kommunikationsabsicherung" Endwerte siehe Begleitdokument "S-PDU Kennungsfolgen"
          signal HVLM_13_BZ_XIX_HVLM_13_XIX_HCP5_CANFD01: start 8, 4 bit, little-endian, data-type-policy=OVERRIDE, i-signal-type=PRIMITIVE, init-value=0, base-type=BT_HVLM_13_BZ, compu-method=CM_HVLM_13_BZ, data-constr=DC_HVLM_13_BZ, transfer-property=PENDING  # 4bit Botschaftszähler, wird mit jeder Sendebotschaft inkrementiert
          signal HVLM_Stecker_VerEntriegelnAnf_A_XIX_HVLM_13_XIX_HCP5_CANFD01: start 12, 2 bit, little-endian, data-type-policy=OVERRIDE, i-signal-type=PRIMITIVE, init-value=0, base-type=BT_HVLM_Stecker_VerEntriegelnAnf_A, compu-method=CM_HVLM_Stecker_VerEntriegelnAnf_A, data-constr=DC_HVLM_Stecker_VerEntriegelnAnf_A, transfer-property=TRIGGERED-ON-CHANGE-WITHOUT-REPETITION  # Anforderung Ladestecker zu verriegeln für Ladedose A
          signal HVLM_Stecker_VerEntriegelnAnf_B_XIX_HVLM_13_XIX_HCP5_CANFD01: start 14, 2 bit, little-endian, data-type-policy=OVERRIDE, i-signal-type=PRIMITIVE, init-value=0, base-type=BT_HVLM_Stecker_VerEntriegelnAnf_B, compu-method=CM_HVLM_Stecker_VerEntriegelnAnf_B, data-constr=DC_HVLM_Stecker_VerEntriegelnAnf_B, transfer-property=TRIGGERED-ON-CHANGE-WITHOUT-REPETITION  # Anforderung Ladestecker zu verriegeln für Ladedose B
          signal HVLM_DC_SollStrom_XIX_HVLM_13_XIX_HCP5_CANFD01: start 16, 11 bit, little-endian, data-type-policy=OVERRIDE, i-signal-type=PRIMITIVE, init-value=2046, base-type=BT_HVLM_DC_SollStrom, invalid-value=Invalid_HVLM_DC_SollStrom_XIX_HVLM_13_XIX_HCP5_CANFD01:2047, compu-method=CM_HVLM_DC_SollStrom, data-constr=DC_HVLM_DC_SollStrom, unit=Unit_Unit_Amper, transfer-property=PENDING  # Sollstromanforderung für DC-Laden 0.. 160A
          signal HVLM_OBG_SollModus_XIX_HVLM_13_XIX_HCP5_CANFD01: start 27, 3 bit, little-endian, data-type-policy=OVERRIDE, i-signal-type=PRIMITIVE, init-value=0, base-type=BT_HVLM_OBG_SollModus, compu-method=CM_HVLM_OBG_SollModus, data-constr=DC_HVLM_OBG_SollModus, transfer-property=PENDING  # Anforderung des Sollmodus an das Ladegerät.
          signal HVLM_SF4OeffnenAnf_A_XIX_HVLM_13_XIX_HCP5_CANFD01: start 30, 1 bit, little-endian, data-type-policy=OVERRIDE, i-signal-type=PRIMITIVE, init-value=0, base-type=BT_HVLM_SF4OeffnenAnf_A, compu-method=CM_HVLM_SF4OeffnenAnf_A, data-constr=DC_HVLM_SF4OeffnenAnf_A, transfer-property=TRIGGERED-ON-CHANGE-WITHOUT-REPETITION  # Anforderung zum Öffnen/Schliessen des Schalters SF4 am ControlPilot Pin am Verbauort A 0= schliessen 1= oeffnen
          signal HVLM_SF4OeffnenAnf_B_XIX_HVLM_13_XIX_HCP5_CANFD01: start 31, 1 bit, little-endian, data-type-policy=OVERRIDE, i-signal-type=PRIMITIVE, init-value=0, base-type=BT_HVLM_SF4OeffnenAnf_B, compu-method=CM_HVLM_SF4OeffnenAnf_B, data-constr=DC_HVLM_SF4OeffnenAnf_B, transfer-property=TRIGGERED-ON-CHANGE-WITHOUT-REPETITION  # Anforderung zum Öffnen/Schliessen des Schalters SF4 am ControlPilot Pin am Verbauort B 0= schliessen 1= oeffnen
          signal HVLM_S2SchliessenAnf_A_XIX_HVLM_13_XIX_HCP5_CANFD01: start 32, 1 bit, little-endian, data-type-policy=OVERRIDE, i-signal-type=PRIMITIVE, init-value=0, base-type=BT_HVLM_S2SchliessenAnf_A, compu-method=CM_HVLM_S2SchliessenAnf_A, data-constr=DC_HVLM_S2SchliessenAnf_A, transfer-property=TRIGGERED-ON-CHANGE  # Anforderung zum Öffnen/Schliessen des Schalters S2 am ControlPilot Pin am Verbauort A 0= oeffnen 1= schliessen
          signal HVLM_S2SchliessenAnf_B_XIX_HVLM_13_XIX_HCP5_CANFD01: start 33, 1 bit, little-endian, data-type-policy=OVERRIDE, i-signal-type=PRIMITIVE, init-value=0, base-type=BT_HVLM_S2SchliessenAnf_B, compu-method=CM_HVLM_S2SchliessenAnf_B, data-constr=DC_HVLM_S2SchliessenAnf_B, transfer-property=TRIGGERED-ON-CHANGE  # Anforderung zum Öffnen/Schliessen des Schalters S2 am ControlPilot Pin am Verbauort B 0= oeffnen 1= schliessen
          signal HVLM_CP_Fehlerzustand_A_XIX_HVLM_13_XIX_HCP5_CANFD01: start 34, 3 bit, little-endian, data-type-policy=OVERRIDE, i-signal-type=PRIMITIVE, init-value=0, base-type=BT_HVLM_CP_Fehlerzustand_A, compu-method=CM_HVLM_CP_Fehlerzustand_A, data-constr=DC_HVLM_CP_Fehlerzustand_A, transfer-property=PENDING  # Fehler in der CP-Kommunikation
          signal HVLM_CP_Fehlerzustand_B_XIX_HVLM_13_XIX_HCP5_CANFD01: start 37, 3 bit, little-endian, data-type-policy=OVERRIDE, i-signal-type=PRIMITIVE, init-value=0, base-type=BT_HVLM_CP_Fehlerzustand_B, compu-method=CM_HVLM_CP_Fehlerzustand_B, data-constr=DC_HVLM_CP_Fehlerzustand_B, transfer-property=PENDING  # Fehler in der CP-Kommunikation
          signal HVLM_CP_MaxStrom_A_XIX_HVLM_13_XIX_HCP5_CANFD01: start 40, 10 bit, little-endian, data-type-policy=OVERRIDE, i-signal-type=PRIMITIVE, init-value=1022, base-type=BT_HVLM_CP_MaxStrom_A, compu-method=CM_HVLM_CP_MaxStrom_A, data-constr=DC_HVLM_CP_MaxStrom_A, unit=Unit_Unit_Amper, transfer-property=PENDING  # maximaler AC-Aufnahmestrom, durch die Ladesäule vorgegeben
          signal HVLM_CP_KommProtokoll_A_XIX_HVLM_13_XIX_HCP5_CANFD01: start 50, 2 bit, little-endian, data-type-policy=OVERRIDE, i-signal-type=PRIMITIVE, init-value=0, base-type=BT_HVLM_CP_KommProtokoll_A, compu-method=CM_HVLM_CP_KommProtokoll_A, data-constr=DC_HVLM_CP_KommProtokoll_A, transfer-property=PENDING  # Kommunikationsart vom CP signalisiert
          signal HVLM_CP_State_A_XIX_HVLM_13_XIX_HCP5_CANFD01: start 52, 4 bit, little-endian, data-type-policy=OVERRIDE, i-signal-type=PRIMITIVE, init-value=0, base-type=BT_HVLM_CP_State_A, compu-method=CM_HVLM_CP_State_A, data-constr=DC_HVLM_CP_State_A, transfer-property=PENDING  # Zustand der CP-Kommunikation der Ladedose A
          signal HVLM_CP_MaxStrom_B_XIX_HVLM_13_XIX_HCP5_CANFD01: start 56, 10 bit, little-endian, data-type-policy=OVERRIDE, i-signal-type=PRIMITIVE, init-value=1022, base-type=BT_HVLM_CP_MaxStrom_B, compu-method=CM_HVLM_CP_MaxStrom_B, data-constr=DC_HVLM_CP_MaxStrom_B, unit=Unit_Unit_Amper, transfer-property=PENDING  # maximaler AC-Aufnahmestrom, durch die Ladesäule vorgegeben
          signal HVLM_CP_KommProtokoll_B_XIX_HVLM_13_XIX_HCP5_CANFD01: start 66, 2 bit, little-endian, data-type-policy=OVERRIDE, i-signal-type=PRIMITIVE, init-value=0, base-type=BT_HVLM_CP_KommProtokoll_B, compu-method=CM_HVLM_CP_KommProtokoll_B, data-constr=DC_HVLM_CP_KommProtokoll_B, transfer-property=PENDING  # Kommunikationsart vom CP signalisiert
          signal HVLM_CP_State_B_XIX_HVLM_13_XIX_HCP5_CANFD01: start 68, 4 bit, little-endian, data-type-policy=OVERRIDE, i-signal-type=PRIMITIVE, init-value=0, base-type=BT_HVLM_CP_State_B, compu-method=CM_HVLM_CP_State_B, data-constr=DC_HVLM_CP_State_B, transfer-property=PENDING  # Zustand der CP-Kommunikation der Ladedose B
          signal HVLM_Max_Strom_Netz_L1_XIX_HVLM_13_XIX_HCP5_CANFD01: start 72, 10 bit, little-endian, data-type-policy=OVERRIDE, i-signal-type=PRIMITIVE, init-value=1022, base-type=BT_HVLM_Max_Strom_Netz_L1, invalid-value=Invalid_HVLM_Max_Strom_Netz_L1_XIX_HVLM_13_XIX_HCP5_CANFD01:1023, compu-method=CM_HVLM_Max_Strom_Netz_L1, data-constr=DC_HVLM_Max_Strom_Netz_L1, unit=Unit_Unit_Amper, transfer-property=PENDING  # Gibt den maximal zulässigen Aufnahmestrom aus der Infrastruktur auf L1 an.
          signal HVLM_Max_Strom_Netz_L2_XIX_HVLM_13_XIX_HCP5_CANFD01: start 82, 10 bit, little-endian, data-type-policy=OVERRIDE, i-signal-type=PRIMITIVE, init-value=1022, base-type=BT_HVLM_Max_Strom_Netz_L2, invalid-value=Invalid_HVLM_Max_Strom_Netz_L2_XIX_HVLM_13_XIX_HCP5_CANFD01:1023, compu-method=CM_HVLM_Max_Strom_Netz_L2, data-constr=DC_HVLM_Max_Strom_Netz_L2, unit=Unit_Unit_Amper, transfer-property=PENDING  # Gibt den maximal zulässigen Aufnahmestrom aus der Infrastruktur auf L2 an.
          signal HVLM_Max_Strom_Netz_L3_XIX_HVLM_13_XIX_HCP5_CANFD01: start 92, 10 bit, little-endian, data-type-policy=OVERRIDE, i-signal-type=PRIMITIVE, init-value=1022, base-type=BT_HVLM_Max_Strom_Netz_L3, invalid-value=Invalid_HVLM_Max_Strom_Netz_L3_XIX_HVLM_13_XIX_HCP5_CANFD01:1023, compu-method=CM_HVLM_Max_Strom_Netz_L3, data-constr=DC_HVLM_Max_Strom_Netz_L3, unit=Unit_Unit_Amper, transfer-property=PENDING  # Gibt den maximal zulässigen Aufnahmestrom aus der Infrastruktur auf L3 an.
          signal HVLM_MaxSpannung_OBG_HV_XIX_HVLM_13_XIX_HCP5_CANFD01: start 102, 10 bit, little-endian, data-type-policy=OVERRIDE, i-signal-type=PRIMITIVE, init-value=1022, base-type=BT_HVLM_MaxSpannung_OBG_HV, invalid-value=Invalid_HVLM_MaxSpannung_OBG_HV_XIX_HVLM_13_XIX_HCP5_CANFD01:1023, compu-method=CM_HVLM_MaxSpannung_OBG_HV, data-constr=DC_HVLM_MaxSpannung_OBG_HV, unit=Unit_Unit_Volt, transfer-property=PENDING  # Maximal zulässige Ausgangsspannung des Onboardgleichrichters
          signal HVLM_Stecker_Notentriegeln_Anf_A_XIX_HVLM_13_XIX_HCP5_CANFD01: start 112, 2 bit, little-endian, data-type-policy=OVERRIDE, i-signal-type=PRIMITIVE, init-value=0, base-type=BT_HVLM_Stecker_Notentriegeln_Anf_A, compu-method=CM_HVLM_Stecker_Notentriegeln_Anf_A, data-constr=DC_HVLM_Stecker_Notentriegeln_Anf_A, transfer-property=TRIGGERED-ON-CHANGE-WITHOUT-REPETITION  # Anforderung zur Notentriegelung des Ladesteckers in Ladedose A
          signal HVLM_Stecker_Notentriegeln_Anf_B_XIX_HVLM_13_XIX_HCP5_CANFD01: start 114, 2 bit, little-endian, data-type-policy=OVERRIDE, i-signal-type=PRIMITIVE, init-value=0, base-type=BT_HVLM_Stecker_Notentriegeln_Anf_B, compu-method=CM_HVLM_Stecker_Notentriegeln_Anf_B, data-constr=DC_HVLM_Stecker_Notentriegeln_Anf_B, transfer-property=TRIGGERED-ON-CHANGE-WITHOUT-REPETITION  # Anforderung zur Notentriegelung des Ladesteckers in Ladedose B
          signal HVLM_Ladeklappe_VerEntriegeAnf_1_XIX_HVLM_13_XIX_HCP5_CANFD01: start 116, 2 bit, little-endian, data-type-policy=OVERRIDE, i-signal-type=PRIMITIVE, init-value=0, base-type=BT_HVLM_Ladeklappe_VerEntriegeAnf_1, compu-method=CM_HVLM_Ladeklappe_VerEntriegeAnf_1, data-constr=DC_HVLM_Ladeklappe_VerEntriegeAnf_1, transfer-property=TRIGGERED-ON-CHANGE-WITHOUT-REPETITION  # Anforderung die Ladeklappe der Ladedose 1 zu verriegeln oder zu entriegeln.
          signal HVLM_Ladeklappe_VerEntriegeAnf_2_XIX_HVLM_13_XIX_HCP5_CANFD01: start 118, 2 bit, little-endian, data-type-policy=OVERRIDE, i-signal-type=PRIMITIVE, init-value=0, base-type=BT_HVLM_Ladeklappe_VerEntriegeAnf_2, compu-method=CM_HVLM_Ladeklappe_VerEntriegeAnf_2, data-constr=DC_HVLM_Ladeklappe_VerEntriegeAnf_2, transfer-property=TRIGGERED-ON-CHANGE-WITHOUT-REPETITION  # Anforderung die Ladeklappe der Ladedose 2 zu verriegeln oder zu entriegeln.
          signal LVB_Ladegeschw_XIX_HVLM_13_XIX_HCP5_CANFD01: start 120, 13 bit, little-endian, data-type-policy=OVERRIDE, i-signal-type=PRIMITIVE, init-value=8190, base-type=BT_LVB_Ladegeschw, compu-method=CM_LVB_Ladegeschw, data-constr=DC_LVB_Ladegeschw, unit=Unit_Unit_None, transfer-property=PENDING  # Gibt die Geschwindigkeit des Ladevorgangs an. Einheit siehe Signal LVB_LadegeschwEinheit.
          signal LVB_LadegeschwEinheit_XIX_HVLM_13_XIX_HCP5_CANFD01: start 133, 3 bit, little-endian, data-type-policy=OVERRIDE, i-signal-type=PRIMITIVE, init-value=0, base-type=BT_LVB_LadegeschwEinheit, compu-method=CM_LVB_LadegeschwEinheit, data-constr=DC_LVB_LadegeschwEinheit, transfer-property=PENDING  # Einheit der Ladegeschwindigkeit
          signal LVB_StatusLadegeschw_XIX_HVLM_13_XIX_HCP5_CANFD01: start 136, 2 bit, little-endian, data-type-policy=OVERRIDE, i-signal-type=PRIMITIVE, init-value=2, base-type=BT_LVB_StatusLadegeschw, compu-method=CM_LVB_StatusLadegeschw, data-constr=DC_LVB_StatusLadegeschw, transfer-property=PENDING  # Gibt Informationen über die Gültigkeit der Ladegeschwindigkeit.
          signal LVB_StatusRestladezeit_XIX_HVLM_13_XIX_HCP5_CANFD01: start 138, 2 bit, little-endian, data-type-policy=OVERRIDE, i-signal-type=PRIMITIVE, init-value=2, base-type=BT_LVB_StatusRestladezeit, compu-method=CM_LVB_StatusRestladezeit, data-constr=DC_LVB_StatusRestladezeit, transfer-property=PENDING  # Gibt Informationen über die Gültigkeit der Restladezeit.
          signal LVB_Restladezeit_XIX_HVLM_13_XIX_HCP5_CANFD01: start 140, 12 bit, little-endian, data-type-policy=OVERRIDE, i-signal-type=PRIMITIVE, init-value=4094, base-type=BT_LVB_Restladezeit, invalid-value=Invalid_LVB_Restladezeit_XIX_HVLM_13_XIX_HCP5_CANFD01:4095, compu-method=CM_LVB_Restladezeit, data-constr=DC_LVB_Restladezeit, unit=Unit_Unit_Minut, transfer-property=PENDING  # Restladezeit des Ladevorgangs bis gewünschter Ladezustand erreicht ist.
          signal HVLM_LadedosenSuchlicht_XIX_HVLM_13_XIX_HCP5_CANFD01: start 152, 3 bit, little-endian, data-type-policy=OVERRIDE, i-signal-type=PRIMITIVE, init-value=0, base-type=BT_HVLM_LadedosenSuchlicht, compu-method=CM_HVLM_LadedosenSuchlicht, data-constr=DC_HVLM_LadedosenSuchlicht, transfer-property=TRIGGERED-ON-CHANGE-WITHOUT-REPETITION  # Signal zur Ansteuerung des Suchlichtes in der Ladedose
          signal HVLM_VA_Sollmodus_XIX_HVLM_13_XIX_HCP5_CANFD01: start 155, 2 bit, little-endian, data-type-policy=OVERRIDE, i-signal-type=PRIMITIVE, init-value=0, base-type=BT_HVLM_VA_Sollmodus, compu-method=CM_HVLM_VA_Sollmodus, data-constr=DC_HVLM_VA_Sollmodus, transfer-property=TRIGGERED-ON-CHANGE-WITHOUT-REPETITION  # Anforderung des Sollmodus an die VA beim induktiven Laden
          signal LVB_Ladegeschw_VZ_XIX_HVLM_13_XIX_HCP5_CANFD01: start 157, 1 bit, little-endian, data-type-policy=OVERRIDE, i-signal-type=PRIMITIVE, init-value=1, base-type=BT_LVB_Ladegeschw_VZ, compu-method=CM_LVB_Ladegeschw_VZ, data-constr=DC_LVB_Ladegeschw_VZ, transfer-property=PENDING  # Vorzeichen Bit zur Wertebereichseinstellung des Signals LVB_Ladegeschw. Als Hilfsgröße zur Umschaltung in einen positiven oder negativen Wertebereich
          signal HVLM_SpannungsModusDc_Anf_XIX_HVLM_13_XIX_HCP5_CANFD01: start 158, 2 bit, little-endian, data-type-policy=OVERRIDE, i-signal-type=PRIMITIVE, init-value=0, base-type=BT_HVLM_SpannungsModusDc_Anf, compu-method=CM_HVLM_SpannungsModusDc_Anf, data-constr=DC_HVLM_SpannungsModusDc_Anf, transfer-property=PENDING  # Art des angeforderten Spannungsmodus beim DC-Laden an den HVK mit dem das Fahrzeug geladen werden soll
          signal HVLM_GAFrequenz_XIX_HVLM_13_XIX_HCP5_CANFD01: start 160, 14 bit, little-endian, data-type-policy=OVERRIDE, i-signal-type=PRIMITIVE, init-value=16382, base-type=BT_HVLM_GAFrequenz, invalid-value=Invalid_HVLM_GAFrequenz_XIX_HVLM_13_XIX_HCP5_CANFD01:16383, compu-method=CM_HVLM_GAFrequenz, data-constr=DC_HVLM_GAFrequenz, unit=Unit_Unit_Hertz, transfer-property=TRIGGERED-ON-CHANGE-WITHOUT-REPETITION  # Gewünschte Übertragungsfrequenz der GA beim induktiven Laden
          signal HVLM_GASpulenstrom_XIX_HVLM_13_XIX_HCP5_CANFD01: start 174, 10 bit, little-endian, data-type-policy=OVERRIDE, i-signal-type=PRIMITIVE, init-value=1022, base-type=BT_HVLM_GASpulenstrom, invalid-value=Invalid_HVLM_GASpulenstrom_XIX_HVLM_13_XIX_HCP5_CANFD01:1023, compu-method=CM_HVLM_GASpulenstrom, data-constr=DC_HVLM_GASpulenstrom, unit=Unit_Unit_Amper, transfer-property=TRIGGERED-ON-CHANGE-WITHOUT-REPETITION  # Gewünschter Strom in der GA Spule beim induktiven Laden
          signal HVLM_VALeistungFzg_XIX_HVLM_13_XIX_HCP5_CANFD01: start 184, 12 bit, little-endian, data-type-policy=OVERRIDE, i-signal-type=PRIMITIVE, init-value=4094, base-type=BT_HVLM_VALeistungFzg, invalid-value=Invalid_HVLM_VALeistungFzg_XIX_HVLM_13_XIX_HCP5_CANFD01:4095, compu-method=CM_HVLM_VALeistungFzg, data-constr=DC_HVLM_VALeistungFzg, unit=Unit_Unit_Watt, transfer-property=TRIGGERED-ON-CHANGE-WITHOUT-REPETITION  # Gewünschte Leistung am Gleichrichter VA beim induktiven Laden
          signal HVLM_VASpannungFzg_XIX_HVLM_13_XIX_HCP5_CANFD01: start 196, 10 bit, little-endian, data-type-policy=OVERRIDE, i-signal-type=PRIMITIVE, init-value=1022, base-type=BT_HVLM_VASpannungFzg, invalid-value=Invalid_HVLM_VASpannungFzg_XIX_HVLM_13_XIX_HCP5_CANFD01:1023, compu-method=CM_HVLM_VASpannungFzg, data-constr=DC_HVLM_VASpannungFzg, unit=Unit_Unit_Volt, transfer-property=TRIGGERED-ON-CHANGE-WITHOUT-REPETITION  # Sollspannung am DC Ausgang der VA
          signal HVLM_VAStromFzg_XIX_HVLM_13_XIX_HCP5_CANFD01: start 206, 10 bit, little-endian, data-type-policy=OVERRIDE, i-signal-type=PRIMITIVE, init-value=1022, base-type=BT_HVLM_VAStromFzg, invalid-value=Invalid_HVLM_VAStromFzg_XIX_HVLM_13_XIX_HCP5_CANFD01:1023, compu-method=CM_HVLM_VAStromFzg, data-constr=DC_HVLM_VAStromFzg, unit=Unit_Unit_Amper, transfer-property=TRIGGERED-ON-CHANGE-WITHOUT-REPETITION  # Sollstrom am DC Ausgang der VA
          signal HVLM_Intensitaet_Lk3_XIX_HVLM_13_XIX_HCP5_CANFD01: start 216, 7 bit, little-endian, data-type-policy=OVERRIDE, i-signal-type=PRIMITIVE, init-value=126, base-type=BT_HVLM_Intensitaet_Lk3, invalid-value=Invalid_HVLM_Intensitaet_Lk3_XIX_HVLM_13_XIX_HCP5_CANFD01:127, compu-method=CM_HVLM_Intensitaet_Lk3, data-constr=DC_HVLM_Intensitaet_Lk3, unit=Unit_Unit_PerCent, transfer-property=TRIGGERED-ON-CHANGE-WITHOUT-REPETITION  # Über dieses Signal wird eine Information über die Beleuchtungsintensität an der LED der Ladeklappe 2 gesendet. Suffix 3 bezieht sich auf virtuelle Ladeklappe 3, welche die zweite Ladeklappe bei einer Ansteuerung beider Ladeklappen durch ein Steuergerät ist.
          signal HVLM_BidiLadeModus_XIX_HVLM_13_XIX_HCP5_CANFD01: start 224, 2 bit, little-endian, data-type-policy=OVERRIDE, i-signal-type=PRIMITIVE, init-value=0, base-type=BT_HVLM_BidiLadeModus, compu-method=CM_HVLM_BidiLadeModus, data-constr=DC_HVLM_BidiLadeModus, transfer-property=PENDING, to BMC_HV(timeout 1 s)  # Es signalisiert dass das bidirektionale Laden aktiv ist und ob mit kleiner oder mittlerer Leistung geladen wird. Bei aktivem bidirektionalen Laden kann das Fahrzeug sowohl entladen als auch geladen werden.
          signal HVLM_ALF_PosAnforderung_XIX_HVLM_13_XIX_HCP5_CANFD01: start 226, 3 bit, little-endian, data-type-policy=OVERRIDE, i-signal-type=PRIMITIVE, init-value=0, base-type=BT_HVLM_ALF_PosAnforderung, invalid-value=Invalid_HVLM_ALF_PosAnforderung_XIX_HVLM_13_XIX_HCP5_CANFD01:7, compu-method=CM_HVLM_ALF_PosAnforderung, data-constr=DC_HVLM_ALF_PosAnforderung, transfer-property=TRIGGERED-ON-CHANGE-WITHOUT-REPETITION  # Anforderung des induktiven Ladesystems an die Parkfunktionen zur Aktivierung der Positionierung und Rückmeldung über den Status des Positionierungsvorgangs.
          signal HVLM_Ladeklappe_VerEntriegeAnf_3_XIX_HVLM_13_XIX_HCP5_CANFD01: start 229, 2 bit, little-endian, data-type-policy=OVERRIDE, i-signal-type=PRIMITIVE, init-value=0, base-type=BT_HVLM_Ladeklappe_VerEntriegeAnf_3, compu-method=CM_HVLM_Ladeklappe_VerEntriegeAnf_3, data-constr=DC_HVLM_Ladeklappe_VerEntriegeAnf_3, transfer-property=TRIGGERED-ON-CHANGE-WITHOUT-REPETITION  # Anforderung die Ladeklappe der Ladedose 2 zu verriegeln oder zu entriegeln. Suffix 3 bezieht sich auf virtuelle Ladeklappe 3, welche die zweite Ladeklappe bei einer Ansteuerung beider Ladeklappen durch ein Steuergerät ist.
          signal HVLM_ALF_AktiverLadeniveauwunsch_XIX_HVLM_13_XIX_HCP5_CANFD01: start 231, 1 bit, little-endian, data-type-policy=OVERRIDE, i-signal-type=PRIMITIVE, init-value=0, base-type=BT_HVLM_ALF_AktiverLadeniveauwunsch, compu-method=CM_HVLM_ALF_AktiverLadeniveauwunsch, data-constr=DC_HVLM_ALF_AktiverLadeniveauwunsch, transfer-property=PENDING  # Bestätigung des manuellen ALF Ladeniveauwunsches durch Kunden
          signal HVLM_ALF_Ladestatus_Niveau_XIX_HVLM_13_XIX_HCP5_CANFD01: start 232, 3 bit, little-endian, data-type-policy=OVERRIDE, i-signal-type=PRIMITIVE, init-value=6, base-type=BT_HVLM_ALF_Ladestatus_Niveau, invalid-value=Invalid_HVLM_ALF_Ladestatus_Niveau_XIX_HVLM_13_XIX_HCP5_CANFD01:7, compu-method=CM_HVLM_ALF_Ladestatus_Niveau, data-constr=DC_HVLM_ALF_Ladestatus_Niveau, transfer-property=PENDING  # Genauer Status von "Laden Aktiv" an LC zur Unterscheidung von Ladepause, Ladestrom aktiv und Objektevent
          signal HVLM_ALF_PosStatus_XIX_HVLM_13_XIX_HCP5_CANFD01: start 235, 3 bit, little-endian, data-type-policy=OVERRIDE, i-signal-type=PRIMITIVE, init-value=0, base-type=BT_HVLM_ALF_PosStatus, invalid-value=Invalid_HVLM_ALF_PosStatus_XIX_HVLM_13_XIX_HCP5_CANFD01:7, compu-method=CM_HVLM_ALF_PosStatus, data-constr=DC_HVLM_ALF_PosStatus, transfer-property=TRIGGERED-ON-CHANGE-WITHOUT-REPETITION  # Rückmeldung der AWC-VA zum Status der Positionierung.
          signal HVLM_WLAN_Verbinden_XIX_HVLM_13_XIX_HCP5_CANFD01: start 238, 2 bit, little-endian, data-type-policy=OVERRIDE, i-signal-type=PRIMITIVE, init-value=0, base-type=BT_HVLM_WLAN_Verbinden, compu-method=CM_HVLM_WLAN_Verbinden, data-constr=DC_HVLM_WLAN_Verbinden, transfer-property=TRIGGERED-ON-CHANGE  # Anforderung zum Aufbau der WLAN Kommunikation
          signal HVLM_WLAN_Aktivieren_XIX_HVLM_13_XIX_HCP5_CANFD01: start 244, 1 bit, little-endian, data-type-policy=OVERRIDE, i-signal-type=PRIMITIVE, init-value=0, base-type=BT_HVLM_WLAN_Aktivieren, compu-method=CM_HVLM_WLAN_Aktivieren, data-constr=DC_HVLM_WLAN_Aktivieren, transfer-property=TRIGGERED-ON-CHANGE  # Anforderung zur Aktivierung des WLAN Moduls
          signal HVLM_ALF_PosLadeart_XIX_HVLM_13_XIX_HCP5_CANFD01: start 245, 3 bit, little-endian, data-type-policy=OVERRIDE, i-signal-type=PRIMITIVE, init-value=0, base-type=BT_HVLM_ALF_PosLadeart, invalid-value=Invalid_HVLM_ALF_PosLadeart_XIX_HVLM_13_XIX_HCP5_CANFD01:7, compu-method=CM_HVLM_ALF_PosLadeart, data-constr=DC_HVLM_ALF_PosLadeart, transfer-property=TRIGGERED-ON-CHANGE-WITHOUT-REPETITION  # Gibt an, für welche automatisierte Ladefunktion die Positionierung des Fahrzeugs vorgenommen werden soll (Auswahl entsprechend der verfügbaren automatisierten Ladearten)
          signal HVLM_Schluessel_Anfrage_XIX_HVLM_13_XIX_HCP5_CANFD01: start 248, 2 bit, little-endian, data-type-policy=OVERRIDE, i-signal-type=PRIMITIVE, init-value=0, base-type=BT_HVLM_Schluessel_Anfrage, compu-method=CM_HVLM_Schluessel_Anfrage, data-constr=DC_HVLM_Schluessel_Anfrage, transfer-property=PENDING  # Anforderung HVLM an BCM für Schlüsselsuche über Kessy
          signal HVLM_Stecker_Notentriegeln_Anf_C_XIX_HVLM_13_XIX_HCP5_CANFD01: start 250, 2 bit, little-endian, data-type-policy=OVERRIDE, i-signal-type=PRIMITIVE, init-value=0, base-type=BT_HVLM_Stecker_Notentriegeln_Anf_C, compu-method=CM_HVLM_Stecker_Notentriegeln_Anf_C, data-constr=DC_HVLM_Stecker_Notentriegeln_Anf_C, transfer-property=TRIGGERED-ON-CHANGE-WITHOUT-REPETITION  # Anforderung zur Notentriegelung des Ladesteckers in Ladedose C
          signal HVLM_Stecker_VerEntriegelnAnf_C_XIX_HVLM_13_XIX_HCP5_CANFD01: start 252, 2 bit, little-endian, data-type-policy=OVERRIDE, i-signal-type=PRIMITIVE, init-value=0, base-type=BT_HVLM_Stecker_VerEntriegelnAnf_C, compu-method=CM_HVLM_Stecker_VerEntriegelnAnf_C, data-constr=DC_HVLM_Stecker_VerEntriegelnAnf_C, transfer-property=TRIGGERED-ON-CHANGE-WITHOUT-REPETITION  # Anforderung Ladestecker zu verriegeln fuer Ladedose C
      frame HVLM_14_XIX_HCP5_CANFD01: id 0x272, to BMC_HV, frame-length=8, can-addressing-mode=STANDARD, can-frame-rx-behavior=CAN-FD, can-frame-tx-behavior=CAN-FD
        pdu HVLM_14_XIX_HCP5_CANFD01_E2E: length=8, minimum-delay=0.01, transmission-mode-true-timing=event-controlled-timing={number-of-repetitions=0, repetition-period=0}, unused-bit-pattern=0  # Fuer die Botschaft ist das Cyclic-Timing 0.1 zu verwenden.
          signal HVLM_14_CRC_XIX_HVLM_14_XIX_HCP5_CANFD01: start 0, 8 bit, little-endian, data-type-policy=OVERRIDE, i-signal-type=PRIMITIVE, init-value=0, base-type=BT_HVLM_14_CRC, compu-method=CM_HVLM_14_CRC, data-constr=DC_HVLM_14_CRC, to BMC_HV(timeout 1 s)
          signal HVLM_14_BZ_XIX_HVLM_14_XIX_HCP5_CANFD01: start 8, 4 bit, little-endian, data-type-policy=OVERRIDE, i-signal-type=PRIMITIVE, init-value=0, base-type=BT_HVLM_14_BZ, compu-method=CM_HVLM_14_BZ, data-constr=DC_HVLM_14_BZ, to BMC_HV(timeout 1 s)
          signal HVLM_Aktive_Ladeart_XIX_HVLM_14_XIX_HCP5_CANFD01: start 12, 3 bit, little-endian, data-type-policy=OVERRIDE, i-signal-type=PRIMITIVE, init-value=0, base-type=BT_HVLM_Aktive_Ladeart, invalid-value=Invalid_HVLM_Aktive_Ladeart_XIX_HVLM_14_XIX_HCP5_CANFD01:7, compu-method=CM_HVLM_Aktive_Ladeart, data-constr=DC_HVLM_Aktive_Ladeart  # informs about the used charging infrastructure - AC - DC - AWC.
          signal HVLM_Grundladen_Anf_XIX_HVLM_14_XIX_HCP5_CANFD01: start 15, 1 bit, little-endian, data-type-policy=OVERRIDE, i-signal-type=PRIMITIVE, init-value=0, base-type=BT_HVLM_Grundladen_Anf, compu-method=CM_HVLM_Grundladen_Anf, data-constr=DC_HVLM_Grundladen_Anf  # Anforderung des Grundladens
          signal ISignalVoid_HVLM_14_XIX_HCP5_CANFD01_0: start 16, 1 bit, little-endian, system signal SignalVoid_HVLM_14_0, data-type-policy=OVERRIDE, i-signal-type=PRIMITIVE, base-type=BT_SignalVoid
          signal HVLM_Pulsierstufe_XIX_HVLM_14_XIX_HCP5_CANFD01: start 17, 3 bit, little-endian, data-type-policy=OVERRIDE, i-signal-type=PRIMITIVE, init-value=0, base-type=BT_HVLM_Pulsierstufe, compu-method=CM_HVLM_Pulsierstufe, data-constr=DC_HVLM_Pulsierstufe  # Über dieses Signal wird eine Information über die Frequenz der Ladedosen LED bei verschiedenen Leuchtmustern gesendet.
          signal HVLM_Intensitaet_Lk2_XIX_HVLM_14_XIX_HCP5_CANFD01: start 20, 7 bit, little-endian, data-type-policy=OVERRIDE, i-signal-type=PRIMITIVE, init-value=126, base-type=BT_HVLM_Intensitaet_Lk2, invalid-value=Invalid_HVLM_Intensitaet_Lk2_XIX_HVLM_14_XIX_HCP5_CANFD01:127, compu-method=CM_HVLM_Intensitaet_Lk2, data-constr=DC_HVLM_Intensitaet_Lk2, unit=Unit_Unit_PerCent  # Über dieses Signal wird eine Information über die Beleuchtungsintensität an der LED der Ladeklappe 2 gesendet.
          signal HVLM_PrkCtl_StAlyReq_XIX_HVLM_14_XIX_HCP5_CANFD01: start 27, 3 bit, little-endian, data-type-policy=OVERRIDE, i-signal-type=PRIMITIVE, init-value=6, base-type=BT_HVLM_PrkCtl_StAlyReq, invalid-value=Invalid_HVLM_PrkCtl_StAlyReq_XIX_HVLM_14_XIX_HCP5_CANFD01:7, compu-method=CM_HVLM_PrkCtl_StAlyReq, data-constr=DC_HVLM_PrkCtl_StAlyReq  # Request to apply the park actuators.
          signal HVLM_PrkCtl_StPrkLockReq_XIX_HVLM_14_XIX_HCP5_CANFD01: start 30, 2 bit, little-endian, data-type-policy=OVERRIDE, i-signal-type=PRIMITIVE, init-value=2, base-type=BT_HVLM_PrkCtl_StPrkLockReq, invalid-value=Invalid_HVLM_PrkCtl_StPrkLockReq_XIX_HVLM_14_XIX_HCP5_CANFD01:3, compu-method=CM_HVLM_PrkCtl_StPrkLockReq, data-constr=DC_HVLM_PrkCtl_StPrkLockReq  # Request to keep the park aktuators locked in applied position if they are applied.
          signal HVLM_WakeUpZaehlerResetAnf_XIX_HVLM_14_XIX_HCP5_CANFD01: start 32, 1 bit, little-endian, data-type-policy=OVERRIDE, i-signal-type=PRIMITIVE, init-value=0, base-type=BT_HVLM_WakeUpZaehlerResetAnf, compu-method=CM_HVLM_WakeUpZaehlerResetAnf, data-constr=DC_HVLM_WakeUpZaehlerResetAnf  # Dieses Signal kann den Wakeup-Verhinderungszähler zurücksetzen
          signal ISignalVoid_HVLM_14_XIX_HCP5_CANFD01_1: start 33, 2 bit, little-endian, system signal SignalVoid_HVLM_14_1, data-type-policy=OVERRIDE, i-signal-type=PRIMITIVE, base-type=BT_SignalVoid
          signal HVLM_Steckerstatus_XIX_HVLM_14_XIX_HCP5_CANFD01: start 35, 2 bit, little-endian, data-type-policy=OVERRIDE, i-signal-type=PRIMITIVE, init-value=0, base-type=BT_HVLM_Steckerstatus, invalid-value=Invalid_HVLM_Steckerstatus_XIX_HVLM_14_XIX_HCP5_CANFD01:3, compu-method=CM_HVLM_Steckerstatus, data-constr=DC_HVLM_Steckerstatus, to BMC_HV(timeout 1 s)  # Stellt den Status eines Ladesteckers im Fahrzeug hinsichtlich Präsenz zur Verfügung
          signal HVLM_Ladeniveau_Anf_XIX_HVLM_14_XIX_HCP5_CANFD01: start 37, 3 bit, little-endian, data-type-policy=OVERRIDE, i-signal-type=PRIMITIVE, init-value=6, base-type=BT_HVLM_Ladeniveau_Anf, invalid-value=Invalid_HVLM_Ladeniveau_Anf_XIX_HVLM_14_XIX_HCP5_CANFD01:7, compu-method=CM_HVLM_Ladeniveau_Anf, data-constr=DC_HVLM_Ladeniveau_Anf  # Anforderung des HVLM an die Niveauregelung eine für das Laden spezifische Fahrzeughöhe einzustellen.
          signal HVLM_Ladenaktiv_Standzyklus_XIX_HVLM_14_XIX_HCP5_CANFD01: start 40, 1 bit, little-endian, data-type-policy=OVERRIDE, i-signal-type=PRIMITIVE, init-value=0, base-type=BT_HVLM_Ladenaktiv_Standzyklus, compu-method=CM_HVLM_Ladenaktiv_Standzyklus, data-constr=DC_HVLM_Ladenaktiv_Standzyklus  # Signalisiert ob im aktuellen Standzyklus (Fahrzeug wurde nicht bewegt) mindestens einmal HV-Ladevorgang stattgefunden hat.
          signal HVLM_Start_Pulserkennung_XIX_HVLM_14_XIX_HCP5_CANFD01: start 41, 1 bit, little-endian, data-type-policy=OVERRIDE, i-signal-type=PRIMITIVE, init-value=0, base-type=BT_HVLM_Start_Pulserkennung, compu-method=CM_HVLM_Start_Pulserkennung, data-constr=DC_HVLM_Start_Pulserkennung, to BMC_HV(timeout 1 s)  # Startanforderung für die Pulserkennung
          signal HVLM_ZustandLadeablauf_XIX_HVLM_14_XIX_HCP5_CANFD01: start 42, 4 bit, little-endian, data-type-policy=OVERRIDE, i-signal-type=PRIMITIVE, init-value=0, base-type=BT_HVLM_ZustandLadeablauf, invalid-value=Invalid_HVLM_ZustandLadeablauf_XIX_HVLM_14_XIX_HCP5_CANFD01:3, compu-method=CM_HVLM_ZustandLadeablauf, data-constr=DC_HVLM_ZustandLadeablauf, to BMC_HV(timeout 1 s)  # Zustand im Ablauf des Ladevorganges 0 = Init 1 = Standby_Ladevorbedingungen erfuellt 2 = Standby_Ladevorbedingungen_nicht_erfuellt 3 = Fehler 4 = Laden_starten 5 = Laden_beenden 6 = HVBatterie_Laden 7 = HVBatterie_Entladen 8 = Erhaltungsladen
          signal HVLM_DC_Aufstartmodus_XIX_HVLM_14_XIX_HCP5_CANFD01: start 46, 2 bit, little-endian, data-type-policy=OVERRIDE, i-signal-type=PRIMITIVE, init-value=0, base-type=BT_HVLM_DC_Aufstartmodus, compu-method=CM_HVLM_DC_Aufstartmodus, data-constr=DC_HVLM_DC_Aufstartmodus, to BMC_HV(timeout 1 s)  # Aufstartmodus zum Aktivieren des HV-Modus für DC-Laden
          signal HVLM_Ladeszenario_XIX_HVLM_14_XIX_HCP5_CANFD01: start 48, 5 bit, little-endian, data-type-policy=OVERRIDE, i-signal-type=PRIMITIVE, init-value=30, base-type=BT_HVLM_Ladeszenario, invalid-value=Invalid_HVLM_Ladeszenario_XIX_HVLM_14_XIX_HCP5_CANFD01:31, compu-method=CM_HVLM_Ladeszenario, data-constr=DC_HVLM_Ladeszenario  # Über dieses Signal wird das einzustellende Szenario für die Visualisierung gesendet.
          signal HVLM_Ladevorgang_Anf_XIX_HVLM_14_XIX_HCP5_CANFD01: start 53, 3 bit, little-endian, data-type-policy=OVERRIDE, i-signal-type=PRIMITIVE, init-value=0, base-type=BT_HVLM_Ladevorgang_Anf, compu-method=CM_HVLM_Ladevorgang_Anf, data-constr=DC_HVLM_Ladevorgang_Anf  # Art der angeforderten Ladeart 0 = Laden_nicht_angefordert 1 = AC_Laden_Angefordert 2 = DC_Laden_Angefordert 3 = AC_und_DC_Angefordert 4 = Induktiv_Laden_Angef 5 = AC_und_Induktiv_Angef 6 = DC_und_Induktiv_Angef 7 = AC_DC_und_Induktiv_Angef
          signal HVLM_Intensitaet_Lk1_XIX_HVLM_14_XIX_HCP5_CANFD01: start 56, 7 bit, little-endian, data-type-policy=OVERRIDE, i-signal-type=PRIMITIVE, init-value=126, base-type=BT_HVLM_Intensitaet_Lk1, invalid-value=Invalid_HVLM_Intensitaet_Lk1_XIX_HVLM_14_XIX_HCP5_CANFD01:127, compu-method=CM_HVLM_Intensitaet_Lk1, data-constr=DC_HVLM_Intensitaet_Lk1, unit=Unit_Unit_PerCent  # Über dieses Signal wird eine Information über die Beleuchtungsintensität an der LED der Ladeklappe 1 gesendet.
          signal HVLM_Laden_ISO_Messung_Anf_XIX_HVLM_14_XIX_HCP5_CANFD01: start 63, 1 bit, little-endian, data-type-policy=OVERRIDE, i-signal-type=PRIMITIVE, init-value=1, base-type=BT_HVLM_Laden_ISO_Messung_Anf, compu-method=CM_HVLM_Laden_ISO_Messung_Anf, data-constr=DC_HVLM_Laden_ISO_Messung_Anf  # Messung des Isolationswiderstandes des Ladesystems (Fzg und Ladesäule) während des Ladevorganges durch das Fahrzeug 0= Anforderung 1= keine_Anforderung
          mapping SG_HVLM_14_XIX_HCP5_CANFD01: i-signal-group=SG_HVLM_14_XIX_HCP5_CANFD01, transfer-property=TRIGGERED-WITHOUT-REPETITION
      frame ISO_Funktionaler_Req_All_XIX_HCP5_CANFD01: id 0x700, to BMC_HV, frame-length=8, can-addressing-mode=STANDARD, can-frame-rx-behavior=CAN-FD, can-frame-tx-behavior=CAN-FD
        n pdu ISO_Funktionaler_Req_All_XIX_HCP5_CANFD01: length=8
      frame ISOx_Funkt_Req_All_FD_XIX_HCP5_CANFD01: id 0x1C410000, to BMC_HV, frame-length=64, can-addressing-mode=EXTENDED, can-frame-rx-behavior=CAN-FD, can-frame-tx-behavior=CAN-FD
        n pdu ISOx_Funkt_Req_All_FD_XIX_HCP5_CANFD01: length=64
      frame ISOx_Hybrid_01_Req_XIX_HCP5_CANFD01: id 0x17FC007B, to BMC_HV, frame-length=8, can-addressing-mode=EXTENDED, can-frame-rx-behavior=CAN-FD, can-frame-tx-behavior=CAN-FD
        n pdu ISOx_Hybrid_01_Req_XIX_HCP5_CANFD01: length=8
      frame ISOx_Hybrid_01_Req_FD_XIX_HCP5_CANFD01: id 0x1C40007B, to BMC_HV, frame-length=64, can-addressing-mode=EXTENDED, can-frame-rx-behavior=CAN-FD, can-frame-tx-behavior=CAN-FD
        n pdu ISOx_Hybrid_01_Req_FD_XIX_HCP5_CANFD01: length=64
      frame ISOx_Hybrid_01_Resp_XIX_HCP5_CANFD01: id 0x17FE007B, from BMC_HV, frame-length=8, can-addressing-mode=EXTENDED, can-frame-rx-behavior=CAN-FD, can-frame-tx-behavior=CAN-FD
        n pdu ISOx_Hybrid_01_Resp_XIX_HCP5_CANFD01: length=8
      frame ISOx_Hybrid_01_Resp_FD_XIX_HCP5_CANFD01: id 0x1C42007B, from BMC_HV, frame-length=64, can-addressing-mode=EXTENDED, can-frame-rx-behavior=CAN-FD, can-frame-tx-behavior=CAN-FD
        n pdu ISOx_Hybrid_01_Resp_FD_XIX_HCP5_CANFD01: length=64
      frame KN_Hybrid_01_XIX_HCP5_CANFD01: id 0x17F0007B, from BMC_HV, frame-length=16, can-addressing-mode=EXTENDED, can-frame-rx-behavior=CAN-FD, can-frame-tx-behavior=CAN-FD
        pdu KN_Hybrid_01_XIX_HCP5_CANFD01: length=16, transmission-mode-true-timing=cyclic-timing={time-offset=0, time-period=0.5}, unused-bit-pattern=0
          signal Hybrid_01_KompSchutz_XIX_KN_Hybrid_01_XIX_HCP5_CANFD01: start 0, 1 bit, little-endian, data-type-policy=OVERRIDE, i-signal-type=PRIMITIVE, init-value=0, base-type=BT_Hybrid_01_KompSchutz, compu-method=CM_Hybrid_01_KompSchutz, data-constr=DC_Hybrid_01_KompSchutz, transfer-property=PENDING  # Signal wird gesetzt wenn Komponentenschutz (KS) im Steuergerät aktiv ist.
          signal Hybrid_01_Abschaltstufe_XIX_KN_Hybrid_01_XIX_HCP5_CANFD01: start 1, 1 bit, little-endian, data-type-policy=OVERRIDE, i-signal-type=PRIMITIVE, init-value=0, base-type=BT_Hybrid_01_Abschaltstufe, compu-method=CM_Hybrid_01_Abschaltstufe, data-constr=DC_Hybrid_01_Abschaltstufe, transfer-property=PENDING  # Funktionseinschränkung aufgrund aktiver Abschaltstufe
          signal Hybrid_01_Transport_Mode_XIX_KN_Hybrid_01_XIX_HCP5_CANFD01: start 2, 1 bit, little-endian, data-type-policy=OVERRIDE, i-signal-type=PRIMITIVE, init-value=0, base-type=BT_Hybrid_01_Transport_Mode, compu-method=CM_Hybrid_01_Transport_Mode, data-constr=DC_Hybrid_01_Transport_Mode, transfer-property=PENDING  # Funktionseinschränkung aufgrund aktivem Transport Mode und/oder Transport Schutz
          signal Hybrid_01_Nachlauftyp_XIX_KN_Hybrid_01_XIX_HCP5_CANFD01: start 4, 4 bit, little-endian, data-type-policy=OVERRIDE, i-signal-type=PRIMITIVE, init-value=2, base-type=BT_Hybrid_01_Nachlauftyp, compu-method=CM_Hybrid_01_Nachlauftyp, data-constr=DC_Hybrid_01_Nachlauftyp, transfer-property=PENDING  # Abgebildet wird die von der Hardware vorgegebene Möglichkeit, die Kommunikation nach Klemme 15 = AUS aufrecht zu erhalten. Es wird ein Init-Wert gesendet.
          signal Hybrid_01_SNI_10_XIX_KN_Hybrid_01_XIX_HCP5_CANFD01: start 8, 10 bit, little-endian, data-type-policy=OVERRIDE, i-signal-type=PRIMITIVE, init-value=123, base-type=BT_Hybrid_01_SNI_10, compu-method=CM_Hybrid_01_SNI_10, data-constr=DC_Hybrid_01_SNI_10, unit=Unit_Unit_None, transfer-property=PENDING  # Source Node-Identifier (SNI) identifiziert den Sender der NM-Botschaft (Knotenadresse) eindeutig im Fahrzeug
          signal KN_Hybrid_01_ECUKnockOut_XIX_KN_Hybrid_01_XIX_HCP5_CANFD01: start 18, 2 bit, little-endian, data-type-policy=OVERRIDE, i-signal-type=PRIMITIVE, init-value=0, base-type=BT_KN_Hybrid_01_ECUKnockOut, compu-method=CM_KN_Hybrid_01_ECUKnockOut, data-constr=DC_KN_Hybrid_01_ECUKnockOut, transfer-property=PENDING  # Ausgabe des ECUKnockout-Status
          signal KN_Hybrid_01_DiagPfad_V12_XIX_KN_Hybrid_01_XIX_HCP5_CANFD01: start 20, 1 bit, little-endian, data-type-policy=OVERRIDE, i-signal-type=PRIMITIVE, init-value=0, base-type=BT_KN_Hybrid_01_DiagPfad_V12, compu-method=CM_KN_Hybrid_01_DiagPfad_V12, data-constr=DC_KN_Hybrid_01_DiagPfad_V12, transfer-property=PENDING  # Kennzeichnung der Diagnosefaehigkeit des BusInterfaces eines Steuergeraetes (Knoten) Umfang LAH 80127 Bei Nutzung des Signal explizit pro angebundenem BusInterface zu setzen
          signal NM_Hybrid_01_Lokalaktiv_XIX_KN_Hybrid_01_XIX_HCP5_CANFD01: start 21, 1 bit, little-endian, data-type-policy=OVERRIDE, i-signal-type=PRIMITIVE, init-value=0, base-type=BT_NM_Hybrid_01_Lokalaktiv, compu-method=CM_NM_Hybrid_01_Lokalaktiv, data-constr=DC_NM_Hybrid_01_Lokalaktiv, transfer-property=PENDING  # Zeigt an ob das SG nach Klemme15 AUS und nach entsprechender MAX Aktivzeit noch aktiv war.
          signal NM_Hybrid_01_Subsystemaktiv_XIX_KN_Hybrid_01_XIX_HCP5_CANFD01: start 22, 1 bit, little-endian, data-type-policy=OVERRIDE, i-signal-type=PRIMITIVE, init-value=0, base-type=BT_NM_Hybrid_01_Subsystemaktiv, compu-method=CM_NM_Hybrid_01_Subsystemaktiv, data-constr=DC_NM_Hybrid_01_Subsystemaktiv, transfer-property=PENDING  # Zeigt an ob ein Subsystem des SGs nach Klemme15 AUS und nach entsprechender MAX Aktivzeit noch aktiv war
          signal Hybrid_01_KD_Fehler_XIX_KN_Hybrid_01_XIX_HCP5_CANFD01: start 23, 1 bit, little-endian, data-type-policy=OVERRIDE, i-signal-type=PRIMITIVE, init-value=0, base-type=BT_Hybrid_01_KD_Fehler, compu-method=CM_Hybrid_01_KD_Fehler, data-constr=DC_Hybrid_01_KD_Fehler, transfer-property=PENDING  # Bei gesetztem Bit ist mindestens ein Kundendienstfehler eingetragen
          signal KN_Hybrid_01_ECUKnockOutTimer_XIX_KN_Hybrid_01_XIX_HCP5_CANFD01: start 24, 6 bit, little-endian, data-type-policy=OVERRIDE, i-signal-type=PRIMITIVE, init-value=15, base-type=BT_KN_Hybrid_01_ECUKnockOutTimer, compu-method=CM_KN_Hybrid_01_ECUKnockOutTimer, data-constr=DC_KN_Hybrid_01_ECUKnockOutTimer, transfer-property=PENDING  # Ausgabe des ECUKnockOut-Timer
          signal KN_Hybrid_01_BusKnockOut_XIX_KN_Hybrid_01_XIX_HCP5_CANFD01: start 30, 2 bit, little-endian, data-type-policy=OVERRIDE, i-signal-type=PRIMITIVE, init-value=0, base-type=BT_KN_Hybrid_01_BusKnockOut, compu-method=CM_KN_Hybrid_01_BusKnockOut, data-constr=DC_KN_Hybrid_01_BusKnockOut, transfer-property=PENDING  # Ausgabe des BusKnockout-Status
          signal KN_Hybrid_01_BusKnockOutTimer_XIX_KN_Hybrid_01_XIX_HCP5_CANFD01: start 32, 8 bit, little-endian, data-type-policy=OVERRIDE, i-signal-type=PRIMITIVE, init-value=15, base-type=BT_KN_Hybrid_01_BusKnockOutTimer, compu-method=CM_KN_Hybrid_01_BusKnockOutTimer, data-constr=DC_KN_Hybrid_01_BusKnockOutTimer, transfer-property=PENDING  # Ausgabe des BusKnockOut-Timer
          signal NM_Hybrid_01_FCIB_XIX_KN_Hybrid_01_XIX_HCP5_CANFD01: start 40, 56 bit, opaque, data-type-policy=OVERRIDE, i-signal-type=ARRAY, init-value=[1, 0, 0, 34, 128, 0, 0], base-type=BT_NM_Hybrid_01_FCIB, compu-method=CM_NM_Hybrid_01_FCIB, data-constr=DC_NM_Hybrid_01_FCIB, transfer-property=PENDING  # FCIB = Funktions-Cluster-Initialisierungs-Bits
      frame KS_Hybrid_01_Challenge_K_XIX_HCP5_CANFD01: id 0x1A5555D6, from BMC_HV, frame-length=12, can-addressing-mode=EXTENDED, can-frame-rx-behavior=CAN-FD, can-frame-tx-behavior=CAN-FD
        pdu KS_Hybrid_01_Challenge_K_XIX_HCP5_CANFD01: length=12, transmission-mode-true-timing=event-controlled-timing={number-of-repetitions=0, repetition-period=0}, unused-bit-pattern=0
          signal KS_Hybrid_01_ChK_SID_XIX_KS_Hybrid_01_Challenge_K_XIX_HCP5_CANFD01: start 0, 16 bit, little-endian, data-type-policy=OVERRIDE, i-signal-type=PRIMITIVE, init-value=0, base-type=BT_KS_Hybrid_01_ChK_SID, compu-method=CM_KS_Hybrid_01_ChK_SID, data-constr=DC_KS_Hybrid_01_ChK_SID, unit=Unit_Unit_None  # KS: ServiceID Challenge_K
          signal KS_Hybrid_01_ChK_IKACtr_XIX_KS_Hybrid_01_Challenge_K_XIX_HCP5_CANFD01: start 16, 8 bit, little-endian, data-type-policy=OVERRIDE, i-signal-type=PRIMITIVE, init-value=0, base-type=BT_KS_Hybrid_01_ChK_IKACtr, compu-method=CM_KS_Hybrid_01_ChK_IKACtr, data-constr=DC_KS_Hybrid_01_ChK_IKACtr, unit=Unit_Unit_None  # KS: IKA-Counter zur Korrelation der Authentifikation
          signal KS_Hybrid_01_ChK_XIX_KS_Hybrid_01_Challenge_K_XIX_HCP5_CANFD01: start 24, 64 bit, opaque, data-type-policy=OVERRIDE, i-signal-type=ARRAY, init-value=8 x 0, base-type=BT_KS_Hybrid_01_ChK, compu-method=CM_KS_Hybrid_01_ChK, data-constr=DC_KS_Hybrid_01_ChK, unit=Unit_Unit_None  # KS: Challenge/Zufallszahl KS-Slave
          mapping SG_KS_Hybrid_01_Challenge_K_XIX_HCP5_CANFD01: i-signal-group=SG_KS_Hybrid_01_Challenge_K_XIX_HCP5_CANFD01, transfer-property=TRIGGERED-WITHOUT-REPETITION
      frame KS_Hybrid_01_Challenge_M_XIX_HCP5_CANFD01: id 0x1A5555D7, to BMC_HV, frame-length=12, can-addressing-mode=EXTENDED, can-frame-rx-behavior=CAN-FD, can-frame-tx-behavior=CAN-FD
        pdu KS_Hybrid_01_Challenge_M_XIX_HCP5_CANFD01: length=12, transmission-mode-true-timing=event-controlled-timing={number-of-repetitions=0, repetition-period=0}, unused-bit-pattern=0
          signal KS_Hybrid_01_ChM_SID_XIX_KS_Hybrid_01_Challenge_M_XIX_HCP5_CANFD01: start 0, 16 bit, little-endian, data-type-policy=OVERRIDE, i-signal-type=PRIMITIVE, init-value=0, base-type=BT_KS_Hybrid_01_ChM_SID, compu-method=CM_KS_Hybrid_01_ChM_SID, data-constr=DC_KS_Hybrid_01_ChM_SID, unit=Unit_Unit_None, to BMC_HV  # KS: ServiceID Challenge_M
          signal KS_Hybrid_01_ChM_IKACtr_XIX_KS_Hybrid_01_Challenge_M_XIX_HCP5_CANFD01: start 16, 8 bit, little-endian, data-type-policy=OVERRIDE, i-signal-type=PRIMITIVE, init-value=0, base-type=BT_KS_Hybrid_01_ChM_IKACtr, compu-method=CM_KS_Hybrid_01_ChM_IKACtr, data-constr=DC_KS_Hybrid_01_ChM_IKACtr, unit=Unit_Unit_None, to BMC_HV  # KS: IKA-Counter zur Korrelation der Authentifikation
          signal KS_Hybrid_01_ChM_XIX_KS_Hybrid_01_Challenge_M_XIX_HCP5_CANFD01: start 24, 64 bit, opaque, data-type-policy=OVERRIDE, i-signal-type=ARRAY, init-value=8 x 0, base-type=BT_KS_Hybrid_01_ChM, compu-method=CM_KS_Hybrid_01_ChM, data-constr=DC_KS_Hybrid_01_ChM, unit=Unit_Unit_None, to BMC_HV  # KS: Challenge/Zufallszahl KS-Master
          mapping SG_KS_Hybrid_01_Challenge_M_XIX_HCP5_CANFD01: i-signal-group=SG_KS_Hybrid_01_Challenge_M_XIX_HCP5_CANFD01, transfer-property=TRIGGERED-WITHOUT-REPETITION
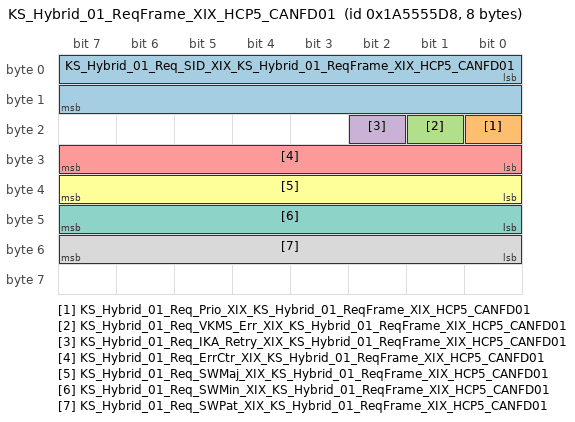
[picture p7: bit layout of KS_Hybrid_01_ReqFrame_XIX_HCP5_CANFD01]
      frame KS_Hybrid_01_ReqFrame_XIX_HCP5_CANFD01: id 0x1A5555D8, from BMC_HV, frame-length=8, can-addressing-mode=EXTENDED, can-frame-rx-behavior=CAN-FD, can-frame-tx-behavior=CAN-FD
        pdu KS_Hybrid_01_ReqFrame_XIX_HCP5_CANFD01: length=8, transmission-mode-true-timing=event-controlled-timing={number-of-repetitions=0, repetition-period=0}, unused-bit-pattern=0
          signal KS_Hybrid_01_Req_SID_XIX_KS_Hybrid_01_ReqFrame_XIX_HCP5_CANFD01: start 0, 16 bit, little-endian, data-type-policy=OVERRIDE, i-signal-type=PRIMITIVE, init-value=0, base-type=BT_KS_Hybrid_01_Req_SID, compu-method=CM_KS_Hybrid_01_Req_SID, data-constr=DC_KS_Hybrid_01_Req_SID, unit=Unit_Unit_None  # KS: ServiceID Anfrage-Frame
          signal KS_Hybrid_01_Req_Prio_XIX_KS_Hybrid_01_ReqFrame_XIX_HCP5_CANFD01: start 16, 1 bit, little-endian, data-type-policy=OVERRIDE, i-signal-type=PRIMITIVE, init-value=0, base-type=BT_KS_Hybrid_01_Req_Prio, compu-method=CM_KS_Hybrid_01_Req_Prio, data-constr=DC_KS_Hybrid_01_Req_Prio  # KS: KS-Slave ist priorisiert
          signal KS_Hybrid_01_Req_VKMS_Err_XIX_KS_Hybrid_01_ReqFrame_XIX_HCP5_CANFD01: start 17, 1 bit, little-endian, data-type-policy=OVERRIDE, i-signal-type=PRIMITIVE, init-value=0, base-type=BT_KS_Hybrid_01_Req_VKMS_Err, compu-method=CM_KS_Hybrid_01_Req_VKMS_Err, data-constr=DC_KS_Hybrid_01_Req_VKMS_Err  # KS: KS-Slave meldet VKMS-Fehler
          signal KS_Hybrid_01_Req_IKA_Retry_XIX_KS_Hybrid_01_ReqFrame_XIX_HCP5_CANFD01: start 18, 1 bit, little-endian, data-type-policy=OVERRIDE, i-signal-type=PRIMITIVE, init-value=0, base-type=BT_KS_Hybrid_01_Req_IKA_Retry, compu-method=CM_KS_Hybrid_01_Req_IKA_Retry, data-constr=DC_KS_Hybrid_01_Req_IKA_Retry  # KS: KS-Slave fordert wiederholte IKS Anfrage an
          signal KS_Hybrid_01_Req_ErrCtr_XIX_KS_Hybrid_01_ReqFrame_XIX_HCP5_CANFD01: start 24, 8 bit, little-endian, data-type-policy=OVERRIDE, i-signal-type=PRIMITIVE, init-value=0, base-type=BT_KS_Hybrid_01_Req_ErrCtr, compu-method=CM_KS_Hybrid_01_Req_ErrCtr, data-constr=DC_KS_Hybrid_01_Req_ErrCtr, unit=Unit_Unit_None  # KS: Wert des KS-ErrorCounter im Secondary
          signal KS_Hybrid_01_Req_SWMaj_XIX_KS_Hybrid_01_ReqFrame_XIX_HCP5_CANFD01: start 32, 8 bit, little-endian, data-type-policy=OVERRIDE, i-signal-type=PRIMITIVE, init-value=0, base-type=BT_KS_Hybrid_01_Req_SWMaj, compu-method=CM_KS_Hybrid_01_Req_SWMaj, data-constr=DC_KS_Hybrid_01_Req_SWMaj, unit=Unit_Unit_None  # KS: SW-Version Major
          signal KS_Hybrid_01_Req_SWMin_XIX_KS_Hybrid_01_ReqFrame_XIX_HCP5_CANFD01: start 40, 8 bit, little-endian, data-type-policy=OVERRIDE, i-signal-type=PRIMITIVE, init-value=0, base-type=BT_KS_Hybrid_01_Req_SWMin, compu-method=CM_KS_Hybrid_01_Req_SWMin, data-constr=DC_KS_Hybrid_01_Req_SWMin, unit=Unit_Unit_None  # KS: SW-Version Minor
          signal KS_Hybrid_01_Req_SWPat_XIX_KS_Hybrid_01_ReqFrame_XIX_HCP5_CANFD01: start 48, 8 bit, little-endian, data-type-policy=OVERRIDE, i-signal-type=PRIMITIVE, init-value=0, base-type=BT_KS_Hybrid_01_Req_SWPat, compu-method=CM_KS_Hybrid_01_Req_SWPat, data-constr=DC_KS_Hybrid_01_Req_SWPat, unit=Unit_Unit_None  # KS: SW-Version Patch
          mapping SG_KS_Hybrid_01_ReqFrame_XIX_HCP5_CANFD01: i-signal-group=SG_KS_Hybrid_01_ReqFrame_XIX_HCP5_CANFD01, transfer-property=TRIGGERED-WITHOUT-REPETITION
      frame KS_Hybrid_01_Response_K_XIX_HCP5_CANFD01: id 0x1A5555D9, from BMC_HV, frame-length=12, can-addressing-mode=EXTENDED, can-frame-rx-behavior=CAN-FD, can-frame-tx-behavior=CAN-FD
        pdu KS_Hybrid_01_Response_K_XIX_HCP5_CANFD01: length=12, transmission-mode-true-timing=event-controlled-timing={number-of-repetitions=0, repetition-period=0}, unused-bit-pattern=0
          signal KS_Hybrid_01_ReK_SID_XIX_KS_Hybrid_01_Response_K_XIX_HCP5_CANFD01: start 0, 16 bit, little-endian, data-type-policy=OVERRIDE, i-signal-type=PRIMITIVE, init-value=0, base-type=BT_KS_Hybrid_01_ReK_SID, compu-method=CM_KS_Hybrid_01_ReK_SID, data-constr=DC_KS_Hybrid_01_ReK_SID, unit=Unit_Unit_None  # KS: ServiceID Response_K
          signal KS_Hybrid_01_ReK_IKACtr_XIX_KS_Hybrid_01_Response_K_XIX_HCP5_CANFD01: start 16, 8 bit, little-endian, data-type-policy=OVERRIDE, i-signal-type=PRIMITIVE, init-value=0, base-type=BT_KS_Hybrid_01_ReK_IKACtr, compu-method=CM_KS_Hybrid_01_ReK_IKACtr, data-constr=DC_KS_Hybrid_01_ReK_IKACtr, unit=Unit_Unit_None  # KS: IKA-Counter zur Korrelation der Authentifikation
          signal KS_Hybrid_01_ReK_XIX_KS_Hybrid_01_Response_K_XIX_HCP5_CANFD01: start 24, 64 bit, opaque, data-type-policy=OVERRIDE, i-signal-type=ARRAY, init-value=8 x 0, base-type=BT_KS_Hybrid_01_ReK, compu-method=CM_KS_Hybrid_01_ReK, data-constr=DC_KS_Hybrid_01_ReK, unit=Unit_Unit_None  # KS: Response KS-Slave Verschluesselung
          mapping SG_KS_Hybrid_01_Response_K_XIX_HCP5_CANFD01: i-signal-group=SG_KS_Hybrid_01_Response_K_XIX_HCP5_CANFD01, transfer-property=TRIGGERED-WITHOUT-REPETITION
      frame KS_Hybrid_01_Response_M_XIX_HCP5_CANFD01: id 0x1A5555DA, to BMC_HV, frame-length=12, can-addressing-mode=EXTENDED, can-frame-rx-behavior=CAN-FD, can-frame-tx-behavior=CAN-FD
        pdu KS_Hybrid_01_Response_M_XIX_HCP5_CANFD01: length=12, transmission-mode-true-timing=event-controlled-timing={number-of-repetitions=0, repetition-period=0}, unused-bit-pattern=0
          signal KS_Hybrid_01_ReM_SID_XIX_KS_Hybrid_01_Response_M_XIX_HCP5_CANFD01: start 0, 16 bit, little-endian, data-type-policy=OVERRIDE, i-signal-type=PRIMITIVE, init-value=0, base-type=BT_KS_Hybrid_01_ReM_SID, compu-method=CM_KS_Hybrid_01_ReM_SID, data-constr=DC_KS_Hybrid_01_ReM_SID, unit=Unit_Unit_None, to BMC_HV  # KS: ServiceID Response_M
          signal KS_Hybrid_01_ReM_IKACtr_XIX_KS_Hybrid_01_Response_M_XIX_HCP5_CANFD01: start 16, 8 bit, little-endian, data-type-policy=OVERRIDE, i-signal-type=PRIMITIVE, init-value=0, base-type=BT_KS_Hybrid_01_ReM_IKACtr, compu-method=CM_KS_Hybrid_01_ReM_IKACtr, data-constr=DC_KS_Hybrid_01_ReM_IKACtr, unit=Unit_Unit_None, to BMC_HV  # KS: IKA-Counter zur Korrelation der Authentifikation
          signal KS_Hybrid_01_ReM_XIX_KS_Hybrid_01_Response_M_XIX_HCP5_CANFD01: start 24, 64 bit, opaque, data-type-policy=OVERRIDE, i-signal-type=ARRAY, init-value=8 x 0, base-type=BT_KS_Hybrid_01_ReM, compu-method=CM_KS_Hybrid_01_ReM, data-constr=DC_KS_Hybrid_01_ReM, unit=Unit_Unit_None, to BMC_HV  # KS: Response KS-Master Verschluesselung
          mapping SG_KS_Hybrid_01_Response_M_XIX_HCP5_CANFD01: i-signal-group=SG_KS_Hybrid_01_Response_M_XIX_HCP5_CANFD01, transfer-property=TRIGGERED-WITHOUT-REPETITION
      frame NM_AWC_XIX_HCP5_CANFD01: id 0x1B00008F, to BMC_HV, frame-length=24, can-addressing-mode=EXTENDED, can-frame-rx-behavior=CAN-FD, can-frame-tx-behavior=CAN-FD, rx-identifier-range={lower-can-id=452984832, upper-can-id=452985855}
        nm pdu NM_AWC_XIX_HCP5_CANFD01: length=24, unused-bit-pattern=0
          signal NM_AWC_CBV_AWB_XIX_NM_AWC_XIX_HCP5_CANFD01: start 4, 1 bit, little-endian, data-type-policy=OVERRIDE, i-signal-type=PRIMITIVE, init-value=0, base-type=BT_NM_AWC_CBV_AWB, compu-method=CM_NM_AWC_CBV_AWB, data-constr=DC_NM_AWC_CBV_AWB, transfer-property=TRIGGERED  # Das Signal ist zu setzen, wenn das SG aktiv den Bus geweckt hat 0 = Passiver_WakeUp = SG hat das Netzwerk nicht aktiv geweckt 1 = Akitiver_WakeUp = SG hat das Netzwerk aktiv geweckt
          signal NM_AWC_CBV_CRI_XIX_NM_AWC_XIX_HCP5_CANFD01: start 6, 1 bit, little-endian, data-type-policy=OVERRIDE, i-signal-type=PRIMITIVE, init-value=1, base-type=BT_NM_AWC_CBV_CRI, compu-method=CM_NM_AWC_CBV_CRI, data-constr=DC_NM_AWC_CBV_CRI, transfer-property=TRIGGERED  # Das Signal ist dauerhaft gesetzt, wenn das NM-Layout Cluster- Anforderungen enthält
          signal NM_AWC_FCAB_XIX_NM_AWC_XIX_HCP5_CANFD01: start 8, 56 bit, opaque, data-type-policy=OVERRIDE, i-signal-type=ARRAY, init-value=7 x 0b00000000, base-type=BT_NM_AWC_FCAB, compu-method=CM_NM_AWC_FCAB, data-constr=DC_NM_AWC_FCAB, transfer-property=TRIGGERED-ON-CHANGE, to BMC_HV(timeout 2 s)  # FCAB = Funktions-Cluster-Aktiv-Bits
          signal NM_AWC_SNI_10_XIX_NM_AWC_XIX_HCP5_CANFD01: start 128, 10 bit, little-endian, data-type-policy=OVERRIDE, i-signal-type=PRIMITIVE, init-value=143, base-type=BT_NM_AWC_SNI_10, compu-method=CM_NM_AWC_SNI_10, data-constr=DC_NM_AWC_SNI_10, transfer-property=TRIGGERED  # Source Node-Identifier (SNI) identifiziert den Sender der NM-Botschaft (Knotenadresse) eindeutig im Fahrzeug
          signal NM_AWC_NM_State_XIX_NM_AWC_XIX_HCP5_CANFD01: start 144, 6 bit, little-endian, data-type-policy=OVERRIDE, i-signal-type=PRIMITIVE, init-value=0, base-type=BT_NM_AWC_NM_State, compu-method=CM_NM_AWC_NM_State, data-constr=DC_NM_AWC_NM_State, transfer-property=TRIGGERED  # 1 = Zustand Repeat Message (<-- Bus-Sleep Mode) 2 = Zustand Repeat Message (<-- Prepare Bus-Sleep Mode) 4 = Zustand Normal Operation (<-- Repeat Message) 8 = Zustand Normal Operation (<-- Ready Sleep)
          signal NM_AWC_UDS_CC_XIX_NM_AWC_XIX_HCP5_CANFD01: start 151, 1 bit, little-endian, data-type-policy=OVERRIDE, i-signal-type=PRIMITIVE, init-value=0, base-type=BT_NM_AWC_UDS_CC, compu-method=CM_NM_AWC_UDS_CC, data-constr=DC_NM_AWC_UDS_CC, transfer-property=TRIGGERED  # Funktionseinschränkung aufgrund aktivem UDS-Communication Control, siehe VW80124
          signal NM_AWC_Wakeup_V12_XIX_NM_AWC_XIX_HCP5_CANFD01: start 152, 8 bit, little-endian, data-type-policy=OVERRIDE, i-signal-type=PRIMITIVE, init-value=0, base-type=BT_NM_AWC_Wakeup_V12, compu-method=CM_NM_AWC_Wakeup_V12, data-constr=DC_NM_AWC_Wakeup_V12, transfer-property=TRIGGERED  # enthält die Weckursache; stehen mehrere Weckursachen parallel an, dann muss der kleinste Wert übertragen werden
          signal NM_AWC_NM_aktiv_KL15_XIX_NM_AWC_XIX_HCP5_CANFD01: start 160, 1 bit, little-endian, data-type-policy=OVERRIDE, i-signal-type=PRIMITIVE, init-value=0, base-type=BT_NM_AWC_NM_aktiv_KL15, compu-method=CM_NM_AWC_NM_aktiv_KL15, data-constr=DC_NM_AWC_NM_aktiv_KL15, transfer-property=TRIGGERED  # Steuergerät hat KL15-EIN erkannt
          signal NM_AWC_NM_aktiv_Diag_XIX_NM_AWC_XIX_HCP5_CANFD01: start 161, 1 bit, little-endian, data-type-policy=OVERRIDE, i-signal-type=PRIMITIVE, init-value=0, base-type=BT_NM_AWC_NM_aktiv_Diag, compu-method=CM_NM_AWC_NM_aktiv_Diag, data-constr=DC_NM_AWC_NM_aktiv_Diag, transfer-property=TRIGGERED  # Diagnose befindet sich nach VW80124 in einer NonDefaultDiagnostic-Session, z.B. ExtendedDiagnostic-Session
          signal NM_AWC_NM_aktiv_Tmin_XIX_NM_AWC_XIX_HCP5_CANFD01: start 162, 1 bit, little-endian, data-type-policy=OVERRIDE, i-signal-type=PRIMITIVE, init-value=0, base-type=BT_NM_AWC_NM_aktiv_Tmin, compu-method=CM_NM_AWC_NM_aktiv_Tmin, data-constr=DC_NM_AWC_NM_aktiv_Tmin, transfer-property=TRIGGERED  # Mindestaktivzeit ist noch nicht abgelaufen (bei jedem Weckereignis wird die Mindestaktivzeit neu gestartet)
          signal NM_aktiv_RequestWirelessCharging_XIX_NM_AWC_XIX_HCP5_CANFD01: start 163, 1 bit, little-endian, data-type-policy=OVERRIDE, i-signal-type=PRIMITIVE, init-value=0, base-type=BT_NM_aktiv_RequestWirelessCharging, compu-method=CM_NM_aktiv_RequestWirelessCharging, data-constr=DC_NM_aktiv_RequestWirelessCharging, transfer-property=TRIGGERED  # Das AWC muss den HVLM wecken um zu sagen, dass es Ladebereit wäre.
